VERSION "created by canmatrix"

NS_ :

BS_:

BU_: DiagTool_OBD1 DiwaNXT EBS IRCS MulticII NBM VCM ETS NODE_45 FCCU DICO SGW2 HV_BOX ADCU AEBS DTCO MBMS SGW TPMS ACU CAID2 ELC5_Fr ELC5_Rr PredictiveVirtualNode2 BPU_3 Servo_dir_Turolla PCM NODE_90 NODE_91 NODE_92 RSRRM FCU DSE_VirtualNode2 DSE_VirtualNode40 DSE_VirtualNode38 DSE_VirtualNode49 DSE_VirtualNode48 DSE_VirtualNode39 DSE_VirtualNode37 DSE_VirtualNode36 BSM_B8 BPU_2 DSE_VirtualNode35 DSE_VirtualNode34 RADAR_ACC DSE_VirtualNode33 DSE_VirtualNode41 NODE_BE DSE_VirtualNode32 DSE_VirtualNode4 BSM_C0 BPU_1 DSE_VirtualNode31 DSE_VirtualNode29 DSE_VirtualNode28 MCDS DSE_VirtualNode44 DSE_VirtualNode27 DSE_VirtualNode26 BSM_C8 ALM DSE_VirtualNode25 DSE_VirtualNode50 DSE_VirtualNode47 DSE_VirtualNode46 DSE_VirtualNode23 DSE_VirtualNode51 ScanTool DSE_VirtualNode22 DSE_VirtualNode21 AePTO DC_VirtualNode1 DSE_VirtualNode43 MCSL DSE_VirtualNode1 DSE_VirtualNode42 PredictiveVirtualNode3 DSE_VirtualNode20 DSE_VirtualNode19 DSE_VirtualNode18 DSE_VirtualNode17 DSE_VirtualNode16 DSE_VirtualNode15 NODE_F9 DiagTool DSE_VirtualNode14 DSE_VirtualNode13 DSE_VirtualNode12 DSE_VirtualNode11 DSE_VirtualNode10 DSE_VirtualNode9 DSE_VirtualNode8 DSE_VirtualNode7 DSE_VirtualNode6 Mirror DSE_VirtualNode5 SAS DC_VirtualNode2 PredictiveVirtualNode1 DSE_VirtualNode45 ELFA3 EM_PTO RM CANAIR SWI

BO_ 2364540032 EEC1_H_80: 8 HV_BOX
 SG_ ActEngPcTrq_0CF00480 : 16|8@1+ (1,-125) [-125|125] "%"  PCM
 SG_ EngSpeed_0CF00480 : 24|16@1+ (0.125,0) [0|8031] "rpm"  PCM

BO_ 2566767127 EEC14_17: 8 MulticII
 SG_ FuelType : 48|8@1+ (1,0) [0|255] ""  PCM

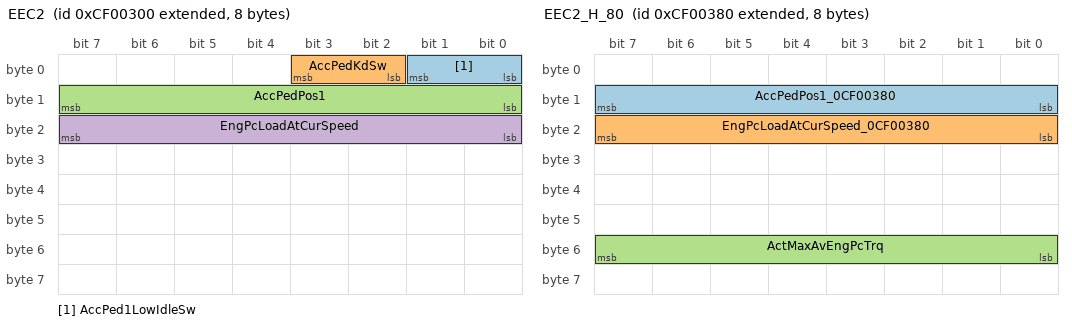
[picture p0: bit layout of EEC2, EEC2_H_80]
BO_ 2364539648 EEC2: 8 DiagTool_OBD1
 SG_ AccPed1LowIdleSw : 0|2@1+ (1,0) [0|3] ""  PCM
 SG_ AccPedKdSw : 2|2@1+ (1,0) [0|3] ""  PCM
 SG_ AccPedPos1 : 8|8@1+ (0.4,0) [0|100] "%"  PCM
 SG_ EngPcLoadAtCurSpeed : 16|8@1+ (1,0) [0|250] "%"  PCM

BO_ 2364539776 EEC2_H_80: 8 HV_BOX
 SG_ AccPedPos1_0CF00380 : 8|8@1+ (0.4,0) [0|100] "%"  PCM
 SG_ EngPcLoadAtCurSpeed_0CF00380 : 16|8@1+ (1,0) [0|250] "%"  PCM
 SG_ ActMaxAvEngPcTrq : 48|8@1+ (0.4,0) [0|100] "%"  PCM

BO_ 2566840064 EEC3: 8 DiagTool_OBD1
 SG_ NomFrictPcTrq : 0|8@1+ (1,-125) [-125|125] "%"  PCM

BO_ 2566840192 EEC3_H: 8 HV_BOX
 SG_ NomFrictPcTrq_18FEDF80 : 0|8@1+ (1,-125) [-125|125] "%"  PCM

BO_ 2566844160 EFLP1: 8 DiagTool_OBD1
 SG_ EngFuelDelPrs : 0|8@1+ (4,0) [0|1000] "kPa"  PCM
 SG_ EngOilPrs1 : 24|8@1+ (4,0) [0|1000] "kPa"  PCM

BO_ 2566885210 ELFASys1_ELFA2: 8 DICO
 SG_ Modefb : 4|4@1+ (1,0) [0|3] ""  PCM

BO_ 2566898290 EmCmd: 8 EM_PTO
 SG_ EngStopSw : 18|2@1+ (1,0) [0|3] ""  PCM

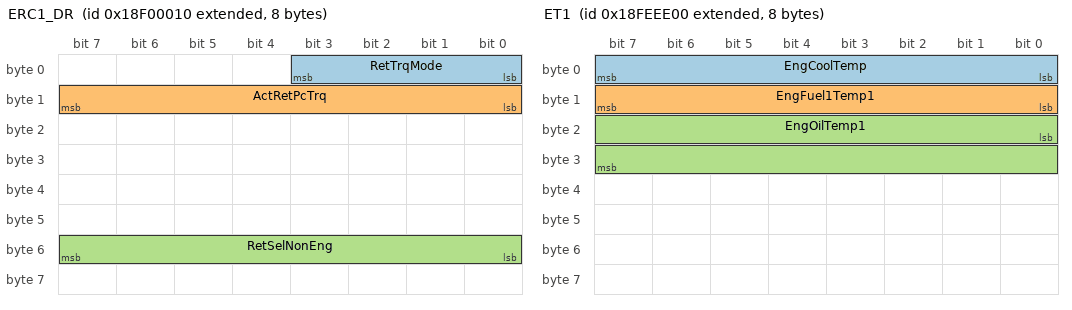
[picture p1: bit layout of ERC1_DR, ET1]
BO_ 2565865488 ERC1_DR: 8 IRCS
 SG_ RetTrqMode : 0|4@1+ (1,0) [0|15] ""  PCM
 SG_ ActRetPcTrq : 8|8@1+ (1,-125) [-125|125] "%"  PCM
 SG_ RetSelNonEng : 48|8@1+ (0.4,0) [0|100] "%"  PCM

BO_ 2565865487 ERC1_ER: 8 RM
 SG_ ActRetPcTrq_18F0000F : 8|8@1+ (1,-125) [-125|125] "%"  PCM

BO_ 2566843904 ET1: 8 DiagTool_OBD1
 SG_ EngCoolTemp : 0|8@1+ (1,-40) [-40|210] "°C"  PCM
 SG_ EngFuel1Temp1 : 8|8@1+ (1,-40) [-40|210] "°C"  PCM
 SG_ EngOilTemp1 : 16|16@1+ (0.03125,-273) [-273|1734] "°C"  PCM

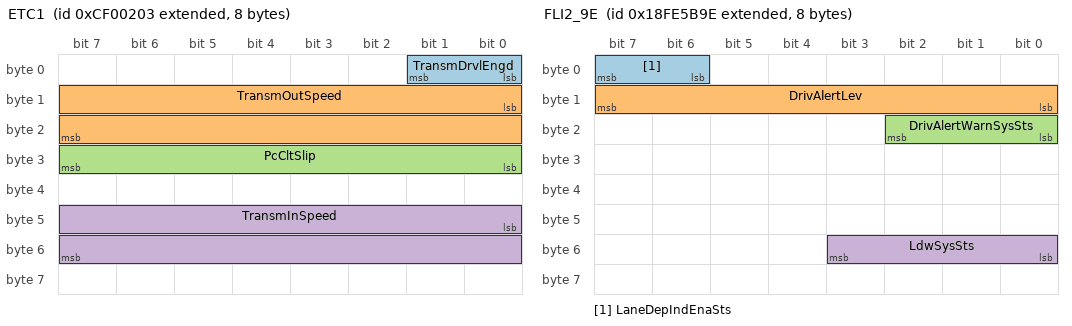
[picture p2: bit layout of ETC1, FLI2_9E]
BO_ 2364539395 ETC1: 8 DiwaNXT
 SG_ TransmDrvlEngd : 0|2@1+ (1,0) [0|3] ""  PCM
 SG_ TransmOutSpeed : 8|16@1+ (0.125,0) [0|8031] "rpm"  PCM
 SG_ PcCltSlip : 24|8@1+ (0.4,0) [0|100] "%"  PCM
 SG_ TransmInSpeed : 40|16@1+ (0.125,0) [0|8031] "rpm"  PCM

BO_ 2565866755 ETC2: 8 DiwaNXT
 SG_ TransmSelGear : 0|8@1+ (1,-125) [-125|125] "gear value"  PCM
 SG_ TransmCurGear : 24|8@1+ (1,-125) [-125|125] "gear value"  PCM

BO_ 2566826755 ETC6_P6: 8 DiwaNXT
 SG_ HighPossGear : 8|8@1+ (1,-125) [-125|125] "gear value"  PCM
 SG_ LowPossGear : 16|8@1+ (1,-125) [-125|125] "gear value"  PCM

BO_ 2364541955 ETC8: 8 DiwaNXT
 SG_ TransmTrqConvRatio : 0|16@1+ (0.001,0) [0|64] ""  PCM

BO_ 2566831393 FD1_21: 8 NBM
 SG_ FanSpeed : 16|16@1+ (0.125,0) [0|8031] "rpm"  PCM

BO_ 2431649694 FLI1_9E: 8 ADCU
 SG_ LaneDepImmRh : 4|2@1+ (1,0) [0|3] ""  PCM
 SG_ LaneDepImmLh : 6|2@1+ (1,0) [0|3] ""  PCM

BO_ 2566806430 FLI2_9E: 8 ADCU
 SG_ LaneDepIndEnaSts : 6|2@1+ (1,0) [0|3] ""  PCM
 SG_ DrivAlertLev : 8|8@1+ (0.4,0) [0|100] "%"  PCM
 SG_ DrivAlertWarnSysSts : 16|3@1+ (1,0) [0|7] ""  PCM
 SG_ LdwSysSts : 48|4@1+ (1,0) [0|15] ""  PCM

BO_ 2566841600 HOURS: 8 DiagTool_OBD1
 SG_ EngTotHrOfOp : 0|32@1+ (0.05,0) [0|210554060] "h"  PCM

BO_ 2566719744 HRLFC: 8 DiagTool_OBD1
 SG_ EngTotFuelUsedHr : 32|32@1+ (0.001,0) [0|4211081] "L"  PCM

BO_ 2566837793 HSI1_21: 8 NBM
 SG_ HybSysPwrElnCoolLevSw : 4|2@1+ (1,0) [0|3] ""  PCM
 SG_ HybSysCoastRegenBrkLevSel : 16|8@1+ (0.4,0) [0|100] "%"  PCM

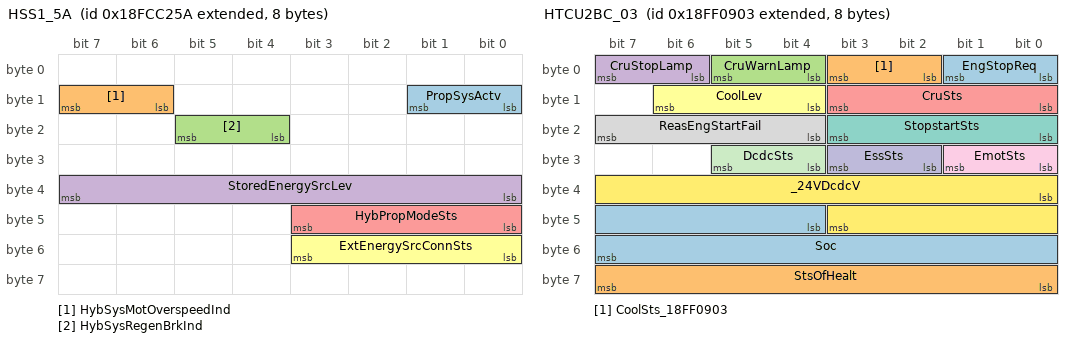
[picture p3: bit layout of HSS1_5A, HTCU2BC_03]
BO_ 2566701658 HSS1_5A: 8 DICO
 SG_ PropSysActv : 8|2@1+ (1,0) [0|3] ""  PCM
 SG_ HybSysMotOverspeedInd : 14|2@1+ (1,0) [0|3] ""  PCM
 SG_ HybSysRegenBrkInd : 20|2@1+ (1,0) [0|3] ""  PCM
 SG_ StoredEnergySrcLev : 32|8@1+ (0.4,0) [0|100] "%"  PCM
 SG_ HybPropModeSts : 40|4@1+ (1,0) [0|15] ""  PCM
 SG_ ExtEnergySrcConnSts : 48|4@1+ (1,0) [0|15] ""  PCM

BO_ 2566698842 HSS2_5A: 8 DICO
 SG_ HybBatRemChg : 0|16@1+ (0.0025,0) [0|160] "%"  PCM
 SG_ HybSysEassRemPc : 16|8@1+ (0.4,0) [0|100] "%"  PCM

BO_ 2566850819 HTCU2BC_03: 8 DiwaNXT
 SG_ EngStopReq : 0|2@1+ (1,0) [0|3] ""  PCM
 SG_ CoolSts_18FF0903 : 2|2@1+ (1,0) [0|3] ""  PCM
 SG_ CruWarnLamp : 4|2@1+ (1,0) [0|3] ""  PCM
 SG_ CruStopLamp : 6|2@1+ (1,0) [0|3] ""  PCM
 SG_ CruSts : 8|4@1+ (1,0) [0|15] "Status"  PCM
 SG_ CoolLev : 12|3@1+ (1,0) [0|7] "Status"  PCM
 SG_ StopstartSts : 16|4@1+ (1,0) [0|15] ""  PCM
 SG_ ReasEngStartFail : 20|4@1+ (1,0) [0|15] ""  PCM
 SG_ EmotSts : 24|2@1+ (1,0) [0|3] ""  PCM
 SG_ EssSts : 26|2@1+ (1,0) [0|3] ""  PCM
 SG_ DcdcSts : 28|2@1+ (1,0) [0|3] "Status"  PCM
 SG_ _24VDcdcV : 32|12@1+ (0.025,0) [0|100] "V"  PCM
 SG_ Soc : 44|12@1+ (0.1,-200) [-200|209] "%"  PCM
 SG_ StsOfHealt : 56|8@1+ (0.5,0) [0|100] "%"  PCM

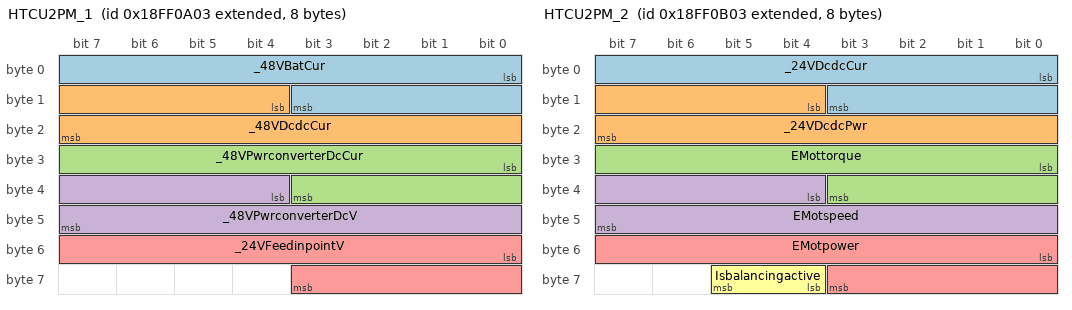
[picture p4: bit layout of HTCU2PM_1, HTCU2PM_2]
BO_ 2566851075 HTCU2PM_1: 8 DiwaNXT
 SG_ _48VBatCur : 0|12@1+ (0.5,-1000) [-1000|1007] "A"  PCM
 SG_ _48VDcdcCur : 12|12@1+ (0.5,-1000) [-1000|1007] "A"  PCM
 SG_ _48VPwrconverterDcCur : 24|12@1+ (0.5,-1000) [-1000|1007] "A"  PCM
 SG_ _48VPwrconverterDcV : 36|12@1+ (0.025,0) [0|100] "V"  PCM
 SG_ _24VFeedinpointV : 48|12@1+ (0.025,0) [0|100] "V"  PCM

BO_ 2566851331 HTCU2PM_2: 8 DiwaNXT
 SG_ _24VDcdcCur : 0|12@1+ (0.5,-1000) [-1000|1007] "A"  PCM
 SG_ _24VDcdcPwr : 12|12@1+ (25,-50000) [-50000|52375] "W"  PCM
 SG_ EMottorque : 24|12@1+ (0.2,-400) [-400|403] "Nm"  PCM
 SG_ EMotspeed : 36|12@1+ (1,-500) [-500|3515] "rpm"  PCM
 SG_ EMotpower : 48|12@1+ (25,-50000) [-50000|52375] "12"  PCM
 SG_ Isbalancingactive : 60|2@1+ (1,0) [0|3] ""  PCM

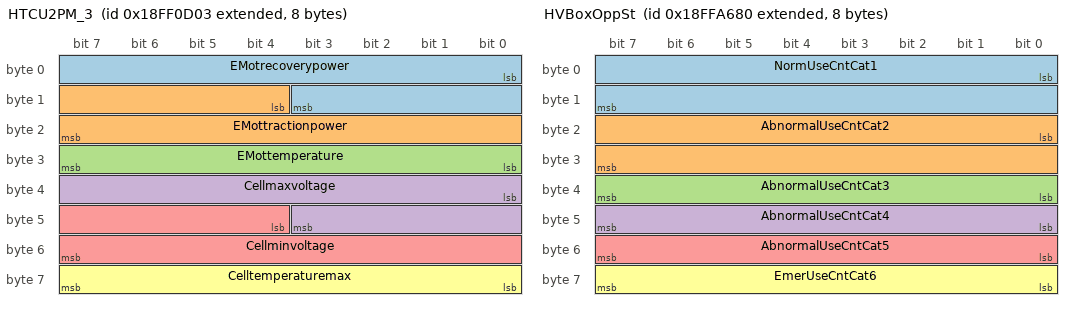
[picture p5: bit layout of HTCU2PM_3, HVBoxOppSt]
BO_ 2566851843 HTCU2PM_3: 8 DiwaNXT
 SG_ EMotrecoverypower : 0|12@1+ (25,-50000) [-50000|52375] "W"  PCM
 SG_ EMottractionpower : 12|12@1+ (25,-50000) [-50000|52375] "W"  PCM
 SG_ EMottemperature : 24|8@1+ (1,-40) [-40|210] "°C"  PCM
 SG_ Cellmaxvoltage : 32|12@1+ (0.002,0) [0|8] "V"  PCM
 SG_ Cellminvoltage : 44|12@1+ (0.002,0) [0|8] "V"  PCM
 SG_ Celltemperaturemax : 56|8@1+ (1,-40) [-40|210] "°C"  PCM

BO_ 2566891136 HVBoxOppSt: 8 HV_BOX
 SG_ NormUseCntCat1 : 0|16@1+ (5,0) [0|321275] "count"  PCM
 SG_ AbnormalUseCntCat2 : 16|16@1+ (2,0) [0|128510] "count"  PCM
 SG_ AbnormalUseCntCat3 : 32|8@1+ (200,0) [0|50000] "count"  PCM
 SG_ AbnormalUseCntCat4 : 40|8@1+ (5,0) [0|1250] "count"  PCM
 SG_ AbnormalUseCntCat5 : 48|8@1+ (1,0) [0|250] "count"  PCM
 SG_ EmerUseCntCat6 : 56|8@1+ (1,0) [0|250] "count"  PCM

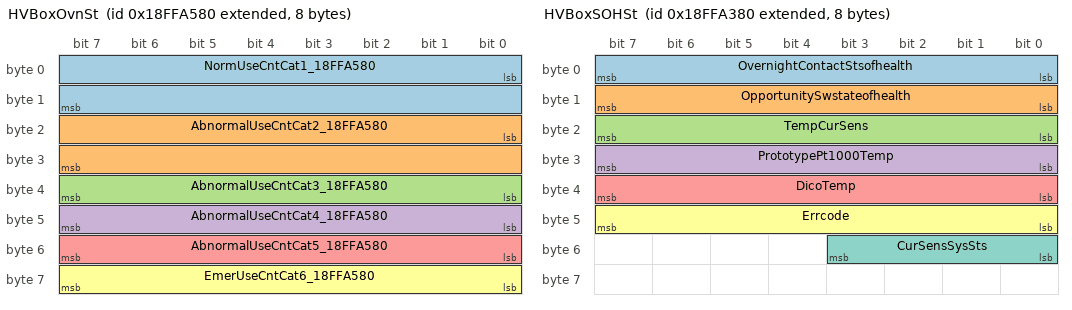
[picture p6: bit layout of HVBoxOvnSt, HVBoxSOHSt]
BO_ 2566890880 HVBoxOvnSt: 8 HV_BOX
 SG_ NormUseCntCat1_18FFA580 : 0|16@1+ (5,0) [0|321275] "count"  PCM
 SG_ AbnormalUseCntCat2_18FFA580 : 16|16@1+ (2,0) [0|128510] "count"  PCM
 SG_ AbnormalUseCntCat3_18FFA580 : 32|8@1+ (200,0) [0|50000] "count"  PCM
 SG_ AbnormalUseCntCat4_18FFA580 : 40|8@1+ (5,0) [0|1250] "count"  PCM
 SG_ AbnormalUseCntCat5_18FFA580 : 48|8@1+ (1,0) [0|250] "count"  PCM
 SG_ EmerUseCntCat6_18FFA580 : 56|8@1+ (1,0) [0|250] "count"  PCM

BO_ 2566890368 HVBoxSOHSt: 8 HV_BOX
 SG_ OvernightContactStsofhealth : 0|8@1+ (0.4,0) [0|100] "%"  PCM
 SG_ OpportunitySwstateofhealth : 8|8@1+ (0.4,0) [0|100] "%"  PCM
 SG_ TempCurSens : 16|8@1+ (1,-40) [-40|80] "° C"  PCM
 SG_ PrototypePt1000Temp : 24|8@1+ (1,-40) [-40|120] "° C"  PCM
 SG_ DicoTemp : 32|8@1+ (1,-40) [-40|120] "° C"  PCM
 SG_ Errcode : 40|8@1+ (1,0) [0|250] ""  PCM
 SG_ CurSensSysSts : 48|4@1+ (1,0) [0|15] ""  PCM

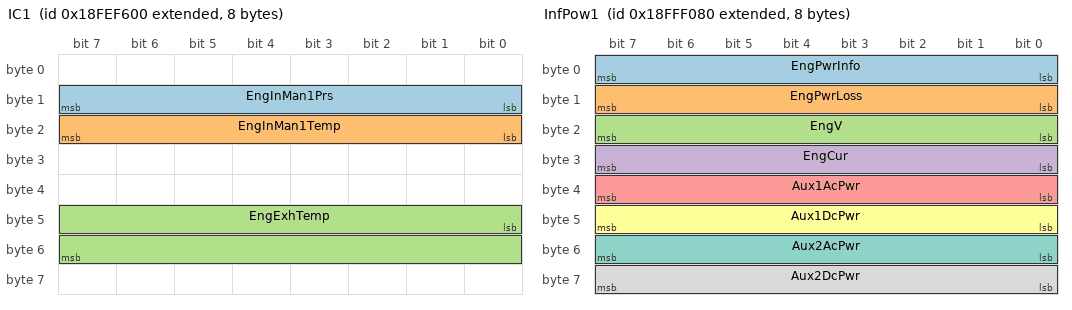
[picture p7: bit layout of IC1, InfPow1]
BO_ 2566845952 IC1: 8 DiagTool_OBD1
 SG_ EngInMan1Prs : 8|8@1+ (2,0) [0|500] "kPa"  PCM
 SG_ EngInMan1Temp : 16|8@1+ (1,-40) [-40|210] "°C"  PCM
 SG_ EngExhTemp : 40|16@1+ (0.03125,-273) [-273|1734] "°C"  PCM

BO_ 2566910080 InfPow1: 8 HV_BOX
 SG_ EngPwrInfo : 0|8@1+ (4,-500) [-500|500] "KW"  PCM
 SG_ EngPwrLoss : 8|8@1+ (0.2,0) [0|50] "KW"  PCM
 SG_ EngV : 16|8@1+ (3.4,0) [0|850] "V"  PCM
 SG_ EngCur : 24|8@1+ (4,-500) [-500|500] "A"  PCM
 SG_ Aux1AcPwr : 32|8@1+ (0.2,0) [0|50] "KW"  PCM
 SG_ Aux1DcPwr : 40|8@1+ (0.2,0) [0|50] "KW"  PCM
 SG_ Aux2AcPwr : 48|8@1+ (0.2,0) [0|50] "KW"  PCM
 SG_ Aux2DcPwr : 56|8@1+ (0.2,0) [0|50] "KW"  PCM

BO_ 2566909824 InfPow2: 8 HV_BOX
 SG_ HighVEnergyChgdTot : 0|32@1+ (0.1,0) [0|199999999] "KWh"  PCM

BO_ 2566786839 LC_17: 8 MulticII
 SG_ LangCodeCmd : 0|16@1+ (1,0) [0|65535] "ASCII"  PCM

BO_ 2566842624 LFC: 8 DiagTool_OBD1
 SG_ EngTotFuelUsed : 32|32@1+ (0.5,0) [0|2105540607] "L"  PCM

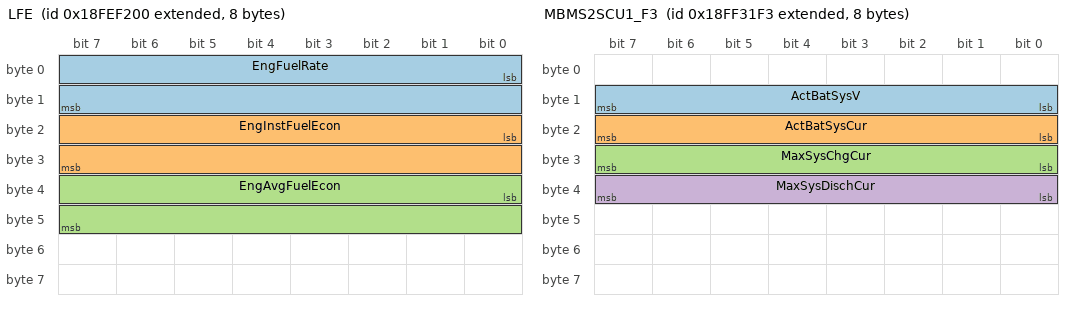
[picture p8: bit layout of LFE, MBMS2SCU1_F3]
BO_ 2566844928 LFE: 8 DiagTool_OBD1
 SG_ EngFuelRate : 0|16@1+ (0.05,0) [0|3212] "L/h"  PCM
 SG_ EngInstFuelEcon : 16|16@1+ (0.001953125,0) [0|125] "km/L"  PCM
 SG_ EngAvgFuelEcon : 32|16@1+ (0.001953125,0) [0|125] "km/L"  PCM

BO_ 2566861299 MBMS2SCU1_F3: 8 MBMS
 SG_ ActBatSysV : 8|8@1+ (3.4,0) [0|850] "V"  PCM
 SG_ ActBatSysCur : 16|8@1+ (4,-500) [-500|500] "A"  PCM
 SG_ MaxSysChgCur : 24|8@1+ (3,0) [0|750] "A"  PCM
 SG_ MaxSysDischCur : 32|8@1+ (3,0) [0|750] "A"  PCM

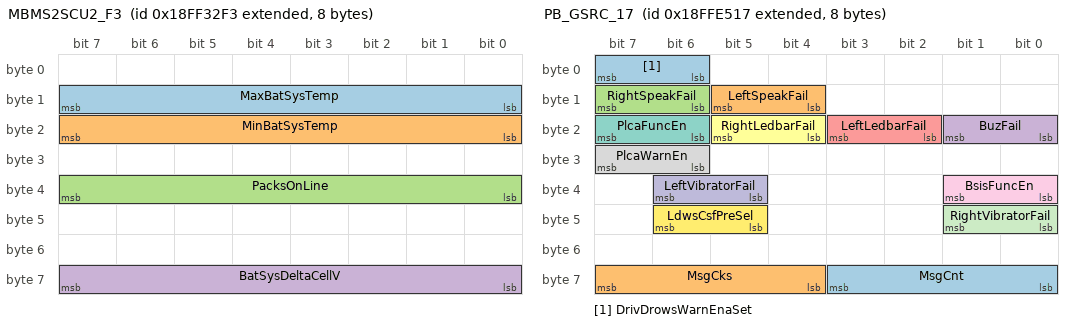
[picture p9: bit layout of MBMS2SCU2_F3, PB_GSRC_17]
BO_ 2566861555 MBMS2SCU2_F3: 8 MBMS
 SG_ MaxBatSysTemp : 8|8@1+ (1,-40) [-40|210] "°C"  PCM
 SG_ MinBatSysTemp : 16|8@1+ (1,-40) [-40|210] "°C"  PCM
 SG_ PacksOnLine : 32|8@1+ (1,0) [0|250] "pack"  PCM
 SG_ BatSysDeltaCellV : 56|8@1+ (10,0) [0|2500] "Mv"  PCM

BO_ 2566776097 MVS_21: 8 NBM
 SG_ MaxVsl1 : 0|8@1+ (1,0) [0|250] "km/h"  PCM
 SG_ AppliedVsl : 56|8@1+ (1,0) [0|250] "km/h"  PCM

BO_ 2365443105 OEL: 8 NBM
 SG_ TurnSigSw : 8|4@1+ (1,0) [0|15] ""  PCM

BO_ 2566769953 OWW_21: 8 NBM
 SG_ FrontOpWiperSw : 4|4@1+ (1,0) [0|15] ""  PCM
 SG_ FrontOpWasherSw : 45|3@1+ (1,0) [0|7] ""  PCM

BO_ 2566908574 PB_AIDI_9E: 8 ADCU
 SG_ DrowsDrivLev : 3|3@1+ (1,0) [0|7] ""  PCM
 SG_ DdawRunMode : 8|3@1+ (1,0) [0|7] ""  PCM

BO_ 2566907159 PB_GSRC_17: 8 MulticII
 SG_ DrivDrowsWarnEnaSet : 6|2@1+ (1,0) [0|3] ""  PCM
 SG_ LeftSpeakFail : 12|2@1+ (1,0) [0|3] ""  PCM
 SG_ RightSpeakFail : 14|2@1+ (1,0) [0|3] ""  PCM
 SG_ BuzFail : 16|2@1+ (1,0) [0|3] ""  PCM
 SG_ LeftLedbarFail : 18|2@1+ (1,0) [0|3] ""  PCM
 SG_ RightLedbarFail : 20|2@1+ (1,0) [0|3] ""  PCM
 SG_ PlcaFuncEn : 22|2@1+ (1,0) [0|3] ""  PCM
 SG_ PlcaWarnEn : 30|2@1+ (1,0) [0|3] ""  PCM
 SG_ BsisFuncEn : 32|2@1+ (1,0) [0|3] ""  PCM
 SG_ LeftVibratorFail : 37|2@1+ (1,0) [0|3] ""  PCM
 SG_ RightVibratorFail : 40|2@1+ (1,0) [0|3] ""  PCM
 SG_ LdwsCsfPreSel : 45|2@1+ (1,0) [0|3] ""  PCM
 SG_ MsgCnt : 56|4@1+ (1,0) [0|15] "count"  PCM
 SG_ MsgCks : 60|4@1+ (1,0) [0|15] "count"  PCM

BO_ 2566894871 PB_ISA_17: 8 MulticII
 SG_ IntlSpeedAssantActv : 8|3@1+ (1,0) [0|7] ""  PCM
 SG_ CntryCode : 22|10@1+ (1,0) [0|1023] ""  PCM

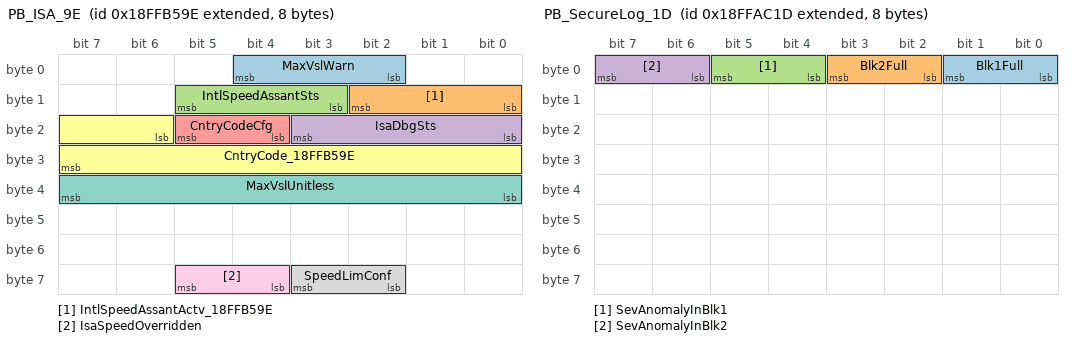
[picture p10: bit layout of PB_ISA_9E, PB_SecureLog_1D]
BO_ 2566895006 PB_ISA_9E: 8 ADCU
 SG_ MaxVslWarn : 2|3@1+ (1,0) [0|3] ""  PCM
 SG_ IntlSpeedAssantActv_18FFB59E : 8|3@1+ (1,0) [0|7] ""  PCM
 SG_ IntlSpeedAssantSts : 11|3@1+ (1,0) [0|7] ""  PCM
 SG_ IsaDbgSts : 16|4@1+ (1,1) [0|15] ""  PCM
 SG_ CntryCodeCfg : 20|2@1+ (1,0) [0|3] ""  PCM
 SG_ CntryCode_18FFB59E : 22|10@1+ (1,0) [0|1023] ""  PCM
 SG_ MaxVslUnitless : 32|8@1+ (1,0) [0|140] ""  PCM
 SG_ SpeedLimConf : 58|2@1+ (1,0) [0|3] ""  PCM
 SG_ IsaSpeedOverridden : 60|2@1+ (1,0) [0|3] ""  PCM

BO_ 2365575713 PB_NmM: 8 NBM
 SG_ IgnOn : 4|2@1+ (1,0) [0|3] ""  PCM

BO_ 2566892573 PB_SecureLog_1D: 8 SGW
 SG_ Blk1Full : 0|2@1+ (1,0) [0|3] ""  PCM
 SG_ Blk2Full : 2|2@1+ (1,0) [0|3] ""  PCM
 SG_ SevAnomalyInBlk1 : 4|2@1+ (1,0) [0|3] ""  PCM
 SG_ SevAnomalyInBlk2 : 6|2@1+ (1,0) [0|3] ""  PCM

BO_ 2566892618 PB_SecureLog_4A: 8 PCM
 SG_ WarnRx : 8|2@1+ (1,0) [0|3] "" Vector__XXX

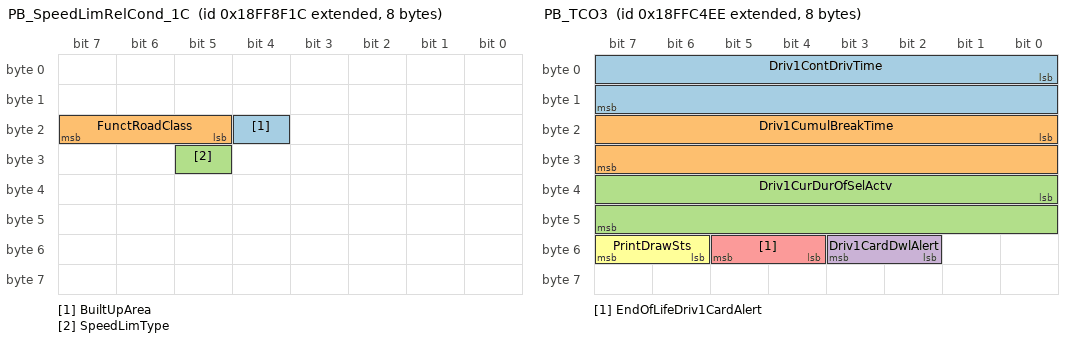
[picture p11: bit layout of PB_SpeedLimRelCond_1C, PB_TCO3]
BO_ 2566885148 PB_SpeedLimRelCond_1C: 8 PCM
 SG_ BuiltUpArea : 20|1@0+ (1,0) [0|1] "" Vector__XXX
 SG_ FunctRoadClass : 23|3@0+ (1,0) [0|7] "" Vector__XXX
 SG_ SpeedLimType : 29|1@0+ (1,0) [0|1] "" Vector__XXX

BO_ 2566898670 PB_TCO2: 21 DTCO
 SG_ Driv1Id_18FFC3EE : 0|8@1+ (1,0) [0|255] "ASCII"  PCM
 SG_ PrefLang : 112|16@1+ (1,0) [0|255] "ASCII"  PCM
 SG_ NextCalDateDay : 128|8@1+ (0.25,0) [0|31] "day"  PCM
 SG_ NextCalDateMonth : 136|8@1+ (1,0) [1|12] "month"  PCM
 SG_ NextCalDateYr : 144|8@1+ (1,1985) [1985|2235] "year"  PCM
 SG_ WFact : 152|16@1+ (0.001,0) [2|25] "pulse/m"  PCM

BO_ 2566898926 PB_TCO3: 8 DTCO
 SG_ Driv1ContDrivTime : 0|16@1+ (1,0) [0|64255] "min"  PCM
 SG_ Driv1CumulBreakTime : 16|16@1+ (1,0) [0|64255] "min"  PCM
 SG_ Driv1CurDurOfSelActv : 32|16@1+ (1,0) [0|64255] "min"  PCM
 SG_ Driv1CardDwlAlert : 50|2@1+ (1,0) [0|3] ""  PCM
 SG_ EndOfLifeDriv1CardAlert : 52|2@1+ (1,0) [0|3] ""  PCM
 SG_ PrintDrawSts : 54|2@1+ (1,0) [0|3] ""  PCM

BO_ 2566899694 PB_TCO4: 44 DTCO
 SG_ TwoWeeksTotDrivTime : 0|16@1+ (1,0) [0|64255] "min"  PCM
 SG_ WeekTotDrivTime : 16|16@1+ (1,0) [0|64255] "min"  PCM
 SG_ DayDrivTime : 32|15@1+ (1,0) [0|31487] "min"  PCM
 SG_ DayDrivTimeFlag : 47|1@1+ (1,0) [0|1] ""  PCM
 SG_ DayDrivTimeShift1 : 48|15@1+ (1,0) [0|31487] "min"  PCM
 SG_ DayDrivTimeShift1Flag : 63|1@1+ (1,0) [0|1] ""  PCM
 SG_ DayDrivTimeShift2 : 64|15@1+ (1,0) [0|31487] "min"  PCM
 SG_ DayDrivTimeShift2Flag : 79|1@1+ (1,0) [0|1] ""  PCM
 SG_ DayDrivTimeShift3 : 80|15@1+ (1,0) [0|31487] "min"  PCM
 SG_ DayDrivTimeShift3Flag : 95|1@1+ (1,0) [0|1] ""  PCM
 SG_ DayDrivTimeShift4 : 96|15@1+ (1,0) [0|31487] "min"  PCM
 SG_ DayDrivTimeShift4Flag : 111|1@1+ (1,0) [0|1] ""  PCM
 SG_ DayDrivTimeShift5 : 112|15@1+ (1,0) [0|31487] "min"  PCM
 SG_ DayDrivTimeShift5Flag : 127|1@1+ (1,0) [0|1] ""  PCM
 SG_ DayDrivTimeShift6 : 128|15@1+ (1,0) [0|31487] "min"  PCM
 SG_ DayDrivTimeShift6Flag : 143|1@1+ (1,0) [0|1] ""  PCM
 SG_ DayRestPer1 : 144|15@1+ (1,0) [0|31487] "min"  PCM
 SG_ DayRestPer1Flag : 159|1@1+ (1,0) [0|1] ""  PCM
 SG_ DayRestPer2 : 160|15@1+ (1,0) [0|31487] "min"  PCM
 SG_ DayRestPer2Flag : 175|1@1+ (1,0) [0|1] ""  PCM
 SG_ DayRestPer3 : 176|15@1+ (1,0) [0|31487] "min"  PCM
 SG_ DayRestPer3Flag : 191|1@1+ (1,0) [0|1] ""  PCM
 SG_ DayRestPer4 : 192|15@1+ (1,0) [0|31487] "min"  PCM
 SG_ DayRestPer4Flag : 207|1@1+ (1,0) [0|1] ""  PCM
 SG_ DayRestPer5 : 208|15@1+ (1,0) [0|31487] "min"  PCM
 SG_ DayRestPer5Flag : 223|1@1+ (1,0) [0|1] ""  PCM
 SG_ DayRestPer6 : 224|15@1+ (1,0) [0|31487] "min"  PCM
 SG_ DayRestPer6Flag : 239|1@1+ (1,0) [0|1] ""  PCM
 SG_ DayRestPer7 : 240|15@1+ (1,0) [0|31487] "min"  PCM
 SG_ DayRestPer7Flag : 255|1@1+ (1,0) [0|1] ""  PCM
 SG_ DayOdo : 256|16@1+ (1,0) [0|64255] "km"  PCM
 SG_ WeekTotOdo : 272|16@1+ (1,0) [0|64255] "km"  PCM
 SG_ TwoWeeksTotOdo : 288|16@1+ (1,0) [0|64255] "km"  PCM
 SG_ DrivCnt : 304|16@1+ (1,0) [0|64255] "min"  PCM
 SG_ WorkCnt : 320|16@1+ (1,0) [0|64255] "min"  PCM
 SG_ AvCnt : 336|16@1+ (1,0) [0|64255] "min"  PCM

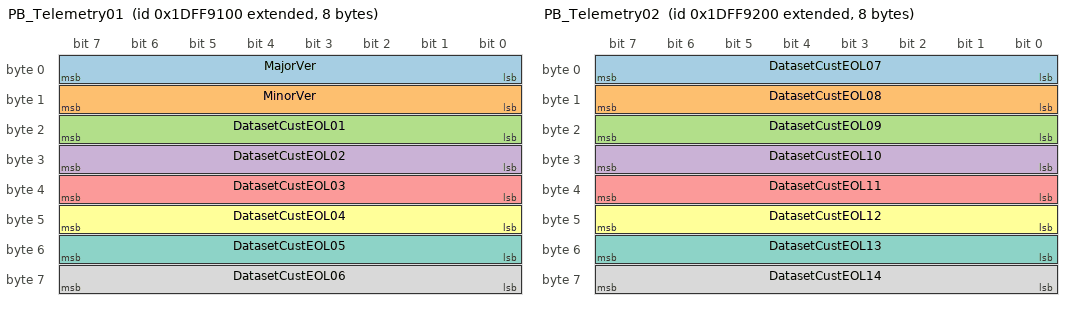
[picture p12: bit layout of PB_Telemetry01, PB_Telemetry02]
BO_ 2650771712 PB_Telemetry01: 8 DiagTool_OBD1
 SG_ MajorVer : 0|8@1+ (1,0) [0|255] ""  PCM
 SG_ MinorVer : 8|8@1+ (1,0) [0|255] ""  PCM
 SG_ DatasetCustEOL01 : 16|8@1+ (1,0) [0|255] ""  PCM
 SG_ DatasetCustEOL02 : 24|8@1+ (1,0) [0|255] ""  PCM
 SG_ DatasetCustEOL03 : 32|8@1+ (1,0) [0|255] ""  PCM
 SG_ DatasetCustEOL04 : 40|8@1+ (1,0) [0|255] ""  PCM
 SG_ DatasetCustEOL05 : 48|8@1+ (1,0) [0|255] ""  PCM
 SG_ DatasetCustEOL06 : 56|8@1+ (1,0) [0|255] ""  PCM

BO_ 2650771968 PB_Telemetry02: 8 DiagTool_OBD1
 SG_ DatasetCustEOL07 : 0|8@1+ (1,0) [0|255] ""  PCM
 SG_ DatasetCustEOL08 : 8|8@1+ (1,0) [0|255] ""  PCM
 SG_ DatasetCustEOL09 : 16|8@1+ (1,0) [0|255] ""  PCM
 SG_ DatasetCustEOL10 : 24|8@1+ (1,0) [0|255] ""  PCM
 SG_ DatasetCustEOL11 : 32|8@1+ (1,0) [0|255] ""  PCM
 SG_ DatasetCustEOL12 : 40|8@1+ (1,0) [0|255] ""  PCM
 SG_ DatasetCustEOL13 : 48|8@1+ (1,0) [0|255] ""  PCM
 SG_ DatasetCustEOL14 : 56|8@1+ (1,0) [0|255] ""  PCM

CM_ BO_ 2364540032 "- Timeout (ms): 50 ms / -
- MC.A.VCU..24..VDB: Only Gx (ELFA2)_
- PCM.Si.DICO....Traction: 10ms in messagerie ELFA2";
CM_ BO_ 2364539648 "- ICE bus only";
CM_ BO_ 2364539776 "- Full elec Siemens only";
CM_ SG_ 2364539776 AccPedPos1_0CF00380 "- UW: recopy of information in EEC2 (0C F0 03 00)";
CM_ BO_ 2566840064 "- Diesel / Gas only";
CM_ BO_ 2566840192 "- Siemens Full elec only. 200ms in messagerie ELFA3 _ 250ms in messagerie BAE.";
CM_ SG_ 2566844160 EngFuelDelPrs "- GAZ only. To be added into VCM4 VDB";
CM_ SG_ 2566844160 EngOilPrs1 "- FEh in case of defective sensor";
CM_ BO_ 2566885210 "- Specific to Siemens Full Elec vehicles. Only Elfa2.";
CM_ BO_ 2566898290 "- CNG and MH only
- MC.W.VCM.4.24..VDB: Transmission rate: ''As Needed''";
CM_ SG_ 2566898290 EngStopSw "- BC.A.BCM..24.UwDG.VDB: Gas: one shot 500ms (NBM)";
CM_ BO_ 2565865488 "-  2 Message Variant(s): Transm.Rates 20, 100
-  Specific to Siemens Full Elec vehicles.
-  Read only, no routing on ECB
-  Transmission Rate [ms] 100";
CM_ SG_ 2565865488 RetSelNonEng "- ETC1.ZF.ETC.Ecolife.2..VDB: Not available 0 value (shift selector not connected to the TCU)";
CM_ BO_ 2565865487 "- 1 message instance, SA=0x0F, 0x29, as selected by calibration (Integration Layer)
-  Routing from ERC1_ER";
CM_ SG_ 2566843904 EngCoolTemp "- FEh in case of defective sensor";
CM_ SG_ 2566843904 EngFuel1Temp1 "- FEh in case of defective sensor";
CM_ SG_ 2566843904 EngOilTemp1 "- FE00h in case of defective sensor";
CM_ SG_ 2364539395 TransmOutSpeed "- MC.A.VCU..24..VDB: Only Gx (ELFA2)";
CM_ SG_ 2364539395 PcCltSlip "- CUC.C.PCM..3..TELEM: Optional";
CM_ SG_ 2364539395 TransmInSpeed "- CUC.C.PCM..3..TELEM: Optional";
CM_ BO_ 2565866755 "- All Powertrain except manual transmission.
-  Full elec: J1939 codification, but only D/N/R and +1/0/-1 are used as there is no gearBox).
-  Multi-PG association valid when VCM is the sender of the message. Transmitted when no ETC, received otherwise
- IC1.A.IC.MulticS.24.CwFE.VDB: Update in according with ''OPL_Supermap'' request (line 50).";
CM_ SG_ 2565866755 TransmSelGear "- Negative values are reverse gears, positive values are forward gears, zero is neutral. 251(0xFB) is park
- MC.A.VCU..24..VDB: Only Gx (ELFA2)";
CM_ SG_ 2565866755 TransmCurGear "- Negative values are reverse gears, positive values are forward gears, zero is neutral. 251(0xFB) is park";
CM_ BO_ 2566826755 "- Only with manual transmission. SAE recommanded priority=7";
CM_ SG_ 2566826755 HighPossGear "- At least 3 gears above the maximum possible to indicate Splitter High, 0xFF otherwise";
CM_ SG_ 2566826755 LowPossGear "- At least 3 gears below the maximum possible to indicate Splitter Low, 0xFF otherwise";
CM_ BO_ 2364541955 "- 100ms in case torque converter locked_ 20ms otherwise";
CM_ BO_ 2566831393 "- Only on UW Diesel CNG";
CM_ BO_ 2431649694 "- Fastest transmission rate 50ms when requested / not send when not requested
-  Transmitted when Lane Departure is active and at least once afterwards.";
CM_ BO_ 2566841600 "- All engines available, even if SA=00.
-  Cyclic Transmission Rate as result of PGN requests
-  SGW requests this PGN with RQST_1D_00
- VS2.B.SGW2..23..VDB: Used in freeze frames parameters.";
CM_ BO_ 2566719744 "- Accumulated amount of fuel used during vehicle operation.";
CM_ BO_ 2566837793 "- Specific to Siemens Full Elec vehicles";
CM_ SG_ 2566837793 HybSysCoastRegenBrkLevSel "- Signal name Intercity file: Hybrid System Handlever Retarder";
CM_ BO_ 2566701658 "- Specific to Siemens Full Elec vehicles.
-  Transmision: Now 100ms, previously 1000ms, 100ms on change";
CM_ BO_ 2566698842 "- Specific to Siemens Full Elec vehicles";
CM_ SG_ 2566698842 HybBatRemChg "- Indicates the hybrid battery pack remaining charge. 0% means no charge remaining, 100% means full charge remaining. 0.0025 %/bit _ offset 0 _ 0 to 160.6375 %.";
CM_ BO_ 2566850819 "- Related to Voith Mild Hybrid project";
CM_ BO_ 2566851075 "- Related to Voith Mild Hybrid project
- CUC.C.PCM..3..TELEM: - Predisposal";
CM_ BO_ 2566851331 "- Related to Voith Mild Hybrid project
-  UW Mild Hybrid only";
CM_ BO_ 2566851843 "- Related to Voith Mild Hybrid project";
CM_ BO_ 2566891136 "- Specific to Siemens Full Elec vehicles";
CM_ BO_ 2566890880 "- Specific to Siemens Full Elec vehicles";
CM_ BO_ 2566890368 "- Specific to Siemens Full Elec vehicles. PCM Traction: in according with VCU file";
CM_ SG_ 2566890368 Errcode "- On event: in case of change of the errorCode the message will be send out acyclic.";
CM_ SG_ 2566845952 EngInMan1Prs "- FEh in case of defective sensor";
CM_ SG_ 2566845952 EngInMan1Temp "- FEh in case of defective sensor";
CM_ SG_ 2566845952 EngExhTemp "- FE00h in case of defective sensor";
CM_ BO_ 2566910080 "- Specific to Siemens Full Elec vehicles";
CM_ BO_ 2566909824 "- Specific to Siemens Full Elec vehicles. Predisposal";
CM_ SG_ 2566909824 HighVEnergyChgdTot "- Total energy charged in the high voltage batteries in the vehicle life time";
CM_ SG_ 2566786839 LangCodeCmd "- Uses the 2-character string country codes in ISO 639.";
CM_ BO_ 2566842624 "- All engines sauf Full elec. CAN Engine: Only ''On Request''. Others Cyclic Transmission Rate as result of PGN requests";
CM_ BO_ 2566844928 "- All engines, without Full elec";
CM_ SG_ 2566844928 EngAvgFuelEcon "- Not emitted with C9 CNG";
CM_ BO_ 2566861299 "- Specific to Siemens Full Elec vehicles.
- CLC1.Tk.ACM....VDB: Filled in according with Intercity file";
CM_ BO_ 2566861555 "- Specific to Siemens Full Elec vehicles";
CM_ BO_ 2566776097 "- Specific to Siemens Full Elec vehicles (CW, Gx).";
CM_ BO_ 2365443105 "- ADC.ZF.ADCU..24..VDB: Transmission rate may differ: ADCU VDB: 1000/On change";
CM_ BO_ 2566908574 "- Bus load periodic : 0.13";
CM_ SG_ 2566895006 MaxVslUnitless "- SPN Position Changed";
CM_ SG_ 2566895006 SpeedLimConf "- Only CW
-  SPN Position Changed.";
CM_ BO_ 2566892573 "- Sent 10 times each 2 seconds. SGW will stop the transmission when PB_SecureLog_4A is received";
CM_ BO_ 2566885148 "- Fonction ISA (ADCU requested)";
CM_ BO_ 2566898670 "- Multipacket message handled by SAE Transport Protocol (J1939/21, par 5.10, Multipacket Broadcast with TP.CM/BAM, TP.DT)
-  Update filled in acc with DTCO4.1 (New file).";
CM_ SG_ 2566898670 Driv1Id_18FFC3EE "- Signal length 112 bits (14 ASCII chars)";
CM_ BO_ 2566898926 "- Update filled in acc with DTCO4.1 (New file).";
CM_ SG_ 2566898926 Driv1CardDwlAlert "- Driver1 - additional information";
CM_ SG_ 2566898926 EndOfLifeDriv1CardAlert "- Driver1 - additional information";
CM_ SG_ 2566898926 PrintDrawSts "- Driver1 - additional information";
CM_ BO_ 2566899694 "- Update filled in acc with DTCO4.1 (New file).";
CM_ SG_ 2566899694 DayDrivTimeFlag "- 1b also when the info is Not Available";
CM_ SG_ 2566899694 DayDrivTimeShift1Flag "- 1b also when the info is Not Available";
CM_ SG_ 2566899694 DayDrivTimeShift2Flag "- 1b also when the info is Not Available";
CM_ SG_ 2566899694 DayDrivTimeShift3Flag "- 1b also when the info is Not Available";
CM_ SG_ 2566899694 DayDrivTimeShift4Flag "- 1b also when the info is Not Available";
CM_ SG_ 2566899694 DayDrivTimeShift5Flag "- 1b also when the info is Not Available";
CM_ SG_ 2566899694 DayDrivTimeShift6Flag "- 1b also when the info is Not Available";
CM_ SG_ 2566899694 DayRestPer1Flag "- 1b also when the info is Not Available";
CM_ SG_ 2566899694 DayRestPer2Flag "- 1b also when the info is Not Available";
CM_ SG_ 2566899694 DayRestPer3Flag "- 1b also when the info is Not Available";
CM_ SG_ 2566899694 DayRestPer4Flag "- 1b also when the info is Not Available";
CM_ SG_ 2566899694 DayRestPer5Flag "- 1b also when the info is Not Available";
CM_ SG_ 2566899694 DayRestPer6Flag "- 1b also when the info is Not Available";
CM_ SG_ 2566899694 DayRestPer7Flag "- 1b also when the info is Not Available";
CM_ SG_ 2566899694 DayOdo "- Currently not used";
CM_ SG_ 2566899694 WeekTotOdo "- Currently not used";
CM_ SG_ 2566899694 TwoWeeksTotOdo "- Currently not used";
CM_ SG_ 2566899694 DrivCnt "- Currently not used";
CM_ SG_ 2566899694 WorkCnt "- Currently not used";
CM_ SG_ 2566899694 AvCnt "- Currently not used";
BA_DEF_ BO_  "CI_MsgDefinition" STRING ;
BA_DEF_ BO_  "CI_MsgId" INT 0 2147483647;
BA_DEF_ BO_  "CI_MsgName" STRING ;
BA_DEF_ BO_  "GenMsgCycleTime" INT 0 3600000;
BA_DEF_ BO_  "GenMsgCycleTimeFast" INT 0 3600000;
BA_DEF_ BO_  "GenMsgDelayTime" INT 0 3600000;
BA_DEF_ BO_  "GenMsgILSupport" ENUM  "No","Yes";
BA_DEF_ BO_  "GenMsgNrOfRepetition" INT 0 1000000;
BA_DEF_ BO_  "GenMsgRequestable" INT 0 1;
BA_DEF_ BO_  "GenMsgSendType" ENUM  "cyclic","NotUsed","NotUsed","NotUsed","NotUsed","NotUsed","NotUsed","IfActive","noMsgSendType";
BA_DEF_ BO_  "GenMsgStartDelayTime" INT 0 100000;
BA_DEF_ BO_  "J1939PgAppearanceOnBus" ENUM  "Default","CAN_Extended","CANFD_Extended";
BA_DEF_ BO_  "TpJ1939VarDlc" ENUM  "No","Yes";
BA_DEF_ BO_  "VFrameFormat" ENUM  "StandardCAN","ExtendedCAN","reserved","J1939PG";
BA_DEF_ SG_  "CI_ParId" STRING ;
BA_DEF_ SG_  "CI_SigId" INT 0 2147483647;
BA_DEF_ SG_  "CI_SigName" STRING ;
BA_DEF_ SG_  "GenSigEVName" STRING ;
BA_DEF_ SG_  "GenSigILSupport" ENUM  "No","Yes";
BA_DEF_ SG_  "GenSigInactiveValue" INT 0 2147483647;
BA_DEF_ SG_  "GenSigSendType" ENUM  "Cyclic","OnWrite","OnWriteWithRepetition","OnChange","OnChangeWithRepetition","IfActive","IfActiveWithRepetition","NoSigSendType";
BA_DEF_ SG_  "GenSigStartValue" INT 0 2147483647;
BA_DEF_ SG_  "GenSigTimeoutTime_ACU" INT 0 3600000;
BA_DEF_ SG_  "GenSigTimeoutTime_ADCU" INT 0 3600000;
BA_DEF_ SG_  "GenSigTimeoutTime_CAID" INT 0 3600000;
BA_DEF_ SG_  "GenSigTimeoutTime_CANAIR" INT 0 3600000;
BA_DEF_ SG_  "GenSigTimeoutTime_DICO" INT 0 3600000;
BA_DEF_ SG_  "GenSigTimeoutTime_DTCO" INT 0 3600000;
BA_DEF_ SG_  "GenSigTimeoutTime_DiwaNXT" INT 0 3600000;
BA_DEF_ SG_  "GenSigTimeoutTime_DiwaNXT_MH" INT 0 3600000;
BA_DEF_ SG_  "GenSigTimeoutTime_EBS" INT 0 3600000;
BA_DEF_ SG_  "GenSigTimeoutTime_EBS_" INT 0 3600000;
BA_DEF_ SG_  "GenSigTimeoutTime_EBS__" INT 0 3600000;
BA_DEF_ SG_  "GenSigTimeoutTime_EBS___" INT 0 3600000;
BA_DEF_ SG_  "GenSigTimeoutTime_ELC5_Fr" INT 0 3600000;
BA_DEF_ SG_  "GenSigTimeoutTime_ELFA3" INT 0 3600000;
BA_DEF_ SG_  "GenSigTimeoutTime_ETS" INT 0 3600000;
BA_DEF_ SG_  "GenSigTimeoutTime_Ecolife2" INT 0 3600000;
BA_DEF_ SG_  "GenSigTimeoutTime_FCCU_" INT 0 3600000;
BA_DEF_ SG_  "GenSigTimeoutTime_FMS4" INT 0 3600000;
BA_DEF_ SG_  "GenSigTimeoutTime_HV_BOX" INT 0 3600000;
BA_DEF_ SG_  "GenSigTimeoutTime_INTD" INT 0 3600000;
BA_DEF_ SG_  "GenSigTimeoutTime_IRCS" INT 0 3600000;
BA_DEF_ SG_  "GenSigTimeoutTime_MD1_D" INT 0 3600000;
BA_DEF_ SG_  "GenSigTimeoutTime_MD1_G" INT 0 3600000;
BA_DEF_ SG_  "GenSigTimeoutTime_MTCO" INT 0 3600000;
BA_DEF_ SG_  "GenSigTimeoutTime_MulticII" INT 0 3600000;
BA_DEF_ SG_  "GenSigTimeoutTime_MulticS" INT 0 3600000;
BA_DEF_ SG_  "GenSigTimeoutTime_MulticS_" INT 0 3600000;
BA_DEF_ SG_  "GenSigTimeoutTime_MulticS__" INT 0 3600000;
BA_DEF_ SG_  "GenSigTimeoutTime_NBM" INT 0 3600000;
BA_DEF_ SG_  "GenSigTimeoutTime_NBM_" INT 0 3600000;
BA_DEF_ SG_  "GenSigTimeoutTime_NBM__" INT 0 3600000;
BA_DEF_ SG_  "GenSigTimeoutTime_NBM___" INT 0 3600000;
BA_DEF_ SG_  "GenSigTimeoutTime_PCM" INT 0 3600000;
BA_DEF_ SG_  "GenSigTimeoutTime_SGW" INT 0 3600000;
BA_DEF_ SG_  "GenSigTimeoutTime_SGW2" INT 0 3600000;
BA_DEF_ SG_  "GenSigTimeoutTime_SGW_" INT 0 3600000;
BA_DEF_ SG_  "GenSigTimeoutTime_SGW__" INT 0 3600000;
BA_DEF_ SG_  "GenSigTimeoutTime_SIU" INT 0 3600000;
BA_DEF_ SG_  "GenSigTimeoutTime_SmartRadio" INT 0 3600000;
BA_DEF_ SG_  "GenSigTimeoutTime_TPMS" INT 0 3600000;
BA_DEF_ SG_  "GenSigTimeoutTime_TSU" INT 0 3600000;
BA_DEF_ SG_  "GenSigTimeoutTime_VCM" INT 0 3600000;
BA_DEF_ SG_  "GenSigTimeoutTime_VCM_" INT 0 3600000;
BA_DEF_ SG_  "GenSigTimeoutTime_VCM__" INT 0 3600000;
BA_DEF_ SG_  "GenSigTimeoutTime_VCU" INT 0 3600000;
BA_DEF_ SG_  "GenSigTimeoutTime_VCU_" INT 0 3600000;
BA_DEF_ SG_  "GenSigTimeoutTime_VMU" INT 0 3600000;
BA_DEF_ SG_  "SPN" INT 0 524287;
BA_DEF_ SG_  "SigType" ENUM  "Default","Range","RangeSigned","ASCII","Discrete","Control","ReferencePGN","DTC","StringDelimiter","StringLength","StringLengthControl";
BA_DEF_DEF_  "CI_MsgDefinition" "";
BA_DEF_DEF_  "CI_MsgId" 0;
BA_DEF_DEF_  "CI_MsgName" "";
BA_DEF_DEF_  "GenMsgCycleTime" 0;
BA_DEF_DEF_  "GenMsgCycleTimeFast" 0;
BA_DEF_DEF_  "GenMsgDelayTime" 1;
BA_DEF_DEF_  "GenMsgILSupport" "Yes";
BA_DEF_DEF_  "GenMsgNrOfRepetition" 0;
BA_DEF_DEF_  "GenMsgRequestable" 0;
BA_DEF_DEF_  "GenMsgSendType" "noMsgSendType";
BA_DEF_DEF_  "GenMsgStartDelayTime" 0;
BA_DEF_DEF_  "J1939PgAppearanceOnBus" "Default";
BA_DEF_DEF_  "TpJ1939VarDlc" "No";
BA_DEF_DEF_  "VFrameFormat" "J1939PG";
BA_DEF_DEF_  "CI_ParId" "";
BA_DEF_DEF_  "CI_SigId" 0;
BA_DEF_DEF_  "CI_SigName" "";
BA_DEF_DEF_  "GenSigEVName" "Env@Nodename_@Signame";
BA_DEF_DEF_  "GenSigILSupport" "Yes";
BA_DEF_DEF_  "GenSigInactiveValue" 0;
BA_DEF_DEF_  "GenSigSendType" "NoSigSendType";
BA_DEF_DEF_  "GenSigStartValue" 0;
BA_DEF_DEF_  "GenSigTimeoutTime_ACU" 0;
BA_DEF_DEF_  "GenSigTimeoutTime_ADCU" 0;
BA_DEF_DEF_  "GenSigTimeoutTime_CAID" 0;
BA_DEF_DEF_  "GenSigTimeoutTime_CANAIR" 0;
BA_DEF_DEF_  "GenSigTimeoutTime_DICO" 0;
BA_DEF_DEF_  "GenSigTimeoutTime_DTCO" 0;
BA_DEF_DEF_  "GenSigTimeoutTime_DiwaNXT" 0;
BA_DEF_DEF_  "GenSigTimeoutTime_DiwaNXT_MH" 0;
BA_DEF_DEF_  "GenSigTimeoutTime_EBS" 0;
BA_DEF_DEF_  "GenSigTimeoutTime_EBS_" 0;
BA_DEF_DEF_  "GenSigTimeoutTime_EBS__" 0;
BA_DEF_DEF_  "GenSigTimeoutTime_EBS___" 0;
BA_DEF_DEF_  "GenSigTimeoutTime_ELC5_Fr" 0;
BA_DEF_DEF_  "GenSigTimeoutTime_ELFA3" 0;
BA_DEF_DEF_  "GenSigTimeoutTime_ETS" 0;
BA_DEF_DEF_  "GenSigTimeoutTime_Ecolife2" 0;
BA_DEF_DEF_  "GenSigTimeoutTime_FCCU_" 0;
BA_DEF_DEF_  "GenSigTimeoutTime_FMS4" 0;
BA_DEF_DEF_  "GenSigTimeoutTime_HV_BOX" 0;
BA_DEF_DEF_  "GenSigTimeoutTime_INTD" 0;
BA_DEF_DEF_  "GenSigTimeoutTime_IRCS" 0;
BA_DEF_DEF_  "GenSigTimeoutTime_MD1_D" 0;
BA_DEF_DEF_  "GenSigTimeoutTime_MD1_G" 0;
BA_DEF_DEF_  "GenSigTimeoutTime_MTCO" 0;
BA_DEF_DEF_  "GenSigTimeoutTime_MulticII" 0;
BA_DEF_DEF_  "GenSigTimeoutTime_MulticS" 0;
BA_DEF_DEF_  "GenSigTimeoutTime_MulticS_" 0;
BA_DEF_DEF_  "GenSigTimeoutTime_MulticS__" 0;
BA_DEF_DEF_  "GenSigTimeoutTime_NBM" 0;
BA_DEF_DEF_  "GenSigTimeoutTime_NBM_" 0;
BA_DEF_DEF_  "GenSigTimeoutTime_NBM__" 0;
BA_DEF_DEF_  "GenSigTimeoutTime_NBM___" 0;
BA_DEF_DEF_  "GenSigTimeoutTime_PCM" 0;
BA_DEF_DEF_  "GenSigTimeoutTime_SGW" 0;
BA_DEF_DEF_  "GenSigTimeoutTime_SGW2" 0;
BA_DEF_DEF_  "GenSigTimeoutTime_SGW_" 0;
BA_DEF_DEF_  "GenSigTimeoutTime_SGW__" 0;
BA_DEF_DEF_  "GenSigTimeoutTime_SIU" 0;
BA_DEF_DEF_  "GenSigTimeoutTime_SmartRadio" 0;
BA_DEF_DEF_  "GenSigTimeoutTime_TPMS" 0;
BA_DEF_DEF_  "GenSigTimeoutTime_TSU" 0;
BA_DEF_DEF_  "GenSigTimeoutTime_VCM" 0;
BA_DEF_DEF_  "GenSigTimeoutTime_VCM_" 0;
BA_DEF_DEF_  "GenSigTimeoutTime_VCM__" 0;
BA_DEF_DEF_  "GenSigTimeoutTime_VCU" 0;
BA_DEF_DEF_  "GenSigTimeoutTime_VCU_" 0;
BA_DEF_DEF_  "GenSigTimeoutTime_VMU" 0;
BA_DEF_DEF_  "SPN" 0;
BA_DEF_DEF_  "SigType" "Default";
BA_ "CI_MsgDefinition" BO_ 2364540032 "J1939DA";
BA_ "CI_MsgId" BO_ 2364540032 855;
BA_ "CI_MsgName" BO_ 2364540032 "EEC1_H_80 - Electronic Engine Controller 1";
BA_ "GenMsgCycleTime" BO_ 2364540032 10;
BA_ "GenMsgCycleTimeFast" BO_ 2364540032 10;
BA_ "GenMsgDelayTime" BO_ 2364540032 5;
BA_ "GenMsgSendType" BO_ 2364540032 0;
BA_ "GenMsgStartDelayTime" BO_ 2364540032 2;
BA_ "CI_MsgDefinition" BO_ 2566767127 "J1939DA";
BA_ "CI_MsgId" BO_ 2566767127 959;
BA_ "CI_MsgName" BO_ 2566767127 "EEC14_17 - Engine Configuration";
BA_ "GenMsgCycleTime" BO_ 2566767127 10000;
BA_ "GenMsgCycleTimeFast" BO_ 2566767127 10000;
BA_ "GenMsgDelayTime" BO_ 2566767127 5000;
BA_ "GenMsgSendType" BO_ 2566767127 0;
BA_ "GenMsgStartDelayTime" BO_ 2566767127 90;
BA_ "CI_MsgDefinition" BO_ 2364539648 "J1939DA";
BA_ "CI_MsgId" BO_ 2364539648 863;
BA_ "CI_MsgName" BO_ 2364539648 "EEC2 - Electronic Engine Controller 2";
BA_ "GenMsgCycleTime" BO_ 2364539648 50;
BA_ "GenMsgCycleTimeFast" BO_ 2364539648 50;
BA_ "GenMsgDelayTime" BO_ 2364539648 25;
BA_ "GenMsgSendType" BO_ 2364539648 0;
BA_ "GenMsgStartDelayTime" BO_ 2364539648 6;
BA_ "CI_MsgDefinition" BO_ 2364539776 "J1939DA";
BA_ "CI_MsgId" BO_ 2364539776 878;
BA_ "CI_MsgName" BO_ 2364539776 "EEC2_H_80 - Electronic Engine Controller 2";
BA_ "GenMsgCycleTime" BO_ 2364539776 50;
BA_ "GenMsgCycleTimeFast" BO_ 2364539776 50;
BA_ "GenMsgDelayTime" BO_ 2364539776 25;
BA_ "GenMsgSendType" BO_ 2364539776 0;
BA_ "GenMsgStartDelayTime" BO_ 2364539776 6;
BA_ "CI_MsgDefinition" BO_ 2566840064 "J1939DA";
BA_ "CI_MsgId" BO_ 2566840064 931;
BA_ "CI_MsgName" BO_ 2566840064 "EEC3 - Electronic Engine Controller 3";
BA_ "GenMsgCycleTime" BO_ 2566840064 250;
BA_ "GenMsgCycleTimeFast" BO_ 2566840064 250;
BA_ "GenMsgDelayTime" BO_ 2566840064 125;
BA_ "GenMsgSendType" BO_ 2566840064 0;
BA_ "GenMsgStartDelayTime" BO_ 2566840064 23;
BA_ "CI_MsgDefinition" BO_ 2566840192 "J1939DA";
BA_ "CI_MsgId" BO_ 2566840192 941;
BA_ "CI_MsgName" BO_ 2566840192 "EEC3_H - Electronic Engine Controller 3";
BA_ "GenMsgCycleTime" BO_ 2566840192 200;
BA_ "GenMsgCycleTimeFast" BO_ 2566840192 200;
BA_ "GenMsgDelayTime" BO_ 2566840192 100;
BA_ "GenMsgSendType" BO_ 2566840192 0;
BA_ "GenMsgStartDelayTime" BO_ 2566840192 11;
BA_ "CI_MsgDefinition" BO_ 2566844160 "J1939DA";
BA_ "CI_MsgId" BO_ 2566844160 1076;
BA_ "CI_MsgName" BO_ 2566844160 "EFLP1 - Engine Fluid Level/Pressure 1";
BA_ "GenMsgCycleTime" BO_ 2566844160 500;
BA_ "GenMsgCycleTimeFast" BO_ 2566844160 500;
BA_ "GenMsgDelayTime" BO_ 2566844160 250;
BA_ "GenMsgSendType" BO_ 2566844160 0;
BA_ "GenMsgStartDelayTime" BO_ 2566844160 23;
BA_ "CI_MsgDefinition" BO_ 2566885210 "Iveco Proprietary";
BA_ "CI_MsgId" BO_ 2566885210 1364;
BA_ "CI_MsgName" BO_ 2566885210 "ELFASys1_ELFA2 - ElfaSystem1 - DICO to VCU";
BA_ "GenMsgCycleTime" BO_ 2566885210 50;
BA_ "GenMsgCycleTimeFast" BO_ 2566885210 50;
BA_ "GenMsgDelayTime" BO_ 2566885210 25;
BA_ "GenMsgSendType" BO_ 2566885210 0;
BA_ "GenMsgStartDelayTime" BO_ 2566885210 8;
BA_ "CI_MsgDefinition" BO_ 2566898290 "Iveco SPR2 Proprietary";
BA_ "CI_MsgId" BO_ 2566898290 3928;
BA_ "CI_MsgName" BO_ 2566898290 "EmCmd - Expansion Module Command";
BA_ "GenMsgCycleTime" BO_ 2566898290 50;
BA_ "GenMsgCycleTimeFast" BO_ 2566898290 50;
BA_ "GenMsgDelayTime" BO_ 2566898290 50;
BA_ "GenMsgSendType" BO_ 2566898290 0;
BA_ "GenMsgStartDelayTime" BO_ 2566898290 4;
BA_ "CI_MsgDefinition" BO_ 2565865488 "J1939DA";
BA_ "CI_MsgId" BO_ 2565865488 407;
BA_ "CI_MsgName" BO_ 2565865488 "ERC1_DR - Electronic Retarder Controller 1 - Driveline Retarder";
BA_ "GenMsgCycleTime" BO_ 2565865488 20;
BA_ "GenMsgCycleTimeFast" BO_ 2565865488 20;
BA_ "GenMsgDelayTime" BO_ 2565865488 10;
BA_ "GenMsgSendType" BO_ 2565865488 0;
BA_ "GenMsgStartDelayTime" BO_ 2565865488 4;
BA_ "CI_MsgDefinition" BO_ 2565865487 "J1939DA";
BA_ "CI_MsgId" BO_ 2565865487 14809;
BA_ "CI_MsgName" BO_ 2565865487 "ERC1_ER - Electronic Retarder Controller 1 - Engine Retarder";
BA_ "GenMsgCycleTime" BO_ 2565865487 100;
BA_ "GenMsgCycleTimeFast" BO_ 2565865487 100;
BA_ "GenMsgDelayTime" BO_ 2565865487 50;
BA_ "GenMsgSendType" BO_ 2565865487 0;
BA_ "GenMsgStartDelayTime" BO_ 2565865487 12;
BA_ "CI_MsgDefinition" BO_ 2566843904 "J1939DA";
BA_ "CI_MsgId" BO_ 2566843904 1069;
BA_ "CI_MsgName" BO_ 2566843904 "ET1 - Engine Temperature 1";
BA_ "GenMsgCycleTime" BO_ 2566843904 1000;
BA_ "GenMsgCycleTimeFast" BO_ 2566843904 1000;
BA_ "GenMsgDelayTime" BO_ 2566843904 500;
BA_ "GenMsgSendType" BO_ 2566843904 0;
BA_ "GenMsgStartDelayTime" BO_ 2566843904 46;
BA_ "CI_MsgDefinition" BO_ 2364539395 "J1939DA";
BA_ "CI_MsgId" BO_ 2364539395 529;
BA_ "CI_MsgName" BO_ 2364539395 "ETC1 - Electronic Transmission Controller 1";
BA_ "GenMsgCycleTime" BO_ 2364539395 10;
BA_ "GenMsgCycleTimeFast" BO_ 2364539395 10;
BA_ "GenMsgDelayTime" BO_ 2364539395 5;
BA_ "GenMsgSendType" BO_ 2364539395 0;
BA_ "CI_MsgDefinition" BO_ 2565866755 "J1939DA";
BA_ "CI_MsgId" BO_ 2565866755 541;
BA_ "CI_MsgName" BO_ 2565866755 "ETC2 - Electronic Transmission Controller 2";
BA_ "GenMsgCycleTime" BO_ 2565866755 100;
BA_ "GenMsgCycleTimeFast" BO_ 2565866755 100;
BA_ "GenMsgDelayTime" BO_ 2565866755 50;
BA_ "GenMsgSendType" BO_ 2565866755 0;
BA_ "GenMsgStartDelayTime" BO_ 2565866755 8;
BA_ "CI_MsgDefinition" BO_ 2566826755 "J1939DA";
BA_ "CI_MsgId" BO_ 2566826755 564;
BA_ "CI_MsgName" BO_ 2566826755 "ETC6_P6 - Electronic Transmission Controller 6";
BA_ "GenMsgCycleTime" BO_ 2566826755 250;
BA_ "GenMsgCycleTimeFast" BO_ 2566826755 250;
BA_ "GenMsgDelayTime" BO_ 2566826755 125;
BA_ "GenMsgSendType" BO_ 2566826755 0;
BA_ "GenMsgStartDelayTime" BO_ 2566826755 22;
BA_ "CI_MsgDefinition" BO_ 2364541955 "J1939DA";
BA_ "CI_MsgId" BO_ 2364541955 625;
BA_ "CI_MsgName" BO_ 2364541955 "ETC8 - Electronic Transmission Controller #8";
BA_ "GenMsgCycleTime" BO_ 2364541955 100;
BA_ "GenMsgCycleTimeFast" BO_ 2364541955 20;
BA_ "GenMsgDelayTime" BO_ 2364541955 10;
BA_ "GenMsgSendType" BO_ 2364541955 0;
BA_ "GenMsgStartDelayTime" BO_ 2364541955 9;
BA_ "CI_MsgDefinition" BO_ 2566831393 "J1939DA";
BA_ "CI_MsgId" BO_ 2566831393 2180;
BA_ "CI_MsgName" BO_ 2566831393 "FD1_21 - Fan Drive #1";
BA_ "GenMsgCycleTime" BO_ 2566831393 1000;
BA_ "GenMsgCycleTimeFast" BO_ 2566831393 1000;
BA_ "GenMsgDelayTime" BO_ 2566831393 500;
BA_ "GenMsgSendType" BO_ 2566831393 0;
BA_ "GenMsgStartDelayTime" BO_ 2566831393 61;
BA_ "CI_MsgDefinition" BO_ 2431649694 "J1939DA";
BA_ "CI_MsgId" BO_ 2431649694 3104;
BA_ "CI_MsgName" BO_ 2431649694 "FLI1_9E - Forward Lane Image 1";
BA_ "GenMsgCycleTime" BO_ 2431649694 50;
BA_ "GenMsgCycleTimeFast" BO_ 2431649694 50;
BA_ "GenMsgDelayTime" BO_ 2431649694 25;
BA_ "GenMsgNrOfRepetition" BO_ 2431649694 4;
BA_ "GenMsgSendType" BO_ 2431649694 0;
BA_ "GenMsgStartDelayTime" BO_ 2431649694 4;
BA_ "CI_MsgDefinition" BO_ 2566806430 "J1939DA";
BA_ "CI_MsgId" BO_ 2566806430 3118;
BA_ "CI_MsgName" BO_ 2566806430 "FLI2_9E - Forward Lane Image 2";
BA_ "GenMsgCycleTime" BO_ 2566806430 100;
BA_ "GenMsgCycleTimeFast" BO_ 2566806430 100;
BA_ "GenMsgDelayTime" BO_ 2566806430 50;
BA_ "GenMsgSendType" BO_ 2566806430 0;
BA_ "GenMsgStartDelayTime" BO_ 2566806430 6;
BA_ "CI_MsgDefinition" BO_ 2566841600 "J1939DA";
BA_ "CI_MsgId" BO_ 2566841600 1093;
BA_ "CI_MsgName" BO_ 2566841600 "HOURS - Engine Hours, Revolutions";
BA_ "GenMsgCycleTime" BO_ 2566841600 1000;
BA_ "GenMsgCycleTimeFast" BO_ 2566841600 1000;
BA_ "GenMsgDelayTime" BO_ 2566841600 500;
BA_ "GenMsgSendType" BO_ 2566841600 0;
BA_ "GenMsgStartDelayTime" BO_ 2566841600 36;
BA_ "CI_MsgDefinition" BO_ 2566719744 "J1939DA";
BA_ "CI_MsgId" BO_ 2566719744 1147;
BA_ "CI_MsgName" BO_ 2566719744 "HRLFC - High Resolution Fuel Consumption (Liquid)";
BA_ "GenMsgCycleTime" BO_ 2566719744 1000;
BA_ "GenMsgCycleTimeFast" BO_ 2566719744 1000;
BA_ "GenMsgDelayTime" BO_ 2566719744 500;
BA_ "GenMsgSendType" BO_ 2566719744 0;
BA_ "GenMsgStartDelayTime" BO_ 2566719744 36;
BA_ "CI_MsgDefinition" BO_ 2566837793 "J1939DA";
BA_ "CI_MsgId" BO_ 2566837793 2221;
BA_ "CI_MsgName" BO_ 2566837793 "HSI1_21 - Hybrid System Inputs 1";
BA_ "GenMsgCycleTime" BO_ 2566837793 100;
BA_ "GenMsgCycleTimeFast" BO_ 2566837793 100;
BA_ "GenMsgDelayTime" BO_ 2566837793 50;
BA_ "GenMsgSendType" BO_ 2566837793 0;
BA_ "GenMsgStartDelayTime" BO_ 2566837793 26;
BA_ "CI_MsgDefinition" BO_ 2566701658 "J1939DA";
BA_ "CI_MsgId" BO_ 2566701658 2233;
BA_ "CI_MsgName" BO_ 2566701658 "HSS1_5A - Hybrid System Status 1";
BA_ "GenMsgCycleTime" BO_ 2566701658 100;
BA_ "GenMsgCycleTimeFast" BO_ 2566701658 100;
BA_ "GenMsgDelayTime" BO_ 2566701658 100;
BA_ "GenMsgSendType" BO_ 2566701658 0;
BA_ "GenMsgStartDelayTime" BO_ 2566701658 17;
BA_ "CI_MsgDefinition" BO_ 2566698842 "J1939DA";
BA_ "CI_MsgId" BO_ 2566698842 2275;
BA_ "CI_MsgName" BO_ 2566698842 "HSS2_5A - Hybrid System Status 2";
BA_ "GenMsgCycleTime" BO_ 2566698842 1000;
BA_ "GenMsgCycleTimeFast" BO_ 2566698842 1000;
BA_ "GenMsgDelayTime" BO_ 2566698842 500;
BA_ "GenMsgSendType" BO_ 2566698842 0;
BA_ "GenMsgStartDelayTime" BO_ 2566698842 31;
BA_ "CI_MsgDefinition" BO_ 2566850819 "FPT Proprietary";
BA_ "CI_MsgId" BO_ 2566850819 2278;
BA_ "CI_MsgName" BO_ 2566850819 "HTCU2BC_03 - HTCU to BC (Mild Hybrid)";
BA_ "GenMsgCycleTime" BO_ 2566850819 100;
BA_ "GenMsgCycleTimeFast" BO_ 2566850819 100;
BA_ "GenMsgDelayTime" BO_ 2566850819 50;
BA_ "GenMsgSendType" BO_ 2566850819 0;
BA_ "GenMsgStartDelayTime" BO_ 2566850819 21;
BA_ "CI_MsgDefinition" BO_ 2566851075 "Iveco Proprietary";
BA_ "CI_MsgId" BO_ 2566851075 2306;
BA_ "CI_MsgName" BO_ 2566851075 "HTCU2PM_1 - HTCU2PM_1 - HTCU 2 PREDICTIVE MAINTENANCE #1";
BA_ "GenMsgCycleTime" BO_ 2566851075 300;
BA_ "GenMsgCycleTimeFast" BO_ 2566851075 300;
BA_ "GenMsgDelayTime" BO_ 2566851075 150;
BA_ "GenMsgSendType" BO_ 2566851075 0;
BA_ "GenMsgStartDelayTime" BO_ 2566851075 23;
BA_ "CI_MsgDefinition" BO_ 2566851331 "Iveco Proprietary";
BA_ "CI_MsgId" BO_ 2566851331 2312;
BA_ "CI_MsgName" BO_ 2566851331 "HTCU2PM_2 - HTCU2PM_2 - HTCU 2 PREDICTIVE MAINTENANCE #2";
BA_ "GenMsgCycleTime" BO_ 2566851331 300;
BA_ "GenMsgCycleTimeFast" BO_ 2566851331 300;
BA_ "GenMsgDelayTime" BO_ 2566851331 150;
BA_ "GenMsgSendType" BO_ 2566851331 0;
BA_ "GenMsgStartDelayTime" BO_ 2566851331 26;
BA_ "CI_MsgDefinition" BO_ 2566851843 "Iveco Proprietary";
BA_ "CI_MsgId" BO_ 2566851843 2319;
BA_ "CI_MsgName" BO_ 2566851843 "HTCU2PM_3 - HTCU2PM_3 - HTCU 2 PREDICTIVE MAINTENANCE #3";
BA_ "GenMsgCycleTime" BO_ 2566851843 300;
BA_ "GenMsgCycleTimeFast" BO_ 2566851843 300;
BA_ "GenMsgDelayTime" BO_ 2566851843 150;
BA_ "GenMsgSendType" BO_ 2566851843 0;
BA_ "GenMsgStartDelayTime" BO_ 2566851843 25;
BA_ "CI_MsgDefinition" BO_ 2566891136 "Iveco Proprietary";
BA_ "CI_MsgId" BO_ 2566891136 1374;
BA_ "CI_MsgName" BO_ 2566891136 "HVBoxOppSt - HV-Box opportunity contactor state";
BA_ "GenMsgCycleTime" BO_ 2566891136 1000;
BA_ "GenMsgCycleTimeFast" BO_ 2566891136 1000;
BA_ "GenMsgDelayTime" BO_ 2566891136 500;
BA_ "GenMsgSendType" BO_ 2566891136 0;
BA_ "GenMsgStartDelayTime" BO_ 2566891136 47;
BA_ "CI_MsgDefinition" BO_ 2566890880 "Iveco Proprietary";
BA_ "CI_MsgId" BO_ 2566890880 1381;
BA_ "CI_MsgName" BO_ 2566890880 "HVBoxOvnSt - HV-Box overnight contactor state";
BA_ "GenMsgCycleTime" BO_ 2566890880 1000;
BA_ "GenMsgCycleTimeFast" BO_ 2566890880 1000;
BA_ "GenMsgDelayTime" BO_ 2566890880 500;
BA_ "GenMsgSendType" BO_ 2566890880 0;
BA_ "GenMsgStartDelayTime" BO_ 2566890880 46;
BA_ "CI_MsgDefinition" BO_ 2566890368 "Iveco Proprietary";
BA_ "CI_MsgId" BO_ 2566890368 1388;
BA_ "CI_MsgName" BO_ 2566890368 "HVBoxSOHSt - Contactor SOH (state of health)";
BA_ "GenMsgCycleTime" BO_ 2566890368 5000;
BA_ "GenMsgCycleTimeFast" BO_ 2566890368 5000;
BA_ "GenMsgDelayTime" BO_ 2566890368 2500;
BA_ "GenMsgSendType" BO_ 2566890368 0;
BA_ "GenMsgStartDelayTime" BO_ 2566890368 64;
BA_ "CI_MsgDefinition" BO_ 2566845952 "J1939DA";
BA_ "CI_MsgId" BO_ 2566845952 1097;
BA_ "CI_MsgName" BO_ 2566845952 "IC1 - Intake/Exhaust Conditions 1";
BA_ "GenMsgCycleTime" BO_ 2566845952 100;
BA_ "GenMsgCycleTimeFast" BO_ 2566845952 100;
BA_ "GenMsgDelayTime" BO_ 2566845952 50;
BA_ "GenMsgSendType" BO_ 2566845952 0;
BA_ "GenMsgStartDelayTime" BO_ 2566845952 14;
BA_ "CI_MsgDefinition" BO_ 2566910080 "Iveco Proprietary";
BA_ "CI_MsgId" BO_ 2566910080 1120;
BA_ "CI_MsgName" BO_ 2566910080 "InfPow1 - Power information 1 from driveline";
BA_ "GenMsgCycleTime" BO_ 2566910080 500;
BA_ "GenMsgCycleTimeFast" BO_ 2566910080 500;
BA_ "GenMsgDelayTime" BO_ 2566910080 250;
BA_ "GenMsgSendType" BO_ 2566910080 0;
BA_ "GenMsgStartDelayTime" BO_ 2566910080 28;
BA_ "CI_MsgDefinition" BO_ 2566909824 "Iveco Proprietary";
BA_ "CI_MsgId" BO_ 2566909824 1129;
BA_ "CI_MsgName" BO_ 2566909824 "InfPow2 - Power information 2 from driveline";
BA_ "GenMsgCycleTime" BO_ 2566909824 1000;
BA_ "GenMsgCycleTimeFast" BO_ 2566909824 1000;
BA_ "GenMsgDelayTime" BO_ 2566909824 500;
BA_ "GenMsgSendType" BO_ 2566909824 0;
BA_ "GenMsgStartDelayTime" BO_ 2566909824 49;
BA_ "CI_MsgDefinition" BO_ 2566786839 "ISO11783-7";
BA_ "CI_MsgId" BO_ 2566786839 2644;
BA_ "CI_MsgName" BO_ 2566786839 "LC_17 - Language Command";
BA_ "GenMsgCycleTime" BO_ 2566786839 1000;
BA_ "GenMsgCycleTimeFast" BO_ 2566786839 1000;
BA_ "GenMsgDelayTime" BO_ 2566786839 500;
BA_ "GenMsgSendType" BO_ 2566786839 0;
BA_ "GenMsgStartDelayTime" BO_ 2566786839 57;
BA_ "CI_MsgDefinition" BO_ 2566842624 "J1939DA";
BA_ "CI_MsgId" BO_ 2566842624 1105;
BA_ "CI_MsgName" BO_ 2566842624 "LFC - Fuel Consumption (Liquid)";
BA_ "GenMsgCycleTime" BO_ 2566842624 1000;
BA_ "GenMsgCycleTimeFast" BO_ 2566842624 1000;
BA_ "GenMsgDelayTime" BO_ 2566842624 500;
BA_ "GenMsgSendType" BO_ 2566842624 0;
BA_ "GenMsgStartDelayTime" BO_ 2566842624 44;
BA_ "CI_MsgDefinition" BO_ 2566844928 "J1939DA";
BA_ "CI_MsgId" BO_ 2566844928 1172;
BA_ "CI_MsgName" BO_ 2566844928 "LFE - Fuel Economy";
BA_ "GenMsgCycleTime" BO_ 2566844928 100;
BA_ "GenMsgCycleTimeFast" BO_ 2566844928 100;
BA_ "GenMsgDelayTime" BO_ 2566844928 50;
BA_ "GenMsgSendType" BO_ 2566844928 0;
BA_ "GenMsgStartDelayTime" BO_ 2566844928 12;
BA_ "CI_MsgDefinition" BO_ 2566861299 "Iveco Bus Proprietary";
BA_ "CI_MsgId" BO_ 2566861299 1481;
BA_ "CI_MsgName" BO_ 2566861299 "MBMS2SCU1_F3 - ABMS";
BA_ "GenMsgCycleTime" BO_ 2566861299 5000;
BA_ "GenMsgCycleTimeFast" BO_ 2566861299 5000;
BA_ "GenMsgDelayTime" BO_ 2566861299 2500;
BA_ "GenMsgSendType" BO_ 2566861299 0;
BA_ "GenMsgStartDelayTime" BO_ 2566861299 14;
BA_ "CI_MsgDefinition" BO_ 2566861555 "Iveco Bus Proprietary";
BA_ "CI_MsgId" BO_ 2566861555 1507;
BA_ "CI_MsgName" BO_ 2566861555 "MBMS2SCU2_F3 - ABMS1";
BA_ "GenMsgCycleTime" BO_ 2566861555 5000;
BA_ "GenMsgCycleTimeFast" BO_ 2566861555 5000;
BA_ "GenMsgDelayTime" BO_ 2566861555 2500;
BA_ "GenMsgSendType" BO_ 2566861555 0;
BA_ "GenMsgStartDelayTime" BO_ 2566861555 18;
BA_ "CI_MsgDefinition" BO_ 2566776097 "J1939DA";
BA_ "CI_MsgId" BO_ 2566776097 2175;
BA_ "CI_MsgName" BO_ 2566776097 "MVS_21 - Maximum Vehicle Speed Limit Status";
BA_ "GenMsgCycleTime" BO_ 2566776097 1000;
BA_ "GenMsgCycleTimeFast" BO_ 2566776097 1000;
BA_ "GenMsgDelayTime" BO_ 2566776097 500;
BA_ "GenMsgSendType" BO_ 2566776097 0;
BA_ "GenMsgStartDelayTime" BO_ 2566776097 56;
BA_ "CI_MsgDefinition" BO_ 2365443105 "J1939DA";
BA_ "CI_MsgId" BO_ 2365443105 2626;
BA_ "CI_MsgName" BO_ 2365443105 "OEL - Operators External Light Controls Message";
BA_ "GenMsgCycleTime" BO_ 2365443105 250;
BA_ "GenMsgCycleTimeFast" BO_ 2365443105 250;
BA_ "GenMsgDelayTime" BO_ 2365443105 100;
BA_ "GenMsgSendType" BO_ 2365443105 0;
BA_ "GenMsgStartDelayTime" BO_ 2365443105 48;
BA_ "CI_MsgDefinition" BO_ 2566769953 "J1939DA";
BA_ "CI_MsgId" BO_ 2566769953 2634;
BA_ "CI_MsgName" BO_ 2566769953 "OWW_21 - Operator Wiper and Washer Controls Message";
BA_ "GenMsgCycleTime" BO_ 2566769953 1000;
BA_ "GenMsgCycleTimeFast" BO_ 2566769953 1000;
BA_ "GenMsgDelayTime" BO_ 2566769953 100;
BA_ "GenMsgSendType" BO_ 2566769953 0;
BA_ "GenMsgStartDelayTime" BO_ 2566769953 54;
BA_ "CI_MsgDefinition" BO_ 2566908574 "Iveco Proprietary";
BA_ "CI_MsgId" BO_ 2566908574 627;
BA_ "CI_MsgName" BO_ 2566908574 "PB_AIDI_9E - Proprietary B - Alcohol Interlock and Driver Information";
BA_ "GenMsgCycleTime" BO_ 2566908574 200;
BA_ "GenMsgCycleTimeFast" BO_ 2566908574 200;
BA_ "GenMsgDelayTime" BO_ 2566908574 100;
BA_ "GenMsgSendType" BO_ 2566908574 0;
BA_ "GenMsgStartDelayTime" BO_ 2566908574 8;
BA_ "CI_MsgDefinition" BO_ 2566907159 "Iveco Proprietary";
BA_ "CI_MsgId" BO_ 2566907159 4018;
BA_ "CI_MsgName" BO_ 2566907159 "PB_GSRC_17 - Proprietary B - GSR Content";
BA_ "GenMsgCycleTime" BO_ 2566907159 50;
BA_ "GenMsgCycleTimeFast" BO_ 2566907159 50;
BA_ "GenMsgDelayTime" BO_ 2566907159 25;
BA_ "GenMsgSendType" BO_ 2566907159 0;
BA_ "GenMsgStartDelayTime" BO_ 2566907159 20;
BA_ "CI_MsgDefinition" BO_ 2566894871 "Iveco Proprietary";
BA_ "CI_MsgId" BO_ 2566894871 2812;
BA_ "CI_MsgName" BO_ 2566894871 "PB_ISA_17 - Proprietary B - Intelligent Speed Assistant";
BA_ "GenMsgCycleTime" BO_ 2566894871 1000;
BA_ "GenMsgCycleTimeFast" BO_ 2566894871 1000;
BA_ "GenMsgDelayTime" BO_ 2566894871 100;
BA_ "GenMsgSendType" BO_ 2566894871 0;
BA_ "GenMsgStartDelayTime" BO_ 2566894871 82;
BA_ "CI_MsgDefinition" BO_ 2566895006 "Iveco Proprietary";
BA_ "CI_MsgId" BO_ 2566895006 2802;
BA_ "CI_MsgName" BO_ 2566895006 "PB_ISA_9E - Proprietary B - Intelligent Speed Assistant";
BA_ "GenMsgCycleTime" BO_ 2566895006 1000;
BA_ "GenMsgCycleTimeFast" BO_ 2566895006 1000;
BA_ "GenMsgDelayTime" BO_ 2566895006 100;
BA_ "GenMsgSendType" BO_ 2566895006 0;
BA_ "GenMsgStartDelayTime" BO_ 2566895006 14;
BA_ "CI_MsgDefinition" BO_ 2365575713 "Iveco SPR1 Proprietary";
BA_ "CI_MsgId" BO_ 2365575713 10485;
BA_ "CI_MsgName" BO_ 2365575713 "PB_NmM - Proprietary B - Iveco Network Management (Master Node)";
BA_ "GenMsgCycleTime" BO_ 2365575713 1000;
BA_ "GenMsgCycleTimeFast" BO_ 2365575713 1000;
BA_ "GenMsgDelayTime" BO_ 2365575713 500;
BA_ "GenMsgSendType" BO_ 2365575713 0;
BA_ "GenMsgStartDelayTime" BO_ 2365575713 27;
BA_ "CI_MsgDefinition" BO_ 2566892573 "Iveco Proprietary";
BA_ "CI_MsgId" BO_ 2566892573 2511;
BA_ "CI_MsgName" BO_ 2566892573 "PB_SecureLog_1D - Proprietary B - Secure Log";
BA_ "GenMsgDelayTime" BO_ 2566892573 50;
BA_ "CI_MsgDefinition" BO_ 2566892618 "Iveco Proprietary";
BA_ "CI_MsgId" BO_ 2566892618 2516;
BA_ "CI_MsgName" BO_ 2566892618 "PB_SecureLog_4A - Proprietary B - Secure Log";
BA_ "GenMsgDelayTime" BO_ 2566892618 50;
BA_ "CI_MsgDefinition" BO_ 2566885148 "Iveco Proprietary";
BA_ "CI_MsgId" BO_ 2566885148 12990;
BA_ "CI_MsgName" BO_ 2566885148 "PB_SpeedLimRelCond_1C - Proprietary B - Speed Limit Related Condition";
BA_ "GenMsgCycleTime" BO_ 2566885148 1000;
BA_ "GenMsgCycleTimeFast" BO_ 2566885148 1000;
BA_ "GenMsgDelayTime" BO_ 2566885148 500;
BA_ "GenMsgSendType" BO_ 2566885148 0;
BA_ "GenMsgStartDelayTime" BO_ 2566885148 164;
BA_ "CI_MsgDefinition" BO_ 2566898670 "Continental Proprietary";
BA_ "CI_MsgId" BO_ 2566898670 745;
BA_ "CI_MsgName" BO_ 2566898670 "PB_TCO2 - TCO2 (Continental Proprietary)";
BA_ "GenMsgCycleTime" BO_ 2566898670 60000;
BA_ "GenMsgCycleTimeFast" BO_ 2566898670 60000;
BA_ "GenMsgDelayTime" BO_ 2566898670 1000;
BA_ "GenMsgSendType" BO_ 2566898670 0;
BA_ "GenMsgStartDelayTime" BO_ 2566898670 38;
BA_ "CI_MsgDefinition" BO_ 2566898926 "Continental Proprietary";
BA_ "CI_MsgId" BO_ 2566898926 752;
BA_ "CI_MsgName" BO_ 2566898926 "PB_TCO3 - TCO3 (Continental Proprietary)";
BA_ "GenMsgCycleTime" BO_ 2566898926 10000;
BA_ "GenMsgCycleTimeFast" BO_ 2566898926 10000;
BA_ "GenMsgDelayTime" BO_ 2566898926 5000;
BA_ "GenMsgSendType" BO_ 2566898926 0;
BA_ "GenMsgStartDelayTime" BO_ 2566898926 30;
BA_ "CI_MsgDefinition" BO_ 2566899694 "Continental Proprietary";
BA_ "CI_MsgId" BO_ 2566899694 759;
BA_ "CI_MsgName" BO_ 2566899694 "PB_TCO4 - Tachograph 4";
BA_ "GenMsgCycleTime" BO_ 2566899694 60000;
BA_ "GenMsgCycleTimeFast" BO_ 2566899694 60000;
BA_ "GenMsgDelayTime" BO_ 2566899694 1000;
BA_ "GenMsgSendType" BO_ 2566899694 0;
BA_ "GenMsgStartDelayTime" BO_ 2566899694 40;
BA_ "CI_MsgDefinition" BO_ 2650771712 "Iveco Proprietary";
BA_ "CI_MsgId" BO_ 2650771712 17420;
BA_ "CI_MsgName" BO_ 2650771712 "PB_Telemetry01 - Proprietary B - Telemetry 01";
BA_ "GenMsgCycleTime" BO_ 2650771712 5000;
BA_ "GenMsgCycleTimeFast" BO_ 2650771712 5000;
BA_ "GenMsgDelayTime" BO_ 2650771712 2500;
BA_ "GenMsgSendType" BO_ 2650771712 0;
BA_ "GenMsgStartDelayTime" BO_ 2650771712 56;
BA_ "CI_MsgDefinition" BO_ 2650771968 "Iveco Proprietary";
BA_ "CI_MsgId" BO_ 2650771968 17429;
BA_ "CI_MsgName" BO_ 2650771968 "PB_Telemetry02 - Proprietary B - Telemetry 02";
BA_ "GenMsgCycleTime" BO_ 2650771968 5000;
BA_ "GenMsgCycleTimeFast" BO_ 2650771968 5000;
BA_ "GenMsgDelayTime" BO_ 2650771968 2500;
BA_ "GenMsgSendType" BO_ 2650771968 0;
BA_ "GenMsgStartDelayTime" BO_ 2650771968 58;
BA_ "CI_ParId" SG_ 2364540032 ActEngPcTrq_0CF00480 "513";
BA_ "CI_SigId" SG_ 2364540032 ActEngPcTrq_0CF00480 858;
BA_ "CI_SigName" SG_ 2364540032 ActEngPcTrq_0CF00480 "Actual Engine - Percent Torque";
BA_ "GenSigTimeoutTime_ADCU" SG_ 2364540032 ActEngPcTrq_0CF00480 500;
BA_ "GenSigTimeoutTime_EBS_" SG_ 2364540032 ActEngPcTrq_0CF00480 500;
BA_ "GenSigTimeoutTime_EBS__" SG_ 2364540032 ActEngPcTrq_0CF00480 500;
BA_ "GenSigTimeoutTime_FMS4" SG_ 2364540032 ActEngPcTrq_0CF00480 500;
BA_ "GenSigTimeoutTime_MulticII" SG_ 2364540032 ActEngPcTrq_0CF00480 500;
BA_ "GenSigTimeoutTime_PCM" SG_ 2364540032 ActEngPcTrq_0CF00480 500;
BA_ "GenSigTimeoutTime_SGW__" SG_ 2364540032 ActEngPcTrq_0CF00480 500;
BA_ "GenSigTimeoutTime_VCU" SG_ 2364540032 ActEngPcTrq_0CF00480 500;
BA_ "SPN" SG_ 2364540032 ActEngPcTrq_0CF00480 513;
BA_ "SigType" SG_ 2364540032 ActEngPcTrq_0CF00480 1;
BA_ "CI_ParId" SG_ 2364540032 EngSpeed_0CF00480 "190";
BA_ "CI_SigId" SG_ 2364540032 EngSpeed_0CF00480 859;
BA_ "CI_SigName" SG_ 2364540032 EngSpeed_0CF00480 "Engine Speed";
BA_ "GenSigTimeoutTime_ADCU" SG_ 2364540032 EngSpeed_0CF00480 500;
BA_ "GenSigTimeoutTime_EBS_" SG_ 2364540032 EngSpeed_0CF00480 500;
BA_ "GenSigTimeoutTime_EBS__" SG_ 2364540032 EngSpeed_0CF00480 500;
BA_ "GenSigTimeoutTime_FMS4" SG_ 2364540032 EngSpeed_0CF00480 500;
BA_ "GenSigTimeoutTime_MulticII" SG_ 2364540032 EngSpeed_0CF00480 500;
BA_ "GenSigTimeoutTime_PCM" SG_ 2364540032 EngSpeed_0CF00480 500;
BA_ "GenSigTimeoutTime_SGW__" SG_ 2364540032 EngSpeed_0CF00480 500;
BA_ "GenSigTimeoutTime_SIU" SG_ 2364540032 EngSpeed_0CF00480 500;
BA_ "GenSigTimeoutTime_TPMS" SG_ 2364540032 EngSpeed_0CF00480 500;
BA_ "GenSigTimeoutTime_VCU" SG_ 2364540032 EngSpeed_0CF00480 500;
BA_ "SPN" SG_ 2364540032 EngSpeed_0CF00480 190;
BA_ "SigType" SG_ 2364540032 EngSpeed_0CF00480 1;
BA_ "CI_ParId" SG_ 2566767127 FuelType "5837";
BA_ "CI_SigId" SG_ 2566767127 FuelType 960;
BA_ "CI_SigName" SG_ 2566767127 FuelType "Fuel Type";
BA_ "GenSigTimeoutTime_FMS4" SG_ 2566767127 FuelType 50000;
BA_ "GenSigTimeoutTime_PCM" SG_ 2566767127 FuelType 50000;
BA_ "GenSigTimeoutTime_SGW__" SG_ 2566767127 FuelType 50000;
BA_ "SPN" SG_ 2566767127 FuelType 5837;
BA_ "CI_ParId" SG_ 2364539648 AccPed1LowIdleSw "558";
BA_ "CI_SigId" SG_ 2364539648 AccPed1LowIdleSw 864;
BA_ "CI_SigName" SG_ 2364539648 AccPed1LowIdleSw "Accelerator Pedal 1 Low Idle Switch";
BA_ "GenSigTimeoutTime_EBS" SG_ 2364539648 AccPed1LowIdleSw 500;
BA_ "GenSigTimeoutTime_EBS___" SG_ 2364539648 AccPed1LowIdleSw 500;
BA_ "GenSigTimeoutTime_NBM" SG_ 2364539648 AccPed1LowIdleSw 500;
BA_ "GenSigTimeoutTime_NBM___" SG_ 2364539648 AccPed1LowIdleSw 500;
BA_ "GenSigTimeoutTime_PCM" SG_ 2364539648 AccPed1LowIdleSw 500;
BA_ "GenSigTimeoutTime_SGW__" SG_ 2364539648 AccPed1LowIdleSw 500;
BA_ "SPN" SG_ 2364539648 AccPed1LowIdleSw 558;
BA_ "SigType" SG_ 2364539648 AccPed1LowIdleSw 4;
BA_ "CI_ParId" SG_ 2364539648 AccPedKdSw "559";
BA_ "CI_SigId" SG_ 2364539648 AccPedKdSw 865;
BA_ "CI_SigName" SG_ 2364539648 AccPedKdSw "Accelerator Pedal Kickdown Switch";
BA_ "GenSigTimeoutTime_ADCU" SG_ 2364539648 AccPedKdSw 500;
BA_ "GenSigTimeoutTime_Ecolife2" SG_ 2364539648 AccPedKdSw 500;
BA_ "GenSigTimeoutTime_PCM" SG_ 2364539648 AccPedKdSw 500;
BA_ "GenSigTimeoutTime_SGW__" SG_ 2364539648 AccPedKdSw 500;
BA_ "SPN" SG_ 2364539648 AccPedKdSw 559;
BA_ "SigType" SG_ 2364539648 AccPedKdSw 4;
BA_ "CI_ParId" SG_ 2364539648 AccPedPos1 "91";
BA_ "CI_SigId" SG_ 2364539648 AccPedPos1 868;
BA_ "CI_SigName" SG_ 2364539648 AccPedPos1 "Accelerator Pedal Position 1";
BA_ "GenSigTimeoutTime_ADCU" SG_ 2364539648 AccPedPos1 500;
BA_ "GenSigTimeoutTime_EBS" SG_ 2364539648 AccPedPos1 500;
BA_ "GenSigTimeoutTime_EBS___" SG_ 2364539648 AccPedPos1 500;
BA_ "GenSigTimeoutTime_Ecolife2" SG_ 2364539648 AccPedPos1 500;
BA_ "GenSigTimeoutTime_FMS4" SG_ 2364539648 AccPedPos1 500;
BA_ "GenSigTimeoutTime_IRCS" SG_ 2364539648 AccPedPos1 500;
BA_ "GenSigTimeoutTime_NBM" SG_ 2364539648 AccPedPos1 500;
BA_ "GenSigTimeoutTime_NBM___" SG_ 2364539648 AccPedPos1 500;
BA_ "GenSigTimeoutTime_PCM" SG_ 2364539648 AccPedPos1 500;
BA_ "GenSigTimeoutTime_SGW__" SG_ 2364539648 AccPedPos1 500;
BA_ "SPN" SG_ 2364539648 AccPedPos1 91;
BA_ "SigType" SG_ 2364539648 AccPedPos1 1;
BA_ "CI_ParId" SG_ 2364539648 EngPcLoadAtCurSpeed "92";
BA_ "CI_SigId" SG_ 2364539648 EngPcLoadAtCurSpeed 869;
BA_ "CI_SigName" SG_ 2364539648 EngPcLoadAtCurSpeed "Engine Percent Load At Current Speed";
BA_ "GenSigTimeoutTime_ADCU" SG_ 2364539648 EngPcLoadAtCurSpeed 500;
BA_ "GenSigTimeoutTime_Ecolife2" SG_ 2364539648 EngPcLoadAtCurSpeed 500;
BA_ "GenSigTimeoutTime_PCM" SG_ 2364539648 EngPcLoadAtCurSpeed 500;
BA_ "GenSigTimeoutTime_SGW__" SG_ 2364539648 EngPcLoadAtCurSpeed 500;
BA_ "GenSigTimeoutTime_VCM_" SG_ 2364539648 EngPcLoadAtCurSpeed 500;
BA_ "GenSigTimeoutTime_VCM__" SG_ 2364539648 EngPcLoadAtCurSpeed 500;
BA_ "SPN" SG_ 2364539648 EngPcLoadAtCurSpeed 92;
BA_ "SigType" SG_ 2364539648 EngPcLoadAtCurSpeed 1;
BA_ "CI_ParId" SG_ 2364539776 AccPedPos1_0CF00380 "91";
BA_ "CI_SigId" SG_ 2364539776 AccPedPos1_0CF00380 883;
BA_ "CI_SigName" SG_ 2364539776 AccPedPos1_0CF00380 "Accelerator Pedal Position 1";
BA_ "GenSigTimeoutTime_ADCU" SG_ 2364539776 AccPedPos1_0CF00380 500;
BA_ "GenSigTimeoutTime_EBS_" SG_ 2364539776 AccPedPos1_0CF00380 500;
BA_ "GenSigTimeoutTime_EBS__" SG_ 2364539776 AccPedPos1_0CF00380 500;
BA_ "GenSigTimeoutTime_FMS4" SG_ 2364539776 AccPedPos1_0CF00380 500;
BA_ "GenSigTimeoutTime_NBM_" SG_ 2364539776 AccPedPos1_0CF00380 500;
BA_ "GenSigTimeoutTime_NBM__" SG_ 2364539776 AccPedPos1_0CF00380 500;
BA_ "GenSigTimeoutTime_PCM" SG_ 2364539776 AccPedPos1_0CF00380 500;
BA_ "GenSigTimeoutTime_SGW__" SG_ 2364539776 AccPedPos1_0CF00380 500;
BA_ "SPN" SG_ 2364539776 AccPedPos1_0CF00380 91;
BA_ "SigType" SG_ 2364539776 AccPedPos1_0CF00380 1;
BA_ "CI_ParId" SG_ 2364539776 EngPcLoadAtCurSpeed_0CF00380 "92";
BA_ "CI_SigId" SG_ 2364539776 EngPcLoadAtCurSpeed_0CF00380 884;
BA_ "CI_SigName" SG_ 2364539776 EngPcLoadAtCurSpeed_0CF00380 "Engine Percent Load At Current Speed";
BA_ "GenSigTimeoutTime_ADCU" SG_ 2364539776 EngPcLoadAtCurSpeed_0CF00380 500;
BA_ "GenSigTimeoutTime_EBS_" SG_ 2364539776 EngPcLoadAtCurSpeed_0CF00380 500;
BA_ "GenSigTimeoutTime_EBS__" SG_ 2364539776 EngPcLoadAtCurSpeed_0CF00380 500;
BA_ "GenSigTimeoutTime_FMS4" SG_ 2364539776 EngPcLoadAtCurSpeed_0CF00380 500;
BA_ "GenSigTimeoutTime_PCM" SG_ 2364539776 EngPcLoadAtCurSpeed_0CF00380 500;
BA_ "GenSigTimeoutTime_SGW__" SG_ 2364539776 EngPcLoadAtCurSpeed_0CF00380 500;
BA_ "SPN" SG_ 2364539776 EngPcLoadAtCurSpeed_0CF00380 92;
BA_ "SigType" SG_ 2364539776 EngPcLoadAtCurSpeed_0CF00380 1;
BA_ "CI_ParId" SG_ 2364539776 ActMaxAvEngPcTrq "3357";
BA_ "CI_SigId" SG_ 2364539776 ActMaxAvEngPcTrq 889;
BA_ "CI_SigName" SG_ 2364539776 ActMaxAvEngPcTrq "Actual Maximum Available Engine - Percent Torque";
BA_ "GenSigTimeoutTime_PCM" SG_ 2364539776 ActMaxAvEngPcTrq 500;
BA_ "GenSigTimeoutTime_SGW__" SG_ 2364539776 ActMaxAvEngPcTrq 500;
BA_ "GenSigTimeoutTime_VCU" SG_ 2364539776 ActMaxAvEngPcTrq 500;
BA_ "SPN" SG_ 2364539776 ActMaxAvEngPcTrq 3357;
BA_ "SigType" SG_ 2364539776 ActMaxAvEngPcTrq 1;
BA_ "CI_ParId" SG_ 2566840064 NomFrictPcTrq "514";
BA_ "CI_SigId" SG_ 2566840064 NomFrictPcTrq 932;
BA_ "CI_SigName" SG_ 2566840064 NomFrictPcTrq "Nominal Friction - Percent Torque";
BA_ "GenSigTimeoutTime_ADCU" SG_ 2566840064 NomFrictPcTrq 1250;
BA_ "GenSigTimeoutTime_EBS" SG_ 2566840064 NomFrictPcTrq 1250;
BA_ "GenSigTimeoutTime_EBS___" SG_ 2566840064 NomFrictPcTrq 1250;
BA_ "GenSigTimeoutTime_Ecolife2" SG_ 2566840064 NomFrictPcTrq 1250;
BA_ "GenSigTimeoutTime_PCM" SG_ 2566840064 NomFrictPcTrq 1250;
BA_ "GenSigTimeoutTime_SGW__" SG_ 2566840064 NomFrictPcTrq 1250;
BA_ "GenSigTimeoutTime_VCM_" SG_ 2566840064 NomFrictPcTrq 1250;
BA_ "GenSigTimeoutTime_VCM__" SG_ 2566840064 NomFrictPcTrq 1250;
BA_ "SPN" SG_ 2566840064 NomFrictPcTrq 514;
BA_ "SigType" SG_ 2566840064 NomFrictPcTrq 1;
BA_ "CI_ParId" SG_ 2566840192 NomFrictPcTrq_18FEDF80 "514";
BA_ "CI_SigId" SG_ 2566840192 NomFrictPcTrq_18FEDF80 943;
BA_ "CI_SigName" SG_ 2566840192 NomFrictPcTrq_18FEDF80 "Nominal Friction - Percent Torque";
BA_ "GenSigTimeoutTime_ADCU" SG_ 2566840192 NomFrictPcTrq_18FEDF80 1000;
BA_ "GenSigTimeoutTime_EBS_" SG_ 2566840192 NomFrictPcTrq_18FEDF80 1000;
BA_ "GenSigTimeoutTime_EBS__" SG_ 2566840192 NomFrictPcTrq_18FEDF80 1000;
BA_ "GenSigTimeoutTime_MulticII" SG_ 2566840192 NomFrictPcTrq_18FEDF80 1000;
BA_ "GenSigTimeoutTime_PCM" SG_ 2566840192 NomFrictPcTrq_18FEDF80 1000;
BA_ "GenSigTimeoutTime_SGW__" SG_ 2566840192 NomFrictPcTrq_18FEDF80 1000;
BA_ "GenSigTimeoutTime_VCU" SG_ 2566840192 NomFrictPcTrq_18FEDF80 1000;
BA_ "SPN" SG_ 2566840192 NomFrictPcTrq_18FEDF80 514;
BA_ "SigType" SG_ 2566840192 NomFrictPcTrq_18FEDF80 1;
BA_ "CI_ParId" SG_ 2566844160 EngFuelDelPrs "94";
BA_ "CI_SigId" SG_ 2566844160 EngFuelDelPrs 1077;
BA_ "CI_SigName" SG_ 2566844160 EngFuelDelPrs "Engine Fuel Delivery Pressure";
BA_ "GenSigTimeoutTime_FMS4" SG_ 2566844160 EngFuelDelPrs 2500;
BA_ "GenSigTimeoutTime_MulticS__" SG_ 2566844160 EngFuelDelPrs 2500;
BA_ "GenSigTimeoutTime_NBM" SG_ 2566844160 EngFuelDelPrs 2500;
BA_ "GenSigTimeoutTime_NBM___" SG_ 2566844160 EngFuelDelPrs 2500;
BA_ "GenSigTimeoutTime_PCM" SG_ 2566844160 EngFuelDelPrs 2500;
BA_ "GenSigTimeoutTime_SGW__" SG_ 2566844160 EngFuelDelPrs 2500;
BA_ "GenSigTimeoutTime_VCM__" SG_ 2566844160 EngFuelDelPrs 2500;
BA_ "SPN" SG_ 2566844160 EngFuelDelPrs 94;
BA_ "SigType" SG_ 2566844160 EngFuelDelPrs 1;
BA_ "CI_ParId" SG_ 2566844160 EngOilPrs1 "100";
BA_ "CI_SigId" SG_ 2566844160 EngOilPrs1 1081;
BA_ "CI_SigName" SG_ 2566844160 EngOilPrs1 "Engine Oil Pressure 1";
BA_ "GenSigTimeoutTime_FMS4" SG_ 2566844160 EngOilPrs1 2500;
BA_ "GenSigTimeoutTime_MulticS" SG_ 2566844160 EngOilPrs1 2500;
BA_ "GenSigTimeoutTime_MulticS__" SG_ 2566844160 EngOilPrs1 2500;
BA_ "GenSigTimeoutTime_NBM" SG_ 2566844160 EngOilPrs1 2500;
BA_ "GenSigTimeoutTime_NBM___" SG_ 2566844160 EngOilPrs1 2500;
BA_ "GenSigTimeoutTime_PCM" SG_ 2566844160 EngOilPrs1 2500;
BA_ "GenSigTimeoutTime_SGW__" SG_ 2566844160 EngOilPrs1 2500;
BA_ "GenSigTimeoutTime_VCM_" SG_ 2566844160 EngOilPrs1 2500;
BA_ "GenSigTimeoutTime_VCM__" SG_ 2566844160 EngOilPrs1 2500;
BA_ "SPN" SG_ 2566844160 EngOilPrs1 100;
BA_ "SigType" SG_ 2566844160 EngOilPrs1 1;
BA_ "CI_ParId" SG_ 2566885210 Modefb "IB105";
BA_ "CI_SigId" SG_ 2566885210 Modefb 1366;
BA_ "CI_SigName" SG_ 2566885210 Modefb "ModeFB";
BA_ "GenSigTimeoutTime_PCM" SG_ 2566885210 Modefb 500;
BA_ "GenSigTimeoutTime_VCU" SG_ 2566885210 Modefb 500;
BA_ "CI_ParId" SG_ 2566898290 EngStopSw "IS003";
BA_ "CI_SigId" SG_ 2566898290 EngStopSw 3937;
BA_ "CI_SigName" SG_ 2566898290 EngStopSw "Engine Stop Switch";
BA_ "GenSigTimeoutTime_DiwaNXT" SG_ 2566898290 EngStopSw 500;
BA_ "GenSigTimeoutTime_DiwaNXT_MH" SG_ 2566898290 EngStopSw 500;
BA_ "GenSigTimeoutTime_PCM" SG_ 2566898290 EngStopSw 500;
BA_ "GenSigTimeoutTime_SGW__" SG_ 2566898290 EngStopSw 500;
BA_ "SigType" SG_ 2566898290 EngStopSw 4;
BA_ "CI_ParId" SG_ 2565865488 RetTrqMode "900";
BA_ "CI_SigId" SG_ 2565865488 RetTrqMode 408;
BA_ "CI_SigName" SG_ 2565865488 RetTrqMode "Retarder Torque Mode";
BA_ "GenSigTimeoutTime_ADCU" SG_ 2565865488 RetTrqMode 500;
BA_ "GenSigTimeoutTime_EBS_" SG_ 2565865488 RetTrqMode 500;
BA_ "GenSigTimeoutTime_FMS4" SG_ 2565865488 RetTrqMode 500;
BA_ "GenSigTimeoutTime_MulticII" SG_ 2565865488 RetTrqMode 500;
BA_ "GenSigTimeoutTime_MulticS" SG_ 2565865488 RetTrqMode 500;
BA_ "GenSigTimeoutTime_MulticS_" SG_ 2565865488 RetTrqMode 500;
BA_ "GenSigTimeoutTime_MulticS__" SG_ 2565865488 RetTrqMode 500;
BA_ "GenSigTimeoutTime_PCM" SG_ 2565865488 RetTrqMode 500;
BA_ "GenSigTimeoutTime_SGW__" SG_ 2565865488 RetTrqMode 500;
BA_ "GenSigTimeoutTime_VCM" SG_ 2565865488 RetTrqMode 500;
BA_ "GenSigTimeoutTime_VCU" SG_ 2565865488 RetTrqMode 500;
BA_ "SPN" SG_ 2565865488 RetTrqMode 900;
BA_ "CI_ParId" SG_ 2565865488 ActRetPcTrq "520";
BA_ "CI_SigId" SG_ 2565865488 ActRetPcTrq 411;
BA_ "CI_SigName" SG_ 2565865488 ActRetPcTrq "Actual Retarder - Percent Torque";
BA_ "GenSigTimeoutTime_ADCU" SG_ 2565865488 ActRetPcTrq 500;
BA_ "GenSigTimeoutTime_EBS" SG_ 2565865488 ActRetPcTrq 500;
BA_ "GenSigTimeoutTime_EBS_" SG_ 2565865488 ActRetPcTrq 500;
BA_ "GenSigTimeoutTime_EBS__" SG_ 2565865488 ActRetPcTrq 500;
BA_ "GenSigTimeoutTime_EBS___" SG_ 2565865488 ActRetPcTrq 500;
BA_ "GenSigTimeoutTime_FMS4" SG_ 2565865488 ActRetPcTrq 500;
BA_ "GenSigTimeoutTime_MulticII" SG_ 2565865488 ActRetPcTrq 500;
BA_ "GenSigTimeoutTime_MulticS" SG_ 2565865488 ActRetPcTrq 500;
BA_ "GenSigTimeoutTime_MulticS_" SG_ 2565865488 ActRetPcTrq 500;
BA_ "GenSigTimeoutTime_MulticS__" SG_ 2565865488 ActRetPcTrq 500;
BA_ "GenSigTimeoutTime_NBM" SG_ 2565865488 ActRetPcTrq 500;
BA_ "GenSigTimeoutTime_NBM_" SG_ 2565865488 ActRetPcTrq 500;
BA_ "GenSigTimeoutTime_NBM___" SG_ 2565865488 ActRetPcTrq 500;
BA_ "GenSigTimeoutTime_PCM" SG_ 2565865488 ActRetPcTrq 500;
BA_ "GenSigTimeoutTime_SGW__" SG_ 2565865488 ActRetPcTrq 500;
BA_ "GenSigTimeoutTime_VCM" SG_ 2565865488 ActRetPcTrq 500;
BA_ "GenSigTimeoutTime_VCU" SG_ 2565865488 ActRetPcTrq 500;
BA_ "SPN" SG_ 2565865488 ActRetPcTrq 520;
BA_ "SigType" SG_ 2565865488 ActRetPcTrq 1;
BA_ "CI_ParId" SG_ 2565865488 RetSelNonEng "1716";
BA_ "CI_SigId" SG_ 2565865488 RetSelNonEng 419;
BA_ "CI_SigName" SG_ 2565865488 RetSelNonEng "Retarder Selection, non-engine";
BA_ "GenSigTimeoutTime_FMS4" SG_ 2565865488 RetSelNonEng 500;
BA_ "GenSigTimeoutTime_PCM" SG_ 2565865488 RetSelNonEng 500;
BA_ "GenSigTimeoutTime_SGW__" SG_ 2565865488 RetSelNonEng 500;
BA_ "GenSigTimeoutTime_VCM" SG_ 2565865488 RetSelNonEng 500;
BA_ "SPN" SG_ 2565865488 RetSelNonEng 1716;
BA_ "SigType" SG_ 2565865488 RetSelNonEng 1;
BA_ "CI_ParId" SG_ 2565865487 ActRetPcTrq_18F0000F "520";
BA_ "CI_SigId" SG_ 2565865487 ActRetPcTrq_18F0000F 396;
BA_ "CI_SigName" SG_ 2565865487 ActRetPcTrq_18F0000F "Actual Retarder - Percent Torque";
BA_ "GenSigTimeoutTime_ADCU" SG_ 2565865487 ActRetPcTrq_18F0000F 500;
BA_ "GenSigTimeoutTime_EBS" SG_ 2565865487 ActRetPcTrq_18F0000F 500;
BA_ "GenSigTimeoutTime_EBS___" SG_ 2565865487 ActRetPcTrq_18F0000F 500;
BA_ "GenSigTimeoutTime_Ecolife2" SG_ 2565865487 ActRetPcTrq_18F0000F 500;
BA_ "GenSigTimeoutTime_MulticS" SG_ 2565865487 ActRetPcTrq_18F0000F 500;
BA_ "GenSigTimeoutTime_MulticS__" SG_ 2565865487 ActRetPcTrq_18F0000F 500;
BA_ "GenSigTimeoutTime_NBM" SG_ 2565865487 ActRetPcTrq_18F0000F 500;
BA_ "GenSigTimeoutTime_PCM" SG_ 2565865487 ActRetPcTrq_18F0000F 500;
BA_ "GenSigTimeoutTime_SGW__" SG_ 2565865487 ActRetPcTrq_18F0000F 500;
BA_ "GenSigTimeoutTime_VCM_" SG_ 2565865487 ActRetPcTrq_18F0000F 500;
BA_ "GenSigTimeoutTime_VCM__" SG_ 2565865487 ActRetPcTrq_18F0000F 500;
BA_ "SPN" SG_ 2565865487 ActRetPcTrq_18F0000F 520;
BA_ "SigType" SG_ 2565865487 ActRetPcTrq_18F0000F 1;
BA_ "CI_ParId" SG_ 2566843904 EngCoolTemp "110";
BA_ "CI_SigId" SG_ 2566843904 EngCoolTemp 1070;
BA_ "CI_SigName" SG_ 2566843904 EngCoolTemp "Engine Coolant Temperature";
BA_ "GenSigTimeoutTime_ADCU" SG_ 2566843904 EngCoolTemp 5000;
BA_ "GenSigTimeoutTime_FCCU_" SG_ 2566843904 EngCoolTemp 5000;
BA_ "GenSigTimeoutTime_FMS4" SG_ 2566843904 EngCoolTemp 5000;
BA_ "GenSigTimeoutTime_MulticS" SG_ 2566843904 EngCoolTemp 5000;
BA_ "GenSigTimeoutTime_MulticS__" SG_ 2566843904 EngCoolTemp 5000;
BA_ "GenSigTimeoutTime_NBM" SG_ 2566843904 EngCoolTemp 5000;
BA_ "GenSigTimeoutTime_NBM___" SG_ 2566843904 EngCoolTemp 5000;
BA_ "GenSigTimeoutTime_PCM" SG_ 2566843904 EngCoolTemp 5000;
BA_ "GenSigTimeoutTime_SGW__" SG_ 2566843904 EngCoolTemp 5000;
BA_ "GenSigTimeoutTime_VCM_" SG_ 2566843904 EngCoolTemp 5000;
BA_ "GenSigTimeoutTime_VCM__" SG_ 2566843904 EngCoolTemp 5000;
BA_ "SPN" SG_ 2566843904 EngCoolTemp 110;
BA_ "SigType" SG_ 2566843904 EngCoolTemp 1;
BA_ "CI_ParId" SG_ 2566843904 EngFuel1Temp1 "174";
BA_ "CI_SigId" SG_ 2566843904 EngFuel1Temp1 1071;
BA_ "CI_SigName" SG_ 2566843904 EngFuel1Temp1 "Engine Fuel 1 Temperature 1";
BA_ "GenSigTimeoutTime_NBM" SG_ 2566843904 EngFuel1Temp1 5000;
BA_ "GenSigTimeoutTime_NBM___" SG_ 2566843904 EngFuel1Temp1 5000;
BA_ "GenSigTimeoutTime_PCM" SG_ 2566843904 EngFuel1Temp1 5000;
BA_ "GenSigTimeoutTime_SGW__" SG_ 2566843904 EngFuel1Temp1 5000;
BA_ "GenSigTimeoutTime_VCM_" SG_ 2566843904 EngFuel1Temp1 5000;
BA_ "GenSigTimeoutTime_VCM__" SG_ 2566843904 EngFuel1Temp1 5000;
BA_ "SPN" SG_ 2566843904 EngFuel1Temp1 174;
BA_ "SigType" SG_ 2566843904 EngFuel1Temp1 1;
BA_ "CI_ParId" SG_ 2566843904 EngOilTemp1 "175";
BA_ "CI_SigId" SG_ 2566843904 EngOilTemp1 1072;
BA_ "CI_SigName" SG_ 2566843904 EngOilTemp1 "Engine Oil Temperature 1";
BA_ "GenSigTimeoutTime_NBM" SG_ 2566843904 EngOilTemp1 5000;
BA_ "GenSigTimeoutTime_PCM" SG_ 2566843904 EngOilTemp1 5000;
BA_ "GenSigTimeoutTime_SGW__" SG_ 2566843904 EngOilTemp1 5000;
BA_ "GenSigTimeoutTime_VCM_" SG_ 2566843904 EngOilTemp1 5000;
BA_ "GenSigTimeoutTime_VCM__" SG_ 2566843904 EngOilTemp1 5000;
BA_ "SPN" SG_ 2566843904 EngOilTemp1 175;
BA_ "SigType" SG_ 2566843904 EngOilTemp1 1;
BA_ "CI_ParId" SG_ 2364539395 TransmDrvlEngd "560";
BA_ "CI_SigId" SG_ 2364539395 TransmDrvlEngd 530;
BA_ "CI_SigName" SG_ 2364539395 TransmDrvlEngd "Transmission Driveline Engaged";
BA_ "GenSigTimeoutTime_ADCU" SG_ 2364539395 TransmDrvlEngd 500;
BA_ "GenSigTimeoutTime_EBS" SG_ 2364539395 TransmDrvlEngd 500;
BA_ "GenSigTimeoutTime_EBS_" SG_ 2364539395 TransmDrvlEngd 500;
BA_ "GenSigTimeoutTime_EBS__" SG_ 2364539395 TransmDrvlEngd 500;
BA_ "GenSigTimeoutTime_EBS___" SG_ 2364539395 TransmDrvlEngd 500;
BA_ "GenSigTimeoutTime_FMS4" SG_ 2364539395 TransmDrvlEngd 500;
BA_ "GenSigTimeoutTime_MD1_D" SG_ 2364539395 TransmDrvlEngd 500;
BA_ "GenSigTimeoutTime_MD1_G" SG_ 2364539395 TransmDrvlEngd 500;
BA_ "GenSigTimeoutTime_PCM" SG_ 2364539395 TransmDrvlEngd 500;
BA_ "GenSigTimeoutTime_SGW__" SG_ 2364539395 TransmDrvlEngd 500;
BA_ "GenSigTimeoutTime_VCM" SG_ 2364539395 TransmDrvlEngd 500;
BA_ "GenSigTimeoutTime_VCU" SG_ 2364539395 TransmDrvlEngd 500;
BA_ "SPN" SG_ 2364539395 TransmDrvlEngd 560;
BA_ "SigType" SG_ 2364539395 TransmDrvlEngd 4;
BA_ "CI_ParId" SG_ 2364539395 TransmOutSpeed "191";
BA_ "CI_SigId" SG_ 2364539395 TransmOutSpeed 534;
BA_ "CI_SigName" SG_ 2364539395 TransmOutSpeed "Transmission 1 Output Shaft Speed";
BA_ "GenSigTimeoutTime_ADCU" SG_ 2364539395 TransmOutSpeed 500;
BA_ "GenSigTimeoutTime_FMS4" SG_ 2364539395 TransmOutSpeed 500;
BA_ "GenSigTimeoutTime_MD1_D" SG_ 2364539395 TransmOutSpeed 500;
BA_ "GenSigTimeoutTime_MD1_G" SG_ 2364539395 TransmOutSpeed 500;
BA_ "GenSigTimeoutTime_PCM" SG_ 2364539395 TransmOutSpeed 500;
BA_ "GenSigTimeoutTime_SGW__" SG_ 2364539395 TransmOutSpeed 500;
BA_ "GenSigTimeoutTime_VCM" SG_ 2364539395 TransmOutSpeed 500;
BA_ "GenSigTimeoutTime_VCU" SG_ 2364539395 TransmOutSpeed 500;
BA_ "SPN" SG_ 2364539395 TransmOutSpeed 191;
BA_ "SigType" SG_ 2364539395 TransmOutSpeed 1;
BA_ "CI_ParId" SG_ 2364539395 PcCltSlip "522";
BA_ "CI_SigId" SG_ 2364539395 PcCltSlip 535;
BA_ "CI_SigName" SG_ 2364539395 PcCltSlip "Percent Clutch Slip";
BA_ "GenSigTimeoutTime_ADCU" SG_ 2364539395 PcCltSlip 500;
BA_ "GenSigTimeoutTime_FMS4" SG_ 2364539395 PcCltSlip 500;
BA_ "GenSigTimeoutTime_MD1_D" SG_ 2364539395 PcCltSlip 500;
BA_ "GenSigTimeoutTime_MD1_G" SG_ 2364539395 PcCltSlip 500;
BA_ "GenSigTimeoutTime_PCM" SG_ 2364539395 PcCltSlip 500;
BA_ "GenSigTimeoutTime_SGW__" SG_ 2364539395 PcCltSlip 500;
BA_ "GenSigTimeoutTime_VCM" SG_ 2364539395 PcCltSlip 500;
BA_ "SPN" SG_ 2364539395 PcCltSlip 522;
BA_ "SigType" SG_ 2364539395 PcCltSlip 1;
BA_ "CI_ParId" SG_ 2364539395 TransmInSpeed "161";
BA_ "CI_SigId" SG_ 2364539395 TransmInSpeed 539;
BA_ "CI_SigName" SG_ 2364539395 TransmInSpeed "Transmission 1 Input Shaft Speed";
BA_ "GenSigTimeoutTime_EBS" SG_ 2364539395 TransmInSpeed 500;
BA_ "GenSigTimeoutTime_EBS_" SG_ 2364539395 TransmInSpeed 500;
BA_ "GenSigTimeoutTime_EBS__" SG_ 2364539395 TransmInSpeed 500;
BA_ "GenSigTimeoutTime_EBS___" SG_ 2364539395 TransmInSpeed 500;
BA_ "GenSigTimeoutTime_FMS4" SG_ 2364539395 TransmInSpeed 500;
BA_ "GenSigTimeoutTime_PCM" SG_ 2364539395 TransmInSpeed 500;
BA_ "GenSigTimeoutTime_SGW__" SG_ 2364539395 TransmInSpeed 500;
BA_ "GenSigTimeoutTime_VCM" SG_ 2364539395 TransmInSpeed 500;
BA_ "GenSigTimeoutTime_VCU" SG_ 2364539395 TransmInSpeed 500;
BA_ "SPN" SG_ 2364539395 TransmInSpeed 161;
BA_ "SigType" SG_ 2364539395 TransmInSpeed 1;
BA_ "CI_ParId" SG_ 2565866755 TransmSelGear "524";
BA_ "CI_SigId" SG_ 2565866755 TransmSelGear 542;
BA_ "CI_SigName" SG_ 2565866755 TransmSelGear "Transmission Selected Gear";
BA_ "GenSigTimeoutTime_ACU" SG_ 2565866755 TransmSelGear 500;
BA_ "GenSigTimeoutTime_ADCU" SG_ 2565866755 TransmSelGear 500;
BA_ "GenSigTimeoutTime_FMS4" SG_ 2565866755 TransmSelGear 500;
BA_ "GenSigTimeoutTime_MD1_D" SG_ 2565866755 TransmSelGear 500;
BA_ "GenSigTimeoutTime_MD1_G" SG_ 2565866755 TransmSelGear 500;
BA_ "GenSigTimeoutTime_MulticII" SG_ 2565866755 TransmSelGear 500;
BA_ "GenSigTimeoutTime_MulticS" SG_ 2565866755 TransmSelGear 500;
BA_ "GenSigTimeoutTime_MulticS_" SG_ 2565866755 TransmSelGear 500;
BA_ "GenSigTimeoutTime_MulticS__" SG_ 2565866755 TransmSelGear 500;
BA_ "GenSigTimeoutTime_NBM_" SG_ 2565866755 TransmSelGear 500;
BA_ "GenSigTimeoutTime_NBM__" SG_ 2565866755 TransmSelGear 500;
BA_ "GenSigTimeoutTime_NBM___" SG_ 2565866755 TransmSelGear 500;
BA_ "GenSigTimeoutTime_PCM" SG_ 2565866755 TransmSelGear 500;
BA_ "GenSigTimeoutTime_SGW__" SG_ 2565866755 TransmSelGear 500;
BA_ "GenSigTimeoutTime_VCM" SG_ 2565866755 TransmSelGear 500;
BA_ "GenSigTimeoutTime_VCU" SG_ 2565866755 TransmSelGear 500;
BA_ "SPN" SG_ 2565866755 TransmSelGear 524;
BA_ "SigType" SG_ 2565866755 TransmSelGear 1;
BA_ "CI_ParId" SG_ 2565866755 TransmCurGear "523";
BA_ "CI_SigId" SG_ 2565866755 TransmCurGear 544;
BA_ "CI_SigName" SG_ 2565866755 TransmCurGear "Transmission Current Gear";
BA_ "GenSigTimeoutTime_ACU" SG_ 2565866755 TransmCurGear 500;
BA_ "GenSigTimeoutTime_ADCU" SG_ 2565866755 TransmCurGear 500;
BA_ "GenSigTimeoutTime_EBS" SG_ 2565866755 TransmCurGear 500;
BA_ "GenSigTimeoutTime_EBS_" SG_ 2565866755 TransmCurGear 500;
BA_ "GenSigTimeoutTime_EBS__" SG_ 2565866755 TransmCurGear 500;
BA_ "GenSigTimeoutTime_EBS___" SG_ 2565866755 TransmCurGear 500;
BA_ "GenSigTimeoutTime_FMS4" SG_ 2565866755 TransmCurGear 500;
BA_ "GenSigTimeoutTime_MD1_D" SG_ 2565866755 TransmCurGear 500;
BA_ "GenSigTimeoutTime_MD1_G" SG_ 2565866755 TransmCurGear 500;
BA_ "GenSigTimeoutTime_MulticII" SG_ 2565866755 TransmCurGear 500;
BA_ "GenSigTimeoutTime_MulticS" SG_ 2565866755 TransmCurGear 500;
BA_ "GenSigTimeoutTime_MulticS_" SG_ 2565866755 TransmCurGear 500;
BA_ "GenSigTimeoutTime_MulticS__" SG_ 2565866755 TransmCurGear 500;
BA_ "GenSigTimeoutTime_NBM" SG_ 2565866755 TransmCurGear 500;
BA_ "GenSigTimeoutTime_NBM_" SG_ 2565866755 TransmCurGear 500;
BA_ "GenSigTimeoutTime_NBM__" SG_ 2565866755 TransmCurGear 500;
BA_ "GenSigTimeoutTime_NBM___" SG_ 2565866755 TransmCurGear 500;
BA_ "GenSigTimeoutTime_PCM" SG_ 2565866755 TransmCurGear 500;
BA_ "GenSigTimeoutTime_SGW__" SG_ 2565866755 TransmCurGear 500;
BA_ "GenSigTimeoutTime_VCM" SG_ 2565866755 TransmCurGear 500;
BA_ "GenSigTimeoutTime_VCU" SG_ 2565866755 TransmCurGear 500;
BA_ "SPN" SG_ 2565866755 TransmCurGear 523;
BA_ "SigType" SG_ 2565866755 TransmCurGear 1;
BA_ "CI_ParId" SG_ 2566826755 HighPossGear "1115";
BA_ "CI_SigId" SG_ 2566826755 HighPossGear 566;
BA_ "CI_SigName" SG_ 2566826755 HighPossGear "Highest Possible Gear";
BA_ "GenSigTimeoutTime_MulticS" SG_ 2566826755 HighPossGear 1250;
BA_ "GenSigTimeoutTime_PCM" SG_ 2566826755 HighPossGear 1250;
BA_ "GenSigTimeoutTime_SGW__" SG_ 2566826755 HighPossGear 1250;
BA_ "SPN" SG_ 2566826755 HighPossGear 1115;
BA_ "SigType" SG_ 2566826755 HighPossGear 1;
BA_ "CI_ParId" SG_ 2566826755 LowPossGear "1114";
BA_ "CI_SigId" SG_ 2566826755 LowPossGear 567;
BA_ "CI_SigName" SG_ 2566826755 LowPossGear "Lowest Possible Gear";
BA_ "GenSigTimeoutTime_MulticS" SG_ 2566826755 LowPossGear 1250;
BA_ "GenSigTimeoutTime_PCM" SG_ 2566826755 LowPossGear 1250;
BA_ "GenSigTimeoutTime_SGW__" SG_ 2566826755 LowPossGear 1250;
BA_ "SPN" SG_ 2566826755 LowPossGear 1114;
BA_ "SigType" SG_ 2566826755 LowPossGear 1;
BA_ "CI_ParId" SG_ 2364541955 TransmTrqConvRatio "3030";
BA_ "CI_SigId" SG_ 2364541955 TransmTrqConvRatio 626;
BA_ "CI_SigName" SG_ 2364541955 TransmTrqConvRatio "Transmission Torque Converter Ratio";
BA_ "GenSigTimeoutTime_EBS" SG_ 2364541955 TransmTrqConvRatio 500;
BA_ "GenSigTimeoutTime_EBS___" SG_ 2364541955 TransmTrqConvRatio 500;
BA_ "GenSigTimeoutTime_PCM" SG_ 2364541955 TransmTrqConvRatio 500;
BA_ "GenSigTimeoutTime_SGW__" SG_ 2364541955 TransmTrqConvRatio 500;
BA_ "SPN" SG_ 2364541955 TransmTrqConvRatio 3030;
BA_ "CI_ParId" SG_ 2566831393 FanSpeed "1639";
BA_ "CI_SigId" SG_ 2566831393 FanSpeed 2183;
BA_ "CI_SigName" SG_ 2566831393 FanSpeed "Fan Speed";
BA_ "GenSigTimeoutTime_PCM" SG_ 2566831393 FanSpeed 5000;
BA_ "GenSigTimeoutTime_SGW__" SG_ 2566831393 FanSpeed 5000;
BA_ "SPN" SG_ 2566831393 FanSpeed 1639;
BA_ "SigType" SG_ 2566831393 FanSpeed 1;
BA_ "CI_ParId" SG_ 2431649694 LaneDepImmRh "1701";
BA_ "CI_SigId" SG_ 2431649694 LaneDepImmRh 3107;
BA_ "CI_SigName" SG_ 2431649694 LaneDepImmRh "Lane Departure Imminent, Right Side";
BA_ "GenSigSendType" SG_ 2431649694 LaneDepImmRh 6;
BA_ "GenSigTimeoutTime_MulticII" SG_ 2431649694 LaneDepImmRh 500;
BA_ "GenSigTimeoutTime_MulticS" SG_ 2431649694 LaneDepImmRh 500;
BA_ "GenSigTimeoutTime_MulticS_" SG_ 2431649694 LaneDepImmRh 500;
BA_ "GenSigTimeoutTime_MulticS__" SG_ 2431649694 LaneDepImmRh 500;
BA_ "GenSigTimeoutTime_PCM" SG_ 2431649694 LaneDepImmRh 500;
BA_ "GenSigTimeoutTime_SGW__" SG_ 2431649694 LaneDepImmRh 500;
BA_ "SPN" SG_ 2431649694 LaneDepImmRh 1701;
BA_ "SigType" SG_ 2431649694 LaneDepImmRh 4;
BA_ "CI_ParId" SG_ 2431649694 LaneDepImmLh "1700";
BA_ "CI_SigId" SG_ 2431649694 LaneDepImmLh 3108;
BA_ "CI_SigName" SG_ 2431649694 LaneDepImmLh "Lane Departure Imminent, Left Side";
BA_ "GenSigSendType" SG_ 2431649694 LaneDepImmLh 6;
BA_ "GenSigTimeoutTime_MulticII" SG_ 2431649694 LaneDepImmLh 500;
BA_ "GenSigTimeoutTime_MulticS" SG_ 2431649694 LaneDepImmLh 500;
BA_ "GenSigTimeoutTime_MulticS_" SG_ 2431649694 LaneDepImmLh 500;
BA_ "GenSigTimeoutTime_MulticS__" SG_ 2431649694 LaneDepImmLh 500;
BA_ "GenSigTimeoutTime_PCM" SG_ 2431649694 LaneDepImmLh 500;
BA_ "GenSigTimeoutTime_SGW__" SG_ 2431649694 LaneDepImmLh 500;
BA_ "SPN" SG_ 2431649694 LaneDepImmLh 1700;
BA_ "SigType" SG_ 2431649694 LaneDepImmLh 4;
BA_ "CI_ParId" SG_ 2566806430 LaneDepIndEnaSts "1702";
BA_ "CI_SigId" SG_ 2566806430 LaneDepIndEnaSts 3121;
BA_ "CI_SigName" SG_ 2566806430 LaneDepIndEnaSts "Lane Departure Indication Enable Status";
BA_ "GenSigTimeoutTime_PCM" SG_ 2566806430 LaneDepIndEnaSts 500;
BA_ "GenSigTimeoutTime_SGW__" SG_ 2566806430 LaneDepIndEnaSts 500;
BA_ "GenSigTimeoutTime_VCM" SG_ 2566806430 LaneDepIndEnaSts 500;
BA_ "SPN" SG_ 2566806430 LaneDepIndEnaSts 1702;
BA_ "SigType" SG_ 2566806430 LaneDepIndEnaSts 4;
BA_ "CI_ParId" SG_ 2566806430 DrivAlertLev "7474";
BA_ "CI_SigId" SG_ 2566806430 DrivAlertLev 3122;
BA_ "CI_SigName" SG_ 2566806430 DrivAlertLev "Driver Alertness Level";
BA_ "GenSigTimeoutTime_MulticII" SG_ 2566806430 DrivAlertLev 500;
BA_ "GenSigTimeoutTime_MulticS" SG_ 2566806430 DrivAlertLev 500;
BA_ "GenSigTimeoutTime_MulticS_" SG_ 2566806430 DrivAlertLev 500;
BA_ "GenSigTimeoutTime_MulticS__" SG_ 2566806430 DrivAlertLev 500;
BA_ "GenSigTimeoutTime_PCM" SG_ 2566806430 DrivAlertLev 500;
BA_ "GenSigTimeoutTime_SGW__" SG_ 2566806430 DrivAlertLev 500;
BA_ "SPN" SG_ 2566806430 DrivAlertLev 7474;
BA_ "SigType" SG_ 2566806430 DrivAlertLev 1;
BA_ "CI_ParId" SG_ 2566806430 DrivAlertWarnSysSts "7475";
BA_ "CI_SigId" SG_ 2566806430 DrivAlertWarnSysSts 3123;
BA_ "CI_SigName" SG_ 2566806430 DrivAlertWarnSysSts "Driver Alertness Warning System State";
BA_ "GenSigTimeoutTime_MulticII" SG_ 2566806430 DrivAlertWarnSysSts 500;
BA_ "GenSigTimeoutTime_MulticS" SG_ 2566806430 DrivAlertWarnSysSts 500;
BA_ "GenSigTimeoutTime_MulticS_" SG_ 2566806430 DrivAlertWarnSysSts 500;
BA_ "GenSigTimeoutTime_MulticS__" SG_ 2566806430 DrivAlertWarnSysSts 500;
BA_ "GenSigTimeoutTime_PCM" SG_ 2566806430 DrivAlertWarnSysSts 500;
BA_ "GenSigTimeoutTime_SGW__" SG_ 2566806430 DrivAlertWarnSysSts 500;
BA_ "SPN" SG_ 2566806430 DrivAlertWarnSysSts 7475;
BA_ "CI_ParId" SG_ 2566806430 LdwSysSts "8141";
BA_ "CI_SigId" SG_ 2566806430 LdwSysSts 3126;
BA_ "CI_SigName" SG_ 2566806430 LdwSysSts "Lane Departure Warning System State";
BA_ "GenSigTimeoutTime_MulticII" SG_ 2566806430 LdwSysSts 500;
BA_ "GenSigTimeoutTime_MulticS" SG_ 2566806430 LdwSysSts 500;
BA_ "GenSigTimeoutTime_MulticS_" SG_ 2566806430 LdwSysSts 500;
BA_ "GenSigTimeoutTime_MulticS__" SG_ 2566806430 LdwSysSts 500;
BA_ "GenSigTimeoutTime_PCM" SG_ 2566806430 LdwSysSts 500;
BA_ "GenSigTimeoutTime_SGW__" SG_ 2566806430 LdwSysSts 500;
BA_ "SPN" SG_ 2566806430 LdwSysSts 8141;
BA_ "CI_ParId" SG_ 2566841600 EngTotHrOfOp "247";
BA_ "CI_SigId" SG_ 2566841600 EngTotHrOfOp 1094;
BA_ "CI_SigName" SG_ 2566841600 EngTotHrOfOp "Engine Total Hours of Operation";
BA_ "GenSigTimeoutTime_ADCU" SG_ 2566841600 EngTotHrOfOp 5000;
BA_ "GenSigTimeoutTime_EBS__" SG_ 2566841600 EngTotHrOfOp 5000;
BA_ "GenSigTimeoutTime_EBS___" SG_ 2566841600 EngTotHrOfOp 5000;
BA_ "GenSigTimeoutTime_FMS4" SG_ 2566841600 EngTotHrOfOp 5000;
BA_ "GenSigTimeoutTime_MulticS" SG_ 2566841600 EngTotHrOfOp 5000;
BA_ "GenSigTimeoutTime_MulticS_" SG_ 2566841600 EngTotHrOfOp 5000;
BA_ "GenSigTimeoutTime_MulticS__" SG_ 2566841600 EngTotHrOfOp 5000;
BA_ "GenSigTimeoutTime_PCM" SG_ 2566841600 EngTotHrOfOp 5000;
BA_ "GenSigTimeoutTime_SGW2" SG_ 2566841600 EngTotHrOfOp 5000;
BA_ "GenSigTimeoutTime_SGW__" SG_ 2566841600 EngTotHrOfOp 5000;
BA_ "GenSigTimeoutTime_VCM_" SG_ 2566841600 EngTotHrOfOp 5000;
BA_ "GenSigTimeoutTime_VCM__" SG_ 2566841600 EngTotHrOfOp 5000;
BA_ "SPN" SG_ 2566841600 EngTotHrOfOp 247;
BA_ "SigType" SG_ 2566841600 EngTotHrOfOp 1;
BA_ "CI_ParId" SG_ 2566719744 EngTotFuelUsedHr "5054";
BA_ "CI_SigId" SG_ 2566719744 EngTotFuelUsedHr 1149;
BA_ "CI_SigName" SG_ 2566719744 EngTotFuelUsedHr "Engine Total Fuel Used (High Resolution)";
BA_ "GenSigTimeoutTime_FMS4" SG_ 2566719744 EngTotFuelUsedHr 5000;
BA_ "GenSigTimeoutTime_MulticS" SG_ 2566719744 EngTotFuelUsedHr 5000;
BA_ "GenSigTimeoutTime_MulticS__" SG_ 2566719744 EngTotFuelUsedHr 5000;
BA_ "GenSigTimeoutTime_PCM" SG_ 2566719744 EngTotFuelUsedHr 5000;
BA_ "GenSigTimeoutTime_SGW__" SG_ 2566719744 EngTotFuelUsedHr 5000;
BA_ "GenSigTimeoutTime_VCM_" SG_ 2566719744 EngTotFuelUsedHr 5000;
BA_ "GenSigTimeoutTime_VCM__" SG_ 2566719744 EngTotFuelUsedHr 5000;
BA_ "SPN" SG_ 2566719744 EngTotFuelUsedHr 5054;
BA_ "SigType" SG_ 2566719744 EngTotFuelUsedHr 1;
BA_ "CI_ParId" SG_ 2566837793 HybSysPwrElnCoolLevSw "7550";
BA_ "CI_SigId" SG_ 2566837793 HybSysPwrElnCoolLevSw 2224;
BA_ "CI_SigName" SG_ 2566837793 HybSysPwrElnCoolLevSw "Hybrid System Power Electronics Coolant Level Switch";
BA_ "GenSigTimeoutTime_FMS4" SG_ 2566837793 HybSysPwrElnCoolLevSw 500;
BA_ "GenSigTimeoutTime_PCM" SG_ 2566837793 HybSysPwrElnCoolLevSw 500;
BA_ "GenSigTimeoutTime_SGW__" SG_ 2566837793 HybSysPwrElnCoolLevSw 500;
BA_ "SPN" SG_ 2566837793 HybSysPwrElnCoolLevSw 7550;
BA_ "SigType" SG_ 2566837793 HybSysPwrElnCoolLevSw 4;
BA_ "CI_ParId" SG_ 2566837793 HybSysCoastRegenBrkLevSel "7556";
BA_ "CI_SigId" SG_ 2566837793 HybSysCoastRegenBrkLevSel 2230;
BA_ "CI_SigName" SG_ 2566837793 HybSysCoastRegenBrkLevSel "Hybrid System Coasting Regenerative Braking Level Selector";
BA_ "GenSigTimeoutTime_FMS4" SG_ 2566837793 HybSysCoastRegenBrkLevSel 500;
BA_ "GenSigTimeoutTime_PCM" SG_ 2566837793 HybSysCoastRegenBrkLevSel 500;
BA_ "GenSigTimeoutTime_SGW__" SG_ 2566837793 HybSysCoastRegenBrkLevSel 500;
BA_ "GenSigTimeoutTime_VCU_" SG_ 2566837793 HybSysCoastRegenBrkLevSel 500;
BA_ "GenSigTimeoutTime_VMU" SG_ 2566837793 HybSysCoastRegenBrkLevSel 500;
BA_ "SPN" SG_ 2566837793 HybSysCoastRegenBrkLevSel 7556;
BA_ "SigType" SG_ 2566837793 HybSysCoastRegenBrkLevSel 1;
BA_ "CI_ParId" SG_ 2566701658 PropSysActv "7315";
BA_ "CI_SigId" SG_ 2566701658 PropSysActv 2238;
BA_ "CI_SigName" SG_ 2566701658 PropSysActv "Propulsion System Active";
BA_ "GenSigTimeoutTime_FMS4" SG_ 2566701658 PropSysActv 500;
BA_ "GenSigTimeoutTime_NBM_" SG_ 2566701658 PropSysActv 500;
BA_ "GenSigTimeoutTime_PCM" SG_ 2566701658 PropSysActv 500;
BA_ "GenSigTimeoutTime_SGW__" SG_ 2566701658 PropSysActv 500;
BA_ "SPN" SG_ 2566701658 PropSysActv 7315;
BA_ "SigType" SG_ 2566701658 PropSysActv 4;
BA_ "CI_ParId" SG_ 2566701658 HybSysMotOverspeedInd "7449";
BA_ "CI_SigId" SG_ 2566701658 HybSysMotOverspeedInd 2241;
BA_ "CI_SigName" SG_ 2566701658 HybSysMotOverspeedInd "Hybrid System Motor Overspeed Indicator";
BA_ "GenSigTimeoutTime_FMS4" SG_ 2566701658 HybSysMotOverspeedInd 500;
BA_ "GenSigTimeoutTime_NBM_" SG_ 2566701658 HybSysMotOverspeedInd 500;
BA_ "GenSigTimeoutTime_PCM" SG_ 2566701658 HybSysMotOverspeedInd 500;
BA_ "GenSigTimeoutTime_SGW__" SG_ 2566701658 HybSysMotOverspeedInd 500;
BA_ "SPN" SG_ 2566701658 HybSysMotOverspeedInd 7449;
BA_ "SigType" SG_ 2566701658 HybSysMotOverspeedInd 4;
BA_ "CI_ParId" SG_ 2566701658 HybSysRegenBrkInd "7452";
BA_ "CI_SigId" SG_ 2566701658 HybSysRegenBrkInd 2244;
BA_ "CI_SigName" SG_ 2566701658 HybSysRegenBrkInd "Hybrid System Regenerative Braking Indicator";
BA_ "GenSigTimeoutTime_FMS4" SG_ 2566701658 HybSysRegenBrkInd 500;
BA_ "GenSigTimeoutTime_NBM_" SG_ 2566701658 HybSysRegenBrkInd 500;
BA_ "GenSigTimeoutTime_PCM" SG_ 2566701658 HybSysRegenBrkInd 500;
BA_ "GenSigTimeoutTime_SGW__" SG_ 2566701658 HybSysRegenBrkInd 500;
BA_ "SPN" SG_ 2566701658 HybSysRegenBrkInd 7452;
BA_ "SigType" SG_ 2566701658 HybSysRegenBrkInd 4;
BA_ "CI_ParId" SG_ 2566701658 StoredEnergySrcLev "7895";
BA_ "CI_SigId" SG_ 2566701658 StoredEnergySrcLev 2249;
BA_ "CI_SigName" SG_ 2566701658 StoredEnergySrcLev "Stored Energy Source Level";
BA_ "GenSigTimeoutTime_FMS4" SG_ 2566701658 StoredEnergySrcLev 500;
BA_ "GenSigTimeoutTime_NBM__" SG_ 2566701658 StoredEnergySrcLev 500;
BA_ "GenSigTimeoutTime_PCM" SG_ 2566701658 StoredEnergySrcLev 500;
BA_ "GenSigTimeoutTime_SGW__" SG_ 2566701658 StoredEnergySrcLev 500;
BA_ "SPN" SG_ 2566701658 StoredEnergySrcLev 7895;
BA_ "SigType" SG_ 2566701658 StoredEnergySrcLev 1;
BA_ "CI_ParId" SG_ 2566701658 HybPropModeSts "7896";
BA_ "CI_SigId" SG_ 2566701658 HybPropModeSts 2250;
BA_ "CI_SigName" SG_ 2566701658 HybPropModeSts "Hybrid Propulsion Mode Status";
BA_ "GenSigTimeoutTime_FMS4" SG_ 2566701658 HybPropModeSts 500;
BA_ "GenSigTimeoutTime_NBM_" SG_ 2566701658 HybPropModeSts 500;
BA_ "GenSigTimeoutTime_NBM__" SG_ 2566701658 HybPropModeSts 500;
BA_ "GenSigTimeoutTime_PCM" SG_ 2566701658 HybPropModeSts 500;
BA_ "GenSigTimeoutTime_SGW__" SG_ 2566701658 HybPropModeSts 500;
BA_ "SPN" SG_ 2566701658 HybPropModeSts 7896;
BA_ "CI_ParId" SG_ 2566701658 ExtEnergySrcConnSts "7898";
BA_ "CI_SigId" SG_ 2566701658 ExtEnergySrcConnSts 2252;
BA_ "CI_SigName" SG_ 2566701658 ExtEnergySrcConnSts "External Energy Source Connection Status";
BA_ "GenSigTimeoutTime_FMS4" SG_ 2566701658 ExtEnergySrcConnSts 500;
BA_ "GenSigTimeoutTime_NBM_" SG_ 2566701658 ExtEnergySrcConnSts 500;
BA_ "GenSigTimeoutTime_NBM__" SG_ 2566701658 ExtEnergySrcConnSts 500;
BA_ "GenSigTimeoutTime_PCM" SG_ 2566701658 ExtEnergySrcConnSts 500;
BA_ "GenSigTimeoutTime_SGW__" SG_ 2566701658 ExtEnergySrcConnSts 500;
BA_ "SPN" SG_ 2566701658 ExtEnergySrcConnSts 7898;
BA_ "CI_ParId" SG_ 2566698842 HybBatRemChg "5464";
BA_ "CI_SigId" SG_ 2566698842 HybBatRemChg 2276;
BA_ "CI_SigName" SG_ 2566698842 HybBatRemChg "Hybrid Battery Pack Remaining Charge";
BA_ "GenSigTimeoutTime_FMS4" SG_ 2566698842 HybBatRemChg 5000;
BA_ "GenSigTimeoutTime_MulticS_" SG_ 2566698842 HybBatRemChg 5000;
BA_ "GenSigTimeoutTime_PCM" SG_ 2566698842 HybBatRemChg 5000;
BA_ "GenSigTimeoutTime_SGW__" SG_ 2566698842 HybBatRemChg 5000;
BA_ "SPN" SG_ 2566698842 HybBatRemChg 5464;
BA_ "SigType" SG_ 2566698842 HybBatRemChg 1;
BA_ "CI_ParId" SG_ 2566698842 HybSysEassRemPc "8558";
BA_ "CI_SigId" SG_ 2566698842 HybSysEassRemPc 2277;
BA_ "CI_SigName" SG_ 2566698842 HybSysEassRemPc "Hybrid System Engine Stop-Start Remaining Percentage";
BA_ "GenSigTimeoutTime_NBM__" SG_ 2566698842 HybSysEassRemPc 5000;
BA_ "GenSigTimeoutTime_PCM" SG_ 2566698842 HybSysEassRemPc 5000;
BA_ "GenSigTimeoutTime_SGW__" SG_ 2566698842 HybSysEassRemPc 5000;
BA_ "SPN" SG_ 2566698842 HybSysEassRemPc 8558;
BA_ "SigType" SG_ 2566698842 HybSysEassRemPc 1;
BA_ "CI_ParId" SG_ 2566850819 EngStopReq "IB008";
BA_ "CI_SigId" SG_ 2566850819 EngStopReq 2279;
BA_ "CI_SigName" SG_ 2566850819 EngStopReq "Engine Stop Request";
BA_ "GenSigTimeoutTime_MD1_D" SG_ 2566850819 EngStopReq 500;
BA_ "GenSigTimeoutTime_MD1_G" SG_ 2566850819 EngStopReq 500;
BA_ "GenSigTimeoutTime_NBM" SG_ 2566850819 EngStopReq 500;
BA_ "GenSigTimeoutTime_NBM___" SG_ 2566850819 EngStopReq 500;
BA_ "GenSigTimeoutTime_SGW__" SG_ 2566850819 EngStopReq 500;
BA_ "GenSigTimeoutTime_VCM" SG_ 2566850819 EngStopReq 500;
BA_ "CI_ParId" SG_ 2566850819 CoolSts_18FF0903 "IB278";
BA_ "CI_SigId" SG_ 2566850819 CoolSts_18FF0903 2280;
BA_ "CI_SigName" SG_ 2566850819 CoolSts_18FF0903 "Cooling_State";
BA_ "GenSigTimeoutTime_MD1_D" SG_ 2566850819 CoolSts_18FF0903 500;
BA_ "GenSigTimeoutTime_MD1_G" SG_ 2566850819 CoolSts_18FF0903 500;
BA_ "GenSigTimeoutTime_SGW__" SG_ 2566850819 CoolSts_18FF0903 500;
BA_ "GenSigTimeoutTime_VCM" SG_ 2566850819 CoolSts_18FF0903 500;
BA_ "SigType" SG_ 2566850819 CoolSts_18FF0903 4;
BA_ "CI_ParId" SG_ 2566850819 CruWarnLamp "IB867";
BA_ "CI_SigId" SG_ 2566850819 CruWarnLamp 2281;
BA_ "CI_SigName" SG_ 2566850819 CruWarnLamp "CRU Warning Lamp";
BA_ "GenSigTimeoutTime_MD1_D" SG_ 2566850819 CruWarnLamp 500;
BA_ "GenSigTimeoutTime_MD1_G" SG_ 2566850819 CruWarnLamp 500;
BA_ "GenSigTimeoutTime_SGW__" SG_ 2566850819 CruWarnLamp 500;
BA_ "GenSigTimeoutTime_VCM" SG_ 2566850819 CruWarnLamp 500;
BA_ "SigType" SG_ 2566850819 CruWarnLamp 4;
BA_ "CI_ParId" SG_ 2566850819 CruStopLamp "IB868";
BA_ "CI_SigId" SG_ 2566850819 CruStopLamp 2282;
BA_ "CI_SigName" SG_ 2566850819 CruStopLamp "CRU Stop Lamp";
BA_ "GenSigTimeoutTime_MD1_D" SG_ 2566850819 CruStopLamp 500;
BA_ "GenSigTimeoutTime_MD1_G" SG_ 2566850819 CruStopLamp 500;
BA_ "GenSigTimeoutTime_SGW__" SG_ 2566850819 CruStopLamp 500;
BA_ "GenSigTimeoutTime_VCM" SG_ 2566850819 CruStopLamp 500;
BA_ "SigType" SG_ 2566850819 CruStopLamp 4;
BA_ "CI_ParId" SG_ 2566850819 CruSts "IB272";
BA_ "CI_SigId" SG_ 2566850819 CruSts 2283;
BA_ "CI_SigName" SG_ 2566850819 CruSts "CRU State";
BA_ "GenSigTimeoutTime_MD1_D" SG_ 2566850819 CruSts 500;
BA_ "GenSigTimeoutTime_MD1_G" SG_ 2566850819 CruSts 500;
BA_ "GenSigTimeoutTime_NBM" SG_ 2566850819 CruSts 500;
BA_ "GenSigTimeoutTime_NBM___" SG_ 2566850819 CruSts 500;
BA_ "GenSigTimeoutTime_SGW__" SG_ 2566850819 CruSts 500;
BA_ "GenSigTimeoutTime_VCM" SG_ 2566850819 CruSts 500;
BA_ "CI_ParId" SG_ 2566850819 CoolLev "IB273";
BA_ "CI_SigId" SG_ 2566850819 CoolLev 2284;
BA_ "CI_SigName" SG_ 2566850819 CoolLev "Coolant level";
BA_ "GenSigTimeoutTime_MD1_D" SG_ 2566850819 CoolLev 500;
BA_ "GenSigTimeoutTime_MD1_G" SG_ 2566850819 CoolLev 500;
BA_ "GenSigTimeoutTime_NBM" SG_ 2566850819 CoolLev 500;
BA_ "GenSigTimeoutTime_NBM___" SG_ 2566850819 CoolLev 500;
BA_ "GenSigTimeoutTime_SGW__" SG_ 2566850819 CoolLev 500;
BA_ "GenSigTimeoutTime_VCM" SG_ 2566850819 CoolLev 500;
BA_ "CI_ParId" SG_ 2566850819 StopstartSts "IB869";
BA_ "CI_SigId" SG_ 2566850819 StopstartSts 2285;
BA_ "CI_SigName" SG_ 2566850819 StopstartSts "StopStart_State";
BA_ "GenSigTimeoutTime_MD1_D" SG_ 2566850819 StopstartSts 500;
BA_ "GenSigTimeoutTime_MD1_G" SG_ 2566850819 StopstartSts 500;
BA_ "GenSigTimeoutTime_NBM" SG_ 2566850819 StopstartSts 500;
BA_ "GenSigTimeoutTime_NBM___" SG_ 2566850819 StopstartSts 500;
BA_ "GenSigTimeoutTime_SGW__" SG_ 2566850819 StopstartSts 500;
BA_ "GenSigTimeoutTime_VCM" SG_ 2566850819 StopstartSts 500;
BA_ "CI_ParId" SG_ 2566850819 ReasEngStartFail "IB870";
BA_ "CI_SigId" SG_ 2566850819 ReasEngStartFail 2286;
BA_ "CI_SigName" SG_ 2566850819 ReasEngStartFail "Reason Engine Start Failure";
BA_ "GenSigTimeoutTime_MD1_D" SG_ 2566850819 ReasEngStartFail 500;
BA_ "GenSigTimeoutTime_MD1_G" SG_ 2566850819 ReasEngStartFail 500;
BA_ "GenSigTimeoutTime_SGW__" SG_ 2566850819 ReasEngStartFail 500;
BA_ "GenSigTimeoutTime_VCM" SG_ 2566850819 ReasEngStartFail 500;
BA_ "CI_ParId" SG_ 2566850819 EmotSts "IB871";
BA_ "CI_SigId" SG_ 2566850819 EmotSts 2287;
BA_ "CI_SigName" SG_ 2566850819 EmotSts "Emot State";
BA_ "GenSigTimeoutTime_MD1_D" SG_ 2566850819 EmotSts 500;
BA_ "GenSigTimeoutTime_MD1_G" SG_ 2566850819 EmotSts 500;
BA_ "GenSigTimeoutTime_SGW__" SG_ 2566850819 EmotSts 500;
BA_ "GenSigTimeoutTime_VCM" SG_ 2566850819 EmotSts 500;
BA_ "SigType" SG_ 2566850819 EmotSts 4;
BA_ "CI_ParId" SG_ 2566850819 EssSts "IB872";
BA_ "CI_SigId" SG_ 2566850819 EssSts 2288;
BA_ "CI_SigName" SG_ 2566850819 EssSts "ESS State";
BA_ "GenSigTimeoutTime_MD1_D" SG_ 2566850819 EssSts 500;
BA_ "GenSigTimeoutTime_MD1_G" SG_ 2566850819 EssSts 500;
BA_ "GenSigTimeoutTime_SGW__" SG_ 2566850819 EssSts 500;
BA_ "GenSigTimeoutTime_VCM" SG_ 2566850819 EssSts 500;
BA_ "SigType" SG_ 2566850819 EssSts 4;
BA_ "CI_ParId" SG_ 2566850819 DcdcSts "IB274";
BA_ "CI_SigId" SG_ 2566850819 DcdcSts 2289;
BA_ "CI_SigName" SG_ 2566850819 DcdcSts "DCDC State";
BA_ "GenSigTimeoutTime_MD1_D" SG_ 2566850819 DcdcSts 500;
BA_ "GenSigTimeoutTime_MD1_G" SG_ 2566850819 DcdcSts 500;
BA_ "GenSigTimeoutTime_NBM" SG_ 2566850819 DcdcSts 500;
BA_ "GenSigTimeoutTime_NBM___" SG_ 2566850819 DcdcSts 500;
BA_ "GenSigTimeoutTime_SGW__" SG_ 2566850819 DcdcSts 500;
BA_ "GenSigTimeoutTime_VCM" SG_ 2566850819 DcdcSts 500;
BA_ "SigType" SG_ 2566850819 DcdcSts 4;
BA_ "CI_ParId" SG_ 2566850819 _24VDcdcV "IB275";
BA_ "CI_SigId" SG_ 2566850819 _24VDcdcV 2290;
BA_ "CI_SigName" SG_ 2566850819 _24VDcdcV "24V DCDC Voltage";
BA_ "GenSigTimeoutTime_MD1_D" SG_ 2566850819 _24VDcdcV 500;
BA_ "GenSigTimeoutTime_MD1_G" SG_ 2566850819 _24VDcdcV 500;
BA_ "GenSigTimeoutTime_MulticS" SG_ 2566850819 _24VDcdcV 500;
BA_ "GenSigTimeoutTime_NBM" SG_ 2566850819 _24VDcdcV 500;
BA_ "GenSigTimeoutTime_NBM___" SG_ 2566850819 _24VDcdcV 500;
BA_ "GenSigTimeoutTime_SGW__" SG_ 2566850819 _24VDcdcV 500;
BA_ "GenSigTimeoutTime_VCM" SG_ 2566850819 _24VDcdcV 500;
BA_ "CI_ParId" SG_ 2566850819 Soc "IB276";
BA_ "CI_SigId" SG_ 2566850819 Soc 2291;
BA_ "CI_SigName" SG_ 2566850819 Soc "State of charge";
BA_ "GenSigTimeoutTime_MD1_D" SG_ 2566850819 Soc 500;
BA_ "GenSigTimeoutTime_MD1_G" SG_ 2566850819 Soc 500;
BA_ "GenSigTimeoutTime_MulticS" SG_ 2566850819 Soc 500;
BA_ "GenSigTimeoutTime_NBM" SG_ 2566850819 Soc 500;
BA_ "GenSigTimeoutTime_NBM___" SG_ 2566850819 Soc 500;
BA_ "GenSigTimeoutTime_SGW__" SG_ 2566850819 Soc 500;
BA_ "GenSigTimeoutTime_VCM" SG_ 2566850819 Soc 500;
BA_ "CI_ParId" SG_ 2566850819 StsOfHealt "IB277";
BA_ "CI_SigId" SG_ 2566850819 StsOfHealt 2292;
BA_ "CI_SigName" SG_ 2566850819 StsOfHealt "State of healt";
BA_ "GenSigTimeoutTime_MD1_D" SG_ 2566850819 StsOfHealt 500;
BA_ "GenSigTimeoutTime_MD1_G" SG_ 2566850819 StsOfHealt 500;
BA_ "GenSigTimeoutTime_SGW__" SG_ 2566850819 StsOfHealt 500;
BA_ "GenSigTimeoutTime_VCM" SG_ 2566850819 StsOfHealt 500;
BA_ "SigType" SG_ 2566850819 StsOfHealt 1;
BA_ "CI_ParId" SG_ 2566851075 _48VBatCur "IB879";
BA_ "CI_SigId" SG_ 2566851075 _48VBatCur 2307;
BA_ "CI_SigName" SG_ 2566851075 _48VBatCur "48V_Battery_Current";
BA_ "GenSigTimeoutTime_PCM" SG_ 2566851075 _48VBatCur 1500;
BA_ "GenSigTimeoutTime_SGW__" SG_ 2566851075 _48VBatCur 1500;
BA_ "CI_ParId" SG_ 2566851075 _48VDcdcCur "IB880";
BA_ "CI_SigId" SG_ 2566851075 _48VDcdcCur 2308;
BA_ "CI_SigName" SG_ 2566851075 _48VDcdcCur "48V_DCDC_Current";
BA_ "GenSigTimeoutTime_PCM" SG_ 2566851075 _48VDcdcCur 1500;
BA_ "GenSigTimeoutTime_SGW__" SG_ 2566851075 _48VDcdcCur 1500;
BA_ "CI_ParId" SG_ 2566851075 _48VPwrconverterDcCur "IB881";
BA_ "CI_SigId" SG_ 2566851075 _48VPwrconverterDcCur 2309;
BA_ "CI_SigName" SG_ 2566851075 _48VPwrconverterDcCur "48V_PowerConverter_DC_Current";
BA_ "GenSigTimeoutTime_PCM" SG_ 2566851075 _48VPwrconverterDcCur 1500;
BA_ "GenSigTimeoutTime_SGW__" SG_ 2566851075 _48VPwrconverterDcCur 1500;
BA_ "CI_ParId" SG_ 2566851075 _48VPwrconverterDcV "IB882";
BA_ "CI_SigId" SG_ 2566851075 _48VPwrconverterDcV 2310;
BA_ "CI_SigName" SG_ 2566851075 _48VPwrconverterDcV "48V_PowerConverter_DC_Voltage";
BA_ "GenSigTimeoutTime_PCM" SG_ 2566851075 _48VPwrconverterDcV 1500;
BA_ "GenSigTimeoutTime_SGW__" SG_ 2566851075 _48VPwrconverterDcV 1500;
BA_ "CI_ParId" SG_ 2566851075 _24VFeedinpointV "IB1070";
BA_ "CI_SigId" SG_ 2566851075 _24VFeedinpointV 2311;
BA_ "CI_SigName" SG_ 2566851075 _24VFeedinpointV "24V FeedInPoint Voltage";
BA_ "GenSigTimeoutTime_PCM" SG_ 2566851075 _24VFeedinpointV 1500;
BA_ "GenSigTimeoutTime_SGW__" SG_ 2566851075 _24VFeedinpointV 1500;
BA_ "CI_ParId" SG_ 2566851331 _24VDcdcCur "IB873";
BA_ "CI_SigId" SG_ 2566851331 _24VDcdcCur 2313;
BA_ "CI_SigName" SG_ 2566851331 _24VDcdcCur "24V_DCDC_Current";
BA_ "GenSigTimeoutTime_MD1_D" SG_ 2566851331 _24VDcdcCur 1500;
BA_ "GenSigTimeoutTime_MD1_G" SG_ 2566851331 _24VDcdcCur 1500;
BA_ "GenSigTimeoutTime_PCM" SG_ 2566851331 _24VDcdcCur 1500;
BA_ "GenSigTimeoutTime_SGW__" SG_ 2566851331 _24VDcdcCur 1500;
BA_ "GenSigTimeoutTime_VCM" SG_ 2566851331 _24VDcdcCur 1500;
BA_ "CI_ParId" SG_ 2566851331 _24VDcdcPwr "IB874";
BA_ "CI_SigId" SG_ 2566851331 _24VDcdcPwr 2314;
BA_ "CI_SigName" SG_ 2566851331 _24VDcdcPwr "24V_DCDC_Power";
BA_ "GenSigTimeoutTime_MD1_D" SG_ 2566851331 _24VDcdcPwr 1500;
BA_ "GenSigTimeoutTime_MD1_G" SG_ 2566851331 _24VDcdcPwr 1500;
BA_ "GenSigTimeoutTime_PCM" SG_ 2566851331 _24VDcdcPwr 1500;
BA_ "GenSigTimeoutTime_SGW__" SG_ 2566851331 _24VDcdcPwr 1500;
BA_ "GenSigTimeoutTime_VCM" SG_ 2566851331 _24VDcdcPwr 1500;
BA_ "CI_ParId" SG_ 2566851331 EMottorque "IB875";
BA_ "CI_SigId" SG_ 2566851331 EMottorque 2315;
BA_ "CI_SigName" SG_ 2566851331 EMottorque "E_MotorTorque";
BA_ "GenSigTimeoutTime_MD1_D" SG_ 2566851331 EMottorque 1500;
BA_ "GenSigTimeoutTime_MD1_G" SG_ 2566851331 EMottorque 1500;
BA_ "GenSigTimeoutTime_PCM" SG_ 2566851331 EMottorque 1500;
BA_ "GenSigTimeoutTime_SGW__" SG_ 2566851331 EMottorque 1500;
BA_ "GenSigTimeoutTime_VCM" SG_ 2566851331 EMottorque 1500;
BA_ "CI_ParId" SG_ 2566851331 EMotspeed "IB876";
BA_ "CI_SigId" SG_ 2566851331 EMotspeed 2316;
BA_ "CI_SigName" SG_ 2566851331 EMotspeed "E_MotorSpeed";
BA_ "GenSigTimeoutTime_MD1_D" SG_ 2566851331 EMotspeed 1500;
BA_ "GenSigTimeoutTime_MD1_G" SG_ 2566851331 EMotspeed 1500;
BA_ "GenSigTimeoutTime_PCM" SG_ 2566851331 EMotspeed 1500;
BA_ "GenSigTimeoutTime_SGW__" SG_ 2566851331 EMotspeed 1500;
BA_ "GenSigTimeoutTime_VCM" SG_ 2566851331 EMotspeed 1500;
BA_ "CI_ParId" SG_ 2566851331 EMotpower "IB877";
BA_ "CI_SigId" SG_ 2566851331 EMotpower 2317;
BA_ "CI_SigName" SG_ 2566851331 EMotpower "E_MotorPower";
BA_ "GenSigTimeoutTime_MD1_D" SG_ 2566851331 EMotpower 1500;
BA_ "GenSigTimeoutTime_MD1_G" SG_ 2566851331 EMotpower 1500;
BA_ "GenSigTimeoutTime_PCM" SG_ 2566851331 EMotpower 1500;
BA_ "GenSigTimeoutTime_SGW__" SG_ 2566851331 EMotpower 1500;
BA_ "GenSigTimeoutTime_VCM" SG_ 2566851331 EMotpower 1500;
BA_ "CI_ParId" SG_ 2566851331 Isbalancingactive "IB878";
BA_ "CI_SigId" SG_ 2566851331 Isbalancingactive 2318;
BA_ "CI_SigName" SG_ 2566851331 Isbalancingactive "isBalancingActive";
BA_ "GenSigTimeoutTime_MD1_D" SG_ 2566851331 Isbalancingactive 1500;
BA_ "GenSigTimeoutTime_MD1_G" SG_ 2566851331 Isbalancingactive 1500;
BA_ "GenSigTimeoutTime_PCM" SG_ 2566851331 Isbalancingactive 1500;
BA_ "GenSigTimeoutTime_SGW__" SG_ 2566851331 Isbalancingactive 1500;
BA_ "GenSigTimeoutTime_VCM" SG_ 2566851331 Isbalancingactive 1500;
BA_ "SigType" SG_ 2566851331 Isbalancingactive 4;
BA_ "CI_ParId" SG_ 2566851843 EMotrecoverypower "IB883";
BA_ "CI_SigId" SG_ 2566851843 EMotrecoverypower 2320;
BA_ "CI_SigName" SG_ 2566851843 EMotrecoverypower "E_MotorRecoveryPower";
BA_ "GenSigTimeoutTime_PCM" SG_ 2566851843 EMotrecoverypower 1500;
BA_ "GenSigTimeoutTime_SGW__" SG_ 2566851843 EMotrecoverypower 1500;
BA_ "CI_ParId" SG_ 2566851843 EMottractionpower "IB884";
BA_ "CI_SigId" SG_ 2566851843 EMottractionpower 2321;
BA_ "CI_SigName" SG_ 2566851843 EMottractionpower "E_MotorTractionPower";
BA_ "GenSigTimeoutTime_PCM" SG_ 2566851843 EMottractionpower 1500;
BA_ "GenSigTimeoutTime_SGW__" SG_ 2566851843 EMottractionpower 1500;
BA_ "CI_ParId" SG_ 2566851843 EMottemperature "IB885";
BA_ "CI_SigId" SG_ 2566851843 EMottemperature 2322;
BA_ "CI_SigName" SG_ 2566851843 EMottemperature "E_MotorTemperature";
BA_ "GenSigTimeoutTime_PCM" SG_ 2566851843 EMottemperature 1500;
BA_ "GenSigTimeoutTime_SGW__" SG_ 2566851843 EMottemperature 1500;
BA_ "SigType" SG_ 2566851843 EMottemperature 1;
BA_ "CI_ParId" SG_ 2566851843 Cellmaxvoltage "IB886";
BA_ "CI_SigId" SG_ 2566851843 Cellmaxvoltage 2323;
BA_ "CI_SigName" SG_ 2566851843 Cellmaxvoltage "CellMaxVoltage";
BA_ "GenSigTimeoutTime_PCM" SG_ 2566851843 Cellmaxvoltage 1500;
BA_ "GenSigTimeoutTime_SGW__" SG_ 2566851843 Cellmaxvoltage 1500;
BA_ "CI_ParId" SG_ 2566851843 Cellminvoltage "IB887";
BA_ "CI_SigId" SG_ 2566851843 Cellminvoltage 2324;
BA_ "CI_SigName" SG_ 2566851843 Cellminvoltage "CellMinVoltage";
BA_ "GenSigTimeoutTime_PCM" SG_ 2566851843 Cellminvoltage 1500;
BA_ "GenSigTimeoutTime_SGW__" SG_ 2566851843 Cellminvoltage 1500;
BA_ "CI_ParId" SG_ 2566851843 Celltemperaturemax "IB888";
BA_ "CI_SigId" SG_ 2566851843 Celltemperaturemax 2325;
BA_ "CI_SigName" SG_ 2566851843 Celltemperaturemax "CellTemperatureMax";
BA_ "GenSigTimeoutTime_PCM" SG_ 2566851843 Celltemperaturemax 1500;
BA_ "GenSigTimeoutTime_SGW__" SG_ 2566851843 Celltemperaturemax 1500;
BA_ "SigType" SG_ 2566851843 Celltemperaturemax 1;
BA_ "CI_ParId" SG_ 2566891136 NormUseCntCat1 "IB107";
BA_ "CI_SigId" SG_ 2566891136 NormUseCntCat1 1375;
BA_ "CI_SigName" SG_ 2566891136 NormUseCntCat1 "Normal use counter CAT1";
BA_ "GenSigTimeoutTime_PCM" SG_ 2566891136 NormUseCntCat1 5000;
BA_ "SigType" SG_ 2566891136 NormUseCntCat1 1;
BA_ "CI_ParId" SG_ 2566891136 AbnormalUseCntCat2 "IB108";
BA_ "CI_SigId" SG_ 2566891136 AbnormalUseCntCat2 1376;
BA_ "CI_SigName" SG_ 2566891136 AbnormalUseCntCat2 "Abnormal use counter CAT2";
BA_ "GenSigTimeoutTime_PCM" SG_ 2566891136 AbnormalUseCntCat2 5000;
BA_ "SigType" SG_ 2566891136 AbnormalUseCntCat2 1;
BA_ "CI_ParId" SG_ 2566891136 AbnormalUseCntCat3 "IB109";
BA_ "CI_SigId" SG_ 2566891136 AbnormalUseCntCat3 1377;
BA_ "CI_SigName" SG_ 2566891136 AbnormalUseCntCat3 "Abnormal use counter CAT3";
BA_ "GenSigTimeoutTime_PCM" SG_ 2566891136 AbnormalUseCntCat3 5000;
BA_ "SigType" SG_ 2566891136 AbnormalUseCntCat3 1;
BA_ "CI_ParId" SG_ 2566891136 AbnormalUseCntCat4 "IB110";
BA_ "CI_SigId" SG_ 2566891136 AbnormalUseCntCat4 1378;
BA_ "CI_SigName" SG_ 2566891136 AbnormalUseCntCat4 "Abnormal use counter CAT4";
BA_ "GenSigTimeoutTime_PCM" SG_ 2566891136 AbnormalUseCntCat4 5000;
BA_ "SigType" SG_ 2566891136 AbnormalUseCntCat4 1;
BA_ "CI_ParId" SG_ 2566891136 AbnormalUseCntCat5 "IB111";
BA_ "CI_SigId" SG_ 2566891136 AbnormalUseCntCat5 1379;
BA_ "CI_SigName" SG_ 2566891136 AbnormalUseCntCat5 "Abnormal use counter CAT5";
BA_ "GenSigTimeoutTime_PCM" SG_ 2566891136 AbnormalUseCntCat5 5000;
BA_ "SigType" SG_ 2566891136 AbnormalUseCntCat5 1;
BA_ "CI_ParId" SG_ 2566891136 EmerUseCntCat6 "IB112";
BA_ "CI_SigId" SG_ 2566891136 EmerUseCntCat6 1380;
BA_ "CI_SigName" SG_ 2566891136 EmerUseCntCat6 "Emergency use counter CAT6";
BA_ "GenSigTimeoutTime_PCM" SG_ 2566891136 EmerUseCntCat6 5000;
BA_ "SigType" SG_ 2566891136 EmerUseCntCat6 1;
BA_ "CI_ParId" SG_ 2566890880 NormUseCntCat1_18FFA580 "IB107";
BA_ "CI_SigId" SG_ 2566890880 NormUseCntCat1_18FFA580 1382;
BA_ "CI_SigName" SG_ 2566890880 NormUseCntCat1_18FFA580 "Normal use counter CAT1";
BA_ "GenSigTimeoutTime_PCM" SG_ 2566890880 NormUseCntCat1_18FFA580 5000;
BA_ "SigType" SG_ 2566890880 NormUseCntCat1_18FFA580 1;
BA_ "CI_ParId" SG_ 2566890880 AbnormalUseCntCat2_18FFA580 "IB108";
BA_ "CI_SigId" SG_ 2566890880 AbnormalUseCntCat2_18FFA580 1383;
BA_ "CI_SigName" SG_ 2566890880 AbnormalUseCntCat2_18FFA580 "Abnormal use counter CAT2";
BA_ "GenSigTimeoutTime_PCM" SG_ 2566890880 AbnormalUseCntCat2_18FFA580 5000;
BA_ "SigType" SG_ 2566890880 AbnormalUseCntCat2_18FFA580 1;
BA_ "CI_ParId" SG_ 2566890880 AbnormalUseCntCat3_18FFA580 "IB109";
BA_ "CI_SigId" SG_ 2566890880 AbnormalUseCntCat3_18FFA580 1384;
BA_ "CI_SigName" SG_ 2566890880 AbnormalUseCntCat3_18FFA580 "Abnormal use counter CAT3";
BA_ "GenSigTimeoutTime_PCM" SG_ 2566890880 AbnormalUseCntCat3_18FFA580 5000;
BA_ "SigType" SG_ 2566890880 AbnormalUseCntCat3_18FFA580 1;
BA_ "CI_ParId" SG_ 2566890880 AbnormalUseCntCat4_18FFA580 "IB110";
BA_ "CI_SigId" SG_ 2566890880 AbnormalUseCntCat4_18FFA580 1385;
BA_ "CI_SigName" SG_ 2566890880 AbnormalUseCntCat4_18FFA580 "Abnormal use counter CAT4";
BA_ "GenSigTimeoutTime_PCM" SG_ 2566890880 AbnormalUseCntCat4_18FFA580 5000;
BA_ "SigType" SG_ 2566890880 AbnormalUseCntCat4_18FFA580 1;
BA_ "CI_ParId" SG_ 2566890880 AbnormalUseCntCat5_18FFA580 "IB111";
BA_ "CI_SigId" SG_ 2566890880 AbnormalUseCntCat5_18FFA580 1386;
BA_ "CI_SigName" SG_ 2566890880 AbnormalUseCntCat5_18FFA580 "Abnormal use counter CAT5";
BA_ "GenSigTimeoutTime_PCM" SG_ 2566890880 AbnormalUseCntCat5_18FFA580 5000;
BA_ "SigType" SG_ 2566890880 AbnormalUseCntCat5_18FFA580 1;
BA_ "CI_ParId" SG_ 2566890880 EmerUseCntCat6_18FFA580 "IB112";
BA_ "CI_SigId" SG_ 2566890880 EmerUseCntCat6_18FFA580 1387;
BA_ "CI_SigName" SG_ 2566890880 EmerUseCntCat6_18FFA580 "Emergency use counter CAT6";
BA_ "GenSigTimeoutTime_PCM" SG_ 2566890880 EmerUseCntCat6_18FFA580 5000;
BA_ "SigType" SG_ 2566890880 EmerUseCntCat6_18FFA580 1;
BA_ "CI_ParId" SG_ 2566890368 OvernightContactStsofhealth "IB113";
BA_ "CI_SigId" SG_ 2566890368 OvernightContactStsofhealth 1389;
BA_ "CI_SigName" SG_ 2566890368 OvernightContactStsofhealth "Overnight Contactor StateOfHealth";
BA_ "GenSigTimeoutTime_PCM" SG_ 2566890368 OvernightContactStsofhealth 25000;
BA_ "SigType" SG_ 2566890368 OvernightContactStsofhealth 1;
BA_ "CI_ParId" SG_ 2566890368 OpportunitySwstateofhealth "IB114";
BA_ "CI_SigId" SG_ 2566890368 OpportunitySwstateofhealth 1390;
BA_ "CI_SigName" SG_ 2566890368 OpportunitySwstateofhealth "Opportunity SwitchStateOfHealth";
BA_ "GenSigTimeoutTime_PCM" SG_ 2566890368 OpportunitySwstateofhealth 25000;
BA_ "SigType" SG_ 2566890368 OpportunitySwstateofhealth 1;
BA_ "CI_ParId" SG_ 2566890368 TempCurSens "IB115";
BA_ "CI_SigId" SG_ 2566890368 TempCurSens 1391;
BA_ "CI_SigName" SG_ 2566890368 TempCurSens "Temperature Current Sensor";
BA_ "GenSigTimeoutTime_PCM" SG_ 2566890368 TempCurSens 25000;
BA_ "SigType" SG_ 2566890368 TempCurSens 1;
BA_ "CI_ParId" SG_ 2566890368 PrototypePt1000Temp "IB116";
BA_ "CI_SigId" SG_ 2566890368 PrototypePt1000Temp 1392;
BA_ "CI_SigName" SG_ 2566890368 PrototypePt1000Temp "Prototype PT1000 Temperature";
BA_ "GenSigTimeoutTime_PCM" SG_ 2566890368 PrototypePt1000Temp 25000;
BA_ "GenSigTimeoutTime_VCU" SG_ 2566890368 PrototypePt1000Temp 25000;
BA_ "SigType" SG_ 2566890368 PrototypePt1000Temp 1;
BA_ "CI_ParId" SG_ 2566890368 DicoTemp "IB117";
BA_ "CI_SigId" SG_ 2566890368 DicoTemp 1393;
BA_ "CI_SigName" SG_ 2566890368 DicoTemp "DICO Temperature";
BA_ "GenSigTimeoutTime_PCM" SG_ 2566890368 DicoTemp 25000;
BA_ "SigType" SG_ 2566890368 DicoTemp 1;
BA_ "CI_ParId" SG_ 2566890368 Errcode "IB118";
BA_ "CI_SigId" SG_ 2566890368 Errcode 1394;
BA_ "CI_SigName" SG_ 2566890368 Errcode "ErrorCode";
BA_ "GenSigTimeoutTime_PCM" SG_ 2566890368 Errcode 25000;
BA_ "GenSigTimeoutTime_VCU" SG_ 2566890368 Errcode 25000;
BA_ "CI_ParId" SG_ 2566890368 CurSensSysSts "IB119";
BA_ "CI_SigId" SG_ 2566890368 CurSensSysSts 1395;
BA_ "CI_SigName" SG_ 2566890368 CurSensSysSts "Current Sensor System State";
BA_ "GenSigTimeoutTime_PCM" SG_ 2566890368 CurSensSysSts 25000;
BA_ "CI_ParId" SG_ 2566845952 EngInMan1Prs "102";
BA_ "CI_SigId" SG_ 2566845952 EngInMan1Prs 1099;
BA_ "CI_SigName" SG_ 2566845952 EngInMan1Prs "Engine Intake Manifold #1 Pressure";
BA_ "GenSigTimeoutTime_ADCU" SG_ 2566845952 EngInMan1Prs 500;
BA_ "GenSigTimeoutTime_FMS4" SG_ 2566845952 EngInMan1Prs 500;
BA_ "GenSigTimeoutTime_MulticS" SG_ 2566845952 EngInMan1Prs 500;
BA_ "GenSigTimeoutTime_NBM" SG_ 2566845952 EngInMan1Prs 500;
BA_ "GenSigTimeoutTime_NBM___" SG_ 2566845952 EngInMan1Prs 500;
BA_ "GenSigTimeoutTime_PCM" SG_ 2566845952 EngInMan1Prs 500;
BA_ "GenSigTimeoutTime_SGW__" SG_ 2566845952 EngInMan1Prs 500;
BA_ "GenSigTimeoutTime_VCM_" SG_ 2566845952 EngInMan1Prs 500;
BA_ "GenSigTimeoutTime_VCM__" SG_ 2566845952 EngInMan1Prs 500;
BA_ "SPN" SG_ 2566845952 EngInMan1Prs 102;
BA_ "SigType" SG_ 2566845952 EngInMan1Prs 1;
BA_ "CI_ParId" SG_ 2566845952 EngInMan1Temp "105";
BA_ "CI_SigId" SG_ 2566845952 EngInMan1Temp 1100;
BA_ "CI_SigName" SG_ 2566845952 EngInMan1Temp "Engine Intake Manifold 1 Temperature";
BA_ "GenSigTimeoutTime_FMS4" SG_ 2566845952 EngInMan1Temp 500;
BA_ "GenSigTimeoutTime_NBM" SG_ 2566845952 EngInMan1Temp 500;
BA_ "GenSigTimeoutTime_NBM___" SG_ 2566845952 EngInMan1Temp 500;
BA_ "GenSigTimeoutTime_PCM" SG_ 2566845952 EngInMan1Temp 500;
BA_ "GenSigTimeoutTime_SGW__" SG_ 2566845952 EngInMan1Temp 500;
BA_ "GenSigTimeoutTime_VCM_" SG_ 2566845952 EngInMan1Temp 500;
BA_ "GenSigTimeoutTime_VCM__" SG_ 2566845952 EngInMan1Temp 500;
BA_ "SPN" SG_ 2566845952 EngInMan1Temp 105;
BA_ "SigType" SG_ 2566845952 EngInMan1Temp 1;
BA_ "CI_ParId" SG_ 2566845952 EngExhTemp "173";
BA_ "CI_SigId" SG_ 2566845952 EngExhTemp 1103;
BA_ "CI_SigName" SG_ 2566845952 EngExhTemp "Engine Exhaust Temperature";
BA_ "GenSigTimeoutTime_FMS4" SG_ 2566845952 EngExhTemp 500;
BA_ "GenSigTimeoutTime_NBM___" SG_ 2566845952 EngExhTemp 500;
BA_ "GenSigTimeoutTime_PCM" SG_ 2566845952 EngExhTemp 500;
BA_ "GenSigTimeoutTime_SGW__" SG_ 2566845952 EngExhTemp 500;
BA_ "GenSigTimeoutTime_VCM_" SG_ 2566845952 EngExhTemp 500;
BA_ "GenSigTimeoutTime_VCM__" SG_ 2566845952 EngExhTemp 500;
BA_ "SPN" SG_ 2566845952 EngExhTemp 173;
BA_ "SigType" SG_ 2566845952 EngExhTemp 1;
BA_ "CI_ParId" SG_ 2566910080 EngPwrInfo "IB050";
BA_ "CI_SigId" SG_ 2566910080 EngPwrInfo 1121;
BA_ "CI_SigName" SG_ 2566910080 EngPwrInfo "Engine Power Information";
BA_ "GenSigTimeoutTime_FMS4" SG_ 2566910080 EngPwrInfo 2500;
BA_ "GenSigTimeoutTime_MulticII" SG_ 2566910080 EngPwrInfo 2500;
BA_ "GenSigTimeoutTime_PCM" SG_ 2566910080 EngPwrInfo 2500;
BA_ "GenSigTimeoutTime_SGW__" SG_ 2566910080 EngPwrInfo 2500;
BA_ "SigType" SG_ 2566910080 EngPwrInfo 1;
BA_ "CI_ParId" SG_ 2566910080 EngPwrLoss "IB051";
BA_ "CI_SigId" SG_ 2566910080 EngPwrLoss 1122;
BA_ "CI_SigName" SG_ 2566910080 EngPwrLoss "Engine Power Losses";
BA_ "GenSigTimeoutTime_FMS4" SG_ 2566910080 EngPwrLoss 2500;
BA_ "GenSigTimeoutTime_MulticII" SG_ 2566910080 EngPwrLoss 2500;
BA_ "GenSigTimeoutTime_PCM" SG_ 2566910080 EngPwrLoss 2500;
BA_ "GenSigTimeoutTime_SGW__" SG_ 2566910080 EngPwrLoss 2500;
BA_ "SigType" SG_ 2566910080 EngPwrLoss 1;
BA_ "CI_ParId" SG_ 2566910080 EngV "IB052";
BA_ "CI_SigId" SG_ 2566910080 EngV 1123;
BA_ "CI_SigName" SG_ 2566910080 EngV "Engine Voltage";
BA_ "GenSigTimeoutTime_FMS4" SG_ 2566910080 EngV 2500;
BA_ "GenSigTimeoutTime_MulticII" SG_ 2566910080 EngV 2500;
BA_ "GenSigTimeoutTime_PCM" SG_ 2566910080 EngV 2500;
BA_ "GenSigTimeoutTime_SGW__" SG_ 2566910080 EngV 2500;
BA_ "SigType" SG_ 2566910080 EngV 1;
BA_ "CI_ParId" SG_ 2566910080 EngCur "IB053";
BA_ "CI_SigId" SG_ 2566910080 EngCur 1124;
BA_ "CI_SigName" SG_ 2566910080 EngCur "Engine Current";
BA_ "GenSigTimeoutTime_FMS4" SG_ 2566910080 EngCur 2500;
BA_ "GenSigTimeoutTime_MulticII" SG_ 2566910080 EngCur 2500;
BA_ "GenSigTimeoutTime_PCM" SG_ 2566910080 EngCur 2500;
BA_ "GenSigTimeoutTime_SGW__" SG_ 2566910080 EngCur 2500;
BA_ "SigType" SG_ 2566910080 EngCur 1;
BA_ "CI_ParId" SG_ 2566910080 Aux1AcPwr "IB054";
BA_ "CI_SigId" SG_ 2566910080 Aux1AcPwr 1125;
BA_ "CI_SigName" SG_ 2566910080 Aux1AcPwr "Auxiliary1 AC Power";
BA_ "GenSigTimeoutTime_FMS4" SG_ 2566910080 Aux1AcPwr 2500;
BA_ "GenSigTimeoutTime_MulticII" SG_ 2566910080 Aux1AcPwr 2500;
BA_ "GenSigTimeoutTime_PCM" SG_ 2566910080 Aux1AcPwr 2500;
BA_ "GenSigTimeoutTime_SGW__" SG_ 2566910080 Aux1AcPwr 2500;
BA_ "SigType" SG_ 2566910080 Aux1AcPwr 1;
BA_ "CI_ParId" SG_ 2566910080 Aux1DcPwr "IB055";
BA_ "CI_SigId" SG_ 2566910080 Aux1DcPwr 1126;
BA_ "CI_SigName" SG_ 2566910080 Aux1DcPwr "Auxiliary1 DC Power";
BA_ "GenSigTimeoutTime_FMS4" SG_ 2566910080 Aux1DcPwr 2500;
BA_ "GenSigTimeoutTime_MulticII" SG_ 2566910080 Aux1DcPwr 2500;
BA_ "GenSigTimeoutTime_PCM" SG_ 2566910080 Aux1DcPwr 2500;
BA_ "GenSigTimeoutTime_SGW__" SG_ 2566910080 Aux1DcPwr 2500;
BA_ "SigType" SG_ 2566910080 Aux1DcPwr 1;
BA_ "CI_ParId" SG_ 2566910080 Aux2AcPwr "IB056";
BA_ "CI_SigId" SG_ 2566910080 Aux2AcPwr 1127;
BA_ "CI_SigName" SG_ 2566910080 Aux2AcPwr "Auxiliary2 AC Power";
BA_ "GenSigTimeoutTime_FMS4" SG_ 2566910080 Aux2AcPwr 2500;
BA_ "GenSigTimeoutTime_MulticII" SG_ 2566910080 Aux2AcPwr 2500;
BA_ "GenSigTimeoutTime_PCM" SG_ 2566910080 Aux2AcPwr 2500;
BA_ "GenSigTimeoutTime_SGW__" SG_ 2566910080 Aux2AcPwr 2500;
BA_ "SigType" SG_ 2566910080 Aux2AcPwr 1;
BA_ "CI_ParId" SG_ 2566910080 Aux2DcPwr "IB057";
BA_ "CI_SigId" SG_ 2566910080 Aux2DcPwr 1128;
BA_ "CI_SigName" SG_ 2566910080 Aux2DcPwr "Auxiliary2 DC Power";
BA_ "GenSigTimeoutTime_FMS4" SG_ 2566910080 Aux2DcPwr 2500;
BA_ "GenSigTimeoutTime_MulticII" SG_ 2566910080 Aux2DcPwr 2500;
BA_ "GenSigTimeoutTime_PCM" SG_ 2566910080 Aux2DcPwr 2500;
BA_ "GenSigTimeoutTime_SGW__" SG_ 2566910080 Aux2DcPwr 2500;
BA_ "SigType" SG_ 2566910080 Aux2DcPwr 1;
BA_ "CI_ParId" SG_ 2566909824 HighVEnergyChgdTot "IB058";
BA_ "CI_SigId" SG_ 2566909824 HighVEnergyChgdTot 1130;
BA_ "CI_SigName" SG_ 2566909824 HighVEnergyChgdTot "High Voltage Energy Charged Total";
BA_ "GenSigTimeoutTime_FMS4" SG_ 2566909824 HighVEnergyChgdTot 5000;
BA_ "GenSigTimeoutTime_MulticS_" SG_ 2566909824 HighVEnergyChgdTot 5000;
BA_ "GenSigTimeoutTime_PCM" SG_ 2566909824 HighVEnergyChgdTot 5000;
BA_ "GenSigTimeoutTime_SGW__" SG_ 2566909824 HighVEnergyChgdTot 5000;
BA_ "SigType" SG_ 2566909824 HighVEnergyChgdTot 1;
BA_ "CI_ParId" SG_ 2566786839 LangCodeCmd "2410";
BA_ "CI_SigId" SG_ 2566786839 LangCodeCmd 2645;
BA_ "CI_SigName" SG_ 2566786839 LangCodeCmd "Language Code Command";
BA_ "GenSigTimeoutTime_PCM" SG_ 2566786839 LangCodeCmd 5000;
BA_ "GenSigTimeoutTime_SGW__" SG_ 2566786839 LangCodeCmd 5000;
BA_ "SPN" SG_ 2566786839 LangCodeCmd 2410;
BA_ "SigType" SG_ 2566786839 LangCodeCmd 3;
BA_ "CI_ParId" SG_ 2566842624 EngTotFuelUsed "250";
BA_ "CI_SigId" SG_ 2566842624 EngTotFuelUsed 1107;
BA_ "CI_SigName" SG_ 2566842624 EngTotFuelUsed "Engine Total Fuel Used";
BA_ "GenSigTimeoutTime_FMS4" SG_ 2566842624 EngTotFuelUsed 5000;
BA_ "GenSigTimeoutTime_MulticS" SG_ 2566842624 EngTotFuelUsed 5000;
BA_ "GenSigTimeoutTime_PCM" SG_ 2566842624 EngTotFuelUsed 5000;
BA_ "GenSigTimeoutTime_SGW__" SG_ 2566842624 EngTotFuelUsed 5000;
BA_ "GenSigTimeoutTime_VCM_" SG_ 2566842624 EngTotFuelUsed 5000;
BA_ "GenSigTimeoutTime_VCM__" SG_ 2566842624 EngTotFuelUsed 5000;
BA_ "SPN" SG_ 2566842624 EngTotFuelUsed 250;
BA_ "SigType" SG_ 2566842624 EngTotFuelUsed 1;
BA_ "CI_ParId" SG_ 2566844928 EngFuelRate "183";
BA_ "CI_SigId" SG_ 2566844928 EngFuelRate 1173;
BA_ "CI_SigName" SG_ 2566844928 EngFuelRate "Engine Fuel Rate";
BA_ "GenSigTimeoutTime_FMS4" SG_ 2566844928 EngFuelRate 500;
BA_ "GenSigTimeoutTime_MulticS" SG_ 2566844928 EngFuelRate 500;
BA_ "GenSigTimeoutTime_MulticS__" SG_ 2566844928 EngFuelRate 500;
BA_ "GenSigTimeoutTime_PCM" SG_ 2566844928 EngFuelRate 500;
BA_ "GenSigTimeoutTime_SGW__" SG_ 2566844928 EngFuelRate 500;
BA_ "GenSigTimeoutTime_VCM_" SG_ 2566844928 EngFuelRate 500;
BA_ "GenSigTimeoutTime_VCM__" SG_ 2566844928 EngFuelRate 500;
BA_ "SPN" SG_ 2566844928 EngFuelRate 183;
BA_ "SigType" SG_ 2566844928 EngFuelRate 1;
BA_ "CI_ParId" SG_ 2566844928 EngInstFuelEcon "184";
BA_ "CI_SigId" SG_ 2566844928 EngInstFuelEcon 1174;
BA_ "CI_SigName" SG_ 2566844928 EngInstFuelEcon "Engine Instantaneous Fuel Economy";
BA_ "GenSigTimeoutTime_FMS4" SG_ 2566844928 EngInstFuelEcon 500;
BA_ "GenSigTimeoutTime_MulticS" SG_ 2566844928 EngInstFuelEcon 500;
BA_ "GenSigTimeoutTime_PCM" SG_ 2566844928 EngInstFuelEcon 500;
BA_ "GenSigTimeoutTime_SGW__" SG_ 2566844928 EngInstFuelEcon 500;
BA_ "GenSigTimeoutTime_VCM_" SG_ 2566844928 EngInstFuelEcon 500;
BA_ "GenSigTimeoutTime_VCM__" SG_ 2566844928 EngInstFuelEcon 500;
BA_ "SPN" SG_ 2566844928 EngInstFuelEcon 184;
BA_ "SigType" SG_ 2566844928 EngInstFuelEcon 1;
BA_ "CI_ParId" SG_ 2566844928 EngAvgFuelEcon "185";
BA_ "CI_SigId" SG_ 2566844928 EngAvgFuelEcon 1175;
BA_ "CI_SigName" SG_ 2566844928 EngAvgFuelEcon "Engine Average Fuel Economy";
BA_ "GenSigTimeoutTime_PCM" SG_ 2566844928 EngAvgFuelEcon 500;
BA_ "GenSigTimeoutTime_SGW__" SG_ 2566844928 EngAvgFuelEcon 500;
BA_ "GenSigTimeoutTime_VCM_" SG_ 2566844928 EngAvgFuelEcon 500;
BA_ "GenSigTimeoutTime_VCM__" SG_ 2566844928 EngAvgFuelEcon 500;
BA_ "SPN" SG_ 2566844928 EngAvgFuelEcon 185;
BA_ "SigType" SG_ 2566844928 EngAvgFuelEcon 1;
BA_ "CI_ParId" SG_ 2566861299 ActBatSysV "IB179";
BA_ "CI_SigId" SG_ 2566861299 ActBatSysV 1483;
BA_ "CI_SigName" SG_ 2566861299 ActBatSysV "Actual Battery System Voltage";
BA_ "GenSigTimeoutTime_CANAIR" SG_ 2566861299 ActBatSysV 25000;
BA_ "GenSigTimeoutTime_FMS4" SG_ 2566861299 ActBatSysV 25000;
BA_ "GenSigTimeoutTime_MulticS_" SG_ 2566861299 ActBatSysV 25000;
BA_ "GenSigTimeoutTime_NBM__" SG_ 2566861299 ActBatSysV 25000;
BA_ "GenSigTimeoutTime_PCM" SG_ 2566861299 ActBatSysV 25000;
BA_ "GenSigTimeoutTime_SGW__" SG_ 2566861299 ActBatSysV 25000;
BA_ "SigType" SG_ 2566861299 ActBatSysV 1;
BA_ "CI_ParId" SG_ 2566861299 ActBatSysCur "IB180";
BA_ "CI_SigId" SG_ 2566861299 ActBatSysCur 1484;
BA_ "CI_SigName" SG_ 2566861299 ActBatSysCur "Actual Battery System Current";
BA_ "GenSigTimeoutTime_FMS4" SG_ 2566861299 ActBatSysCur 25000;
BA_ "GenSigTimeoutTime_MulticS_" SG_ 2566861299 ActBatSysCur 25000;
BA_ "GenSigTimeoutTime_NBM__" SG_ 2566861299 ActBatSysCur 25000;
BA_ "GenSigTimeoutTime_PCM" SG_ 2566861299 ActBatSysCur 25000;
BA_ "GenSigTimeoutTime_SGW__" SG_ 2566861299 ActBatSysCur 25000;
BA_ "SigType" SG_ 2566861299 ActBatSysCur 1;
BA_ "CI_ParId" SG_ 2566861299 MaxSysChgCur "IB181";
BA_ "CI_SigId" SG_ 2566861299 MaxSysChgCur 1485;
BA_ "CI_SigName" SG_ 2566861299 MaxSysChgCur "Maximum System Charge Current";
BA_ "GenSigTimeoutTime_FMS4" SG_ 2566861299 MaxSysChgCur 25000;
BA_ "GenSigTimeoutTime_MulticS_" SG_ 2566861299 MaxSysChgCur 25000;
BA_ "GenSigTimeoutTime_NBM__" SG_ 2566861299 MaxSysChgCur 25000;
BA_ "GenSigTimeoutTime_PCM" SG_ 2566861299 MaxSysChgCur 25000;
BA_ "GenSigTimeoutTime_SGW__" SG_ 2566861299 MaxSysChgCur 25000;
BA_ "SigType" SG_ 2566861299 MaxSysChgCur 1;
BA_ "CI_ParId" SG_ 2566861299 MaxSysDischCur "IB182";
BA_ "CI_SigId" SG_ 2566861299 MaxSysDischCur 1486;
BA_ "CI_SigName" SG_ 2566861299 MaxSysDischCur "Maximum System Discharge Current";
BA_ "GenSigTimeoutTime_FMS4" SG_ 2566861299 MaxSysDischCur 25000;
BA_ "GenSigTimeoutTime_MulticS_" SG_ 2566861299 MaxSysDischCur 25000;
BA_ "GenSigTimeoutTime_NBM__" SG_ 2566861299 MaxSysDischCur 25000;
BA_ "GenSigTimeoutTime_PCM" SG_ 2566861299 MaxSysDischCur 25000;
BA_ "GenSigTimeoutTime_SGW__" SG_ 2566861299 MaxSysDischCur 25000;
BA_ "SigType" SG_ 2566861299 MaxSysDischCur 1;
BA_ "CI_ParId" SG_ 2566861555 MaxBatSysTemp "IB190";
BA_ "CI_SigId" SG_ 2566861555 MaxBatSysTemp 1509;
BA_ "CI_SigName" SG_ 2566861555 MaxBatSysTemp "Maximum Battery System Temperature";
BA_ "GenSigTimeoutTime_FMS4" SG_ 2566861555 MaxBatSysTemp 25000;
BA_ "GenSigTimeoutTime_MulticS_" SG_ 2566861555 MaxBatSysTemp 25000;
BA_ "GenSigTimeoutTime_NBM__" SG_ 2566861555 MaxBatSysTemp 25000;
BA_ "GenSigTimeoutTime_PCM" SG_ 2566861555 MaxBatSysTemp 25000;
BA_ "GenSigTimeoutTime_SGW__" SG_ 2566861555 MaxBatSysTemp 25000;
BA_ "SigType" SG_ 2566861555 MaxBatSysTemp 1;
BA_ "CI_ParId" SG_ 2566861555 MinBatSysTemp "IB191";
BA_ "CI_SigId" SG_ 2566861555 MinBatSysTemp 1510;
BA_ "CI_SigName" SG_ 2566861555 MinBatSysTemp "Minimum Battery System Temperature";
BA_ "GenSigTimeoutTime_FMS4" SG_ 2566861555 MinBatSysTemp 25000;
BA_ "GenSigTimeoutTime_MulticS_" SG_ 2566861555 MinBatSysTemp 25000;
BA_ "GenSigTimeoutTime_NBM__" SG_ 2566861555 MinBatSysTemp 25000;
BA_ "GenSigTimeoutTime_PCM" SG_ 2566861555 MinBatSysTemp 25000;
BA_ "GenSigTimeoutTime_SGW__" SG_ 2566861555 MinBatSysTemp 25000;
BA_ "SigType" SG_ 2566861555 MinBatSysTemp 1;
BA_ "CI_ParId" SG_ 2566861555 PacksOnLine "IB193";
BA_ "CI_SigId" SG_ 2566861555 PacksOnLine 1512;
BA_ "CI_SigName" SG_ 2566861555 PacksOnLine "Packs on Line";
BA_ "GenSigTimeoutTime_FMS4" SG_ 2566861555 PacksOnLine 25000;
BA_ "GenSigTimeoutTime_MulticS_" SG_ 2566861555 PacksOnLine 25000;
BA_ "GenSigTimeoutTime_PCM" SG_ 2566861555 PacksOnLine 25000;
BA_ "GenSigTimeoutTime_SGW__" SG_ 2566861555 PacksOnLine 25000;
BA_ "SigType" SG_ 2566861555 PacksOnLine 1;
BA_ "CI_ParId" SG_ 2566861555 BatSysDeltaCellV "IB196";
BA_ "CI_SigId" SG_ 2566861555 BatSysDeltaCellV 1515;
BA_ "CI_SigName" SG_ 2566861555 BatSysDeltaCellV "Battery System Delta Cell Voltage";
BA_ "GenSigTimeoutTime_FMS4" SG_ 2566861555 BatSysDeltaCellV 25000;
BA_ "GenSigTimeoutTime_MulticS_" SG_ 2566861555 BatSysDeltaCellV 25000;
BA_ "GenSigTimeoutTime_PCM" SG_ 2566861555 BatSysDeltaCellV 25000;
BA_ "GenSigTimeoutTime_SGW__" SG_ 2566861555 BatSysDeltaCellV 25000;
BA_ "SigType" SG_ 2566861555 BatSysDeltaCellV 1;
BA_ "CI_ParId" SG_ 2566776097 MaxVsl1 "2588";
BA_ "CI_SigId" SG_ 2566776097 MaxVsl1 2176;
BA_ "CI_SigName" SG_ 2566776097 MaxVsl1 "Maximum Vehicle Speed Limit 1";
BA_ "GenSigTimeoutTime_PCM" SG_ 2566776097 MaxVsl1 5000;
BA_ "GenSigTimeoutTime_SGW__" SG_ 2566776097 MaxVsl1 5000;
BA_ "GenSigTimeoutTime_VCU_" SG_ 2566776097 MaxVsl1 5000;
BA_ "GenSigTimeoutTime_VMU" SG_ 2566776097 MaxVsl1 5000;
BA_ "SPN" SG_ 2566776097 MaxVsl1 2588;
BA_ "SigType" SG_ 2566776097 MaxVsl1 1;
BA_ "CI_ParId" SG_ 2566776097 AppliedVsl "2595";
BA_ "CI_SigId" SG_ 2566776097 AppliedVsl 2177;
BA_ "CI_SigName" SG_ 2566776097 AppliedVsl "Applied Vehicle Speed Limit";
BA_ "GenSigTimeoutTime_PCM" SG_ 2566776097 AppliedVsl 5000;
BA_ "GenSigTimeoutTime_SGW__" SG_ 2566776097 AppliedVsl 5000;
BA_ "SPN" SG_ 2566776097 AppliedVsl 2595;
BA_ "SigType" SG_ 2566776097 AppliedVsl 1;
BA_ "CI_ParId" SG_ 2365443105 TurnSigSw "2876";
BA_ "CI_SigId" SG_ 2365443105 TurnSigSw 2629;
BA_ "CI_SigName" SG_ 2365443105 TurnSigSw "Turn Signal Switch";
BA_ "GenSigTimeoutTime_ADCU" SG_ 2365443105 TurnSigSw 1250;
BA_ "GenSigTimeoutTime_PCM" SG_ 2365443105 TurnSigSw 1250;
BA_ "GenSigTimeoutTime_SGW__" SG_ 2365443105 TurnSigSw 1250;
BA_ "SPN" SG_ 2365443105 TurnSigSw 2876;
BA_ "CI_ParId" SG_ 2566769953 FrontOpWiperSw "2863";
BA_ "CI_SigId" SG_ 2566769953 FrontOpWiperSw 2636;
BA_ "CI_SigName" SG_ 2566769953 FrontOpWiperSw "Front Operator Wiper Switch";
BA_ "GenSigSendType" SG_ 2566769953 FrontOpWiperSw 3;
BA_ "GenSigTimeoutTime_ADCU" SG_ 2566769953 FrontOpWiperSw 5000;
BA_ "GenSigTimeoutTime_PCM" SG_ 2566769953 FrontOpWiperSw 5000;
BA_ "GenSigTimeoutTime_SGW__" SG_ 2566769953 FrontOpWiperSw 5000;
BA_ "SPN" SG_ 2566769953 FrontOpWiperSw 2863;
BA_ "CI_ParId" SG_ 2566769953 FrontOpWasherSw "2866";
BA_ "CI_SigId" SG_ 2566769953 FrontOpWasherSw 2642;
BA_ "CI_SigName" SG_ 2566769953 FrontOpWasherSw "Front Operator Washer Switch";
BA_ "GenSigSendType" SG_ 2566769953 FrontOpWasherSw 3;
BA_ "GenSigTimeoutTime_ADCU" SG_ 2566769953 FrontOpWasherSw 5000;
BA_ "GenSigTimeoutTime_PCM" SG_ 2566769953 FrontOpWasherSw 5000;
BA_ "GenSigTimeoutTime_SGW__" SG_ 2566769953 FrontOpWasherSw 5000;
BA_ "SPN" SG_ 2566769953 FrontOpWasherSw 2866;
BA_ "CI_ParId" SG_ 2566908574 DrowsDrivLev "IS939";
BA_ "CI_SigId" SG_ 2566908574 DrowsDrivLev 628;
BA_ "CI_SigName" SG_ 2566908574 DrowsDrivLev "Drowsiness Driver Level";
BA_ "GenSigTimeoutTime_MulticII" SG_ 2566908574 DrowsDrivLev 1000;
BA_ "GenSigTimeoutTime_MulticS" SG_ 2566908574 DrowsDrivLev 1000;
BA_ "GenSigTimeoutTime_MulticS_" SG_ 2566908574 DrowsDrivLev 1000;
BA_ "GenSigTimeoutTime_MulticS__" SG_ 2566908574 DrowsDrivLev 1000;
BA_ "GenSigTimeoutTime_PCM" SG_ 2566908574 DrowsDrivLev 1000;
BA_ "GenSigTimeoutTime_SGW__" SG_ 2566908574 DrowsDrivLev 1000;
BA_ "CI_ParId" SG_ 2566908574 DdawRunMode "IMH0104";
BA_ "CI_SigId" SG_ 2566908574 DdawRunMode 629;
BA_ "CI_SigName" SG_ 2566908574 DdawRunMode "DDAW Running Mode";
BA_ "GenSigTimeoutTime_MulticII" SG_ 2566908574 DdawRunMode 1000;
BA_ "GenSigTimeoutTime_MulticS" SG_ 2566908574 DdawRunMode 1000;
BA_ "GenSigTimeoutTime_MulticS_" SG_ 2566908574 DdawRunMode 1000;
BA_ "GenSigTimeoutTime_MulticS__" SG_ 2566908574 DdawRunMode 1000;
BA_ "GenSigTimeoutTime_NBM" SG_ 2566908574 DdawRunMode 1000;
BA_ "GenSigTimeoutTime_NBM_" SG_ 2566908574 DdawRunMode 1000;
BA_ "GenSigTimeoutTime_PCM" SG_ 2566908574 DdawRunMode 1000;
BA_ "GenSigTimeoutTime_SGW__" SG_ 2566908574 DdawRunMode 1000;
BA_ "CI_ParId" SG_ 2566907159 DrivDrowsWarnEnaSet "IS979";
BA_ "CI_SigId" SG_ 2566907159 DrivDrowsWarnEnaSet 4019;
BA_ "CI_SigName" SG_ 2566907159 DrivDrowsWarnEnaSet "Driver Drowsiness Warning Enable Setting ";
BA_ "GenSigSendType" SG_ 2566907159 DrivDrowsWarnEnaSet 3;
BA_ "GenSigTimeoutTime_ADCU" SG_ 2566907159 DrivDrowsWarnEnaSet 500;
BA_ "GenSigTimeoutTime_PCM" SG_ 2566907159 DrivDrowsWarnEnaSet 500;
BA_ "GenSigTimeoutTime_SGW__" SG_ 2566907159 DrivDrowsWarnEnaSet 500;
BA_ "SigType" SG_ 2566907159 DrivDrowsWarnEnaSet 4;
BA_ "CI_ParId" SG_ 2566907159 LeftSpeakFail "IMH0171";
BA_ "CI_SigId" SG_ 2566907159 LeftSpeakFail 4020;
BA_ "CI_SigName" SG_ 2566907159 LeftSpeakFail "Left Speaker Failure";
BA_ "GenSigSendType" SG_ 2566907159 LeftSpeakFail 3;
BA_ "GenSigTimeoutTime_ADCU" SG_ 2566907159 LeftSpeakFail 500;
BA_ "GenSigTimeoutTime_PCM" SG_ 2566907159 LeftSpeakFail 500;
BA_ "GenSigTimeoutTime_SGW__" SG_ 2566907159 LeftSpeakFail 500;
BA_ "SigType" SG_ 2566907159 LeftSpeakFail 4;
BA_ "CI_ParId" SG_ 2566907159 RightSpeakFail "IMH0172";
BA_ "CI_SigId" SG_ 2566907159 RightSpeakFail 4021;
BA_ "CI_SigName" SG_ 2566907159 RightSpeakFail "Right Speaker Failure";
BA_ "GenSigSendType" SG_ 2566907159 RightSpeakFail 3;
BA_ "GenSigTimeoutTime_ADCU" SG_ 2566907159 RightSpeakFail 500;
BA_ "GenSigTimeoutTime_PCM" SG_ 2566907159 RightSpeakFail 500;
BA_ "GenSigTimeoutTime_SGW__" SG_ 2566907159 RightSpeakFail 500;
BA_ "SigType" SG_ 2566907159 RightSpeakFail 4;
BA_ "CI_ParId" SG_ 2566907159 BuzFail "IMH0173";
BA_ "CI_SigId" SG_ 2566907159 BuzFail 4022;
BA_ "CI_SigName" SG_ 2566907159 BuzFail "Buzzer Failure";
BA_ "GenSigSendType" SG_ 2566907159 BuzFail 3;
BA_ "GenSigTimeoutTime_ADCU" SG_ 2566907159 BuzFail 500;
BA_ "GenSigTimeoutTime_PCM" SG_ 2566907159 BuzFail 500;
BA_ "GenSigTimeoutTime_SGW__" SG_ 2566907159 BuzFail 500;
BA_ "SigType" SG_ 2566907159 BuzFail 4;
BA_ "CI_ParId" SG_ 2566907159 LeftLedbarFail "IMH0174";
BA_ "CI_SigId" SG_ 2566907159 LeftLedbarFail 4023;
BA_ "CI_SigName" SG_ 2566907159 LeftLedbarFail "Left Ledbar Failure";
BA_ "GenSigSendType" SG_ 2566907159 LeftLedbarFail 3;
BA_ "GenSigTimeoutTime_ADCU" SG_ 2566907159 LeftLedbarFail 500;
BA_ "GenSigTimeoutTime_PCM" SG_ 2566907159 LeftLedbarFail 500;
BA_ "GenSigTimeoutTime_SGW__" SG_ 2566907159 LeftLedbarFail 500;
BA_ "SigType" SG_ 2566907159 LeftLedbarFail 4;
BA_ "CI_ParId" SG_ 2566907159 RightLedbarFail "IMH0175";
BA_ "CI_SigId" SG_ 2566907159 RightLedbarFail 4024;
BA_ "CI_SigName" SG_ 2566907159 RightLedbarFail "Right Ledbar Failure";
BA_ "GenSigSendType" SG_ 2566907159 RightLedbarFail 3;
BA_ "GenSigTimeoutTime_ADCU" SG_ 2566907159 RightLedbarFail 500;
BA_ "GenSigTimeoutTime_PCM" SG_ 2566907159 RightLedbarFail 500;
BA_ "GenSigTimeoutTime_SGW__" SG_ 2566907159 RightLedbarFail 500;
BA_ "SigType" SG_ 2566907159 RightLedbarFail 4;
BA_ "CI_ParId" SG_ 2566907159 PlcaFuncEn "IMH0179";
BA_ "CI_SigId" SG_ 2566907159 PlcaFuncEn 4025;
BA_ "CI_SigName" SG_ 2566907159 PlcaFuncEn "Passive Lane Change Assist Function Enable";
BA_ "GenSigSendType" SG_ 2566907159 PlcaFuncEn 3;
BA_ "GenSigTimeoutTime_ADCU" SG_ 2566907159 PlcaFuncEn 500;
BA_ "GenSigTimeoutTime_PCM" SG_ 2566907159 PlcaFuncEn 500;
BA_ "GenSigTimeoutTime_SGW__" SG_ 2566907159 PlcaFuncEn 500;
BA_ "SigType" SG_ 2566907159 PlcaFuncEn 4;
BA_ "CI_ParId" SG_ 2566907159 PlcaWarnEn "IMH0178";
BA_ "CI_SigId" SG_ 2566907159 PlcaWarnEn 4026;
BA_ "CI_SigName" SG_ 2566907159 PlcaWarnEn "Passive Lane Change Assist Warning Enable";
BA_ "GenSigSendType" SG_ 2566907159 PlcaWarnEn 3;
BA_ "GenSigTimeoutTime_ADCU" SG_ 2566907159 PlcaWarnEn 500;
BA_ "GenSigTimeoutTime_PCM" SG_ 2566907159 PlcaWarnEn 500;
BA_ "GenSigTimeoutTime_SGW__" SG_ 2566907159 PlcaWarnEn 500;
BA_ "SigType" SG_ 2566907159 PlcaWarnEn 4;
BA_ "CI_ParId" SG_ 2566907159 BsisFuncEn "IMH0180";
BA_ "CI_SigId" SG_ 2566907159 BsisFuncEn 4027;
BA_ "CI_SigName" SG_ 2566907159 BsisFuncEn "Blind Spot Information System Function Enable";
BA_ "GenSigSendType" SG_ 2566907159 BsisFuncEn 3;
BA_ "GenSigTimeoutTime_ADCU" SG_ 2566907159 BsisFuncEn 500;
BA_ "GenSigTimeoutTime_PCM" SG_ 2566907159 BsisFuncEn 500;
BA_ "GenSigTimeoutTime_SGW__" SG_ 2566907159 BsisFuncEn 500;
BA_ "SigType" SG_ 2566907159 BsisFuncEn 4;
BA_ "CI_ParId" SG_ 2566907159 LeftVibratorFail "IMH0187";
BA_ "CI_SigId" SG_ 2566907159 LeftVibratorFail 4028;
BA_ "CI_SigName" SG_ 2566907159 LeftVibratorFail "Left Vibrator Failure";
BA_ "GenSigSendType" SG_ 2566907159 LeftVibratorFail 3;
BA_ "GenSigTimeoutTime_ADCU" SG_ 2566907159 LeftVibratorFail 500;
BA_ "GenSigTimeoutTime_NBM" SG_ 2566907159 LeftVibratorFail 500;
BA_ "GenSigTimeoutTime_PCM" SG_ 2566907159 LeftVibratorFail 500;
BA_ "GenSigTimeoutTime_SGW__" SG_ 2566907159 LeftVibratorFail 500;
BA_ "SigType" SG_ 2566907159 LeftVibratorFail 4;
BA_ "CI_ParId" SG_ 2566907159 RightVibratorFail "IMH0188";
BA_ "CI_SigId" SG_ 2566907159 RightVibratorFail 4029;
BA_ "CI_SigName" SG_ 2566907159 RightVibratorFail "Right Vibrator Failure";
BA_ "GenSigSendType" SG_ 2566907159 RightVibratorFail 3;
BA_ "GenSigTimeoutTime_ADCU" SG_ 2566907159 RightVibratorFail 500;
BA_ "GenSigTimeoutTime_NBM" SG_ 2566907159 RightVibratorFail 500;
BA_ "GenSigTimeoutTime_PCM" SG_ 2566907159 RightVibratorFail 500;
BA_ "GenSigTimeoutTime_SGW__" SG_ 2566907159 RightVibratorFail 500;
BA_ "SigType" SG_ 2566907159 RightVibratorFail 4;
BA_ "CI_ParId" SG_ 2566907159 LdwsCsfPreSel "IMH0218";
BA_ "CI_SigId" SG_ 2566907159 LdwsCsfPreSel 14751;
BA_ "CI_SigName" SG_ 2566907159 LdwsCsfPreSel "LDWS CSF Pre-selection";
BA_ "GenSigSendType" SG_ 2566907159 LdwsCsfPreSel 3;
BA_ "GenSigTimeoutTime_ADCU" SG_ 2566907159 LdwsCsfPreSel 500;
BA_ "GenSigTimeoutTime_NBM" SG_ 2566907159 LdwsCsfPreSel 500;
BA_ "GenSigTimeoutTime_PCM" SG_ 2566907159 LdwsCsfPreSel 500;
BA_ "GenSigTimeoutTime_SGW__" SG_ 2566907159 LdwsCsfPreSel 500;
BA_ "GenSigTimeoutTime_VCM" SG_ 2566907159 LdwsCsfPreSel 500;
BA_ "SigType" SG_ 2566907159 LdwsCsfPreSel 4;
BA_ "CI_ParId" SG_ 2566907159 MsgCnt "4206";
BA_ "CI_SigId" SG_ 2566907159 MsgCnt 4030;
BA_ "CI_SigName" SG_ 2566907159 MsgCnt "Message Counter";
BA_ "GenSigSendType" SG_ 2566907159 MsgCnt 3;
BA_ "GenSigTimeoutTime_ADCU" SG_ 2566907159 MsgCnt 500;
BA_ "GenSigTimeoutTime_PCM" SG_ 2566907159 MsgCnt 500;
BA_ "GenSigTimeoutTime_SGW__" SG_ 2566907159 MsgCnt 500;
BA_ "SPN" SG_ 2566907159 MsgCnt 4206;
BA_ "CI_ParId" SG_ 2566907159 MsgCks "4207";
BA_ "CI_SigId" SG_ 2566907159 MsgCks 4031;
BA_ "CI_SigName" SG_ 2566907159 MsgCks "Message Checksum";
BA_ "GenSigSendType" SG_ 2566907159 MsgCks 3;
BA_ "GenSigTimeoutTime_ADCU" SG_ 2566907159 MsgCks 500;
BA_ "GenSigTimeoutTime_PCM" SG_ 2566907159 MsgCks 500;
BA_ "GenSigTimeoutTime_SGW__" SG_ 2566907159 MsgCks 500;
BA_ "SPN" SG_ 2566907159 MsgCks 4207;
BA_ "CI_ParId" SG_ 2566894871 IntlSpeedAssantActv "IS949";
BA_ "CI_SigId" SG_ 2566894871 IntlSpeedAssantActv 2813;
BA_ "CI_SigName" SG_ 2566894871 IntlSpeedAssantActv "Intelligent Speed Assistant Activation";
BA_ "GenSigSendType" SG_ 2566894871 IntlSpeedAssantActv 3;
BA_ "GenSigTimeoutTime_ADCU" SG_ 2566894871 IntlSpeedAssantActv 5000;
BA_ "CI_ParId" SG_ 2566894871 CntryCode "IMH0088";
BA_ "CI_SigId" SG_ 2566894871 CntryCode 2814;
BA_ "CI_SigName" SG_ 2566894871 CntryCode "Country Code";
BA_ "GenSigSendType" SG_ 2566894871 CntryCode 3;
BA_ "GenSigTimeoutTime_ADCU" SG_ 2566894871 CntryCode 5000;
BA_ "CI_ParId" SG_ 2566895006 MaxVslWarn "IS945";
BA_ "CI_SigId" SG_ 2566895006 MaxVslWarn 2804;
BA_ "CI_SigName" SG_ 2566895006 MaxVslWarn "Maximum Vehicle Speed Limit Warning";
BA_ "GenSigSendType" SG_ 2566895006 MaxVslWarn 3;
BA_ "GenSigTimeoutTime_MulticII" SG_ 2566895006 MaxVslWarn 5000;
BA_ "GenSigTimeoutTime_MulticS" SG_ 2566895006 MaxVslWarn 5000;
BA_ "GenSigTimeoutTime_MulticS_" SG_ 2566895006 MaxVslWarn 5000;
BA_ "GenSigTimeoutTime_MulticS__" SG_ 2566895006 MaxVslWarn 5000;
BA_ "GenSigTimeoutTime_PCM" SG_ 2566895006 MaxVslWarn 5000;
BA_ "GenSigTimeoutTime_SGW__" SG_ 2566895006 MaxVslWarn 5000;
BA_ "CI_ParId" SG_ 2566895006 IntlSpeedAssantActv_18FFB59E "IS949";
BA_ "CI_SigId" SG_ 2566895006 IntlSpeedAssantActv_18FFB59E 19926;
BA_ "CI_SigName" SG_ 2566895006 IntlSpeedAssantActv_18FFB59E "Intelligent Speed Assistant Activation";
BA_ "GenSigSendType" SG_ 2566895006 IntlSpeedAssantActv_18FFB59E 3;
BA_ "CI_ParId" SG_ 2566895006 IntlSpeedAssantSts "IS947";
BA_ "CI_SigId" SG_ 2566895006 IntlSpeedAssantSts 2806;
BA_ "CI_SigName" SG_ 2566895006 IntlSpeedAssantSts "Intelligent Speed Assistant Status";
BA_ "GenSigSendType" SG_ 2566895006 IntlSpeedAssantSts 3;
BA_ "GenSigTimeoutTime_MulticII" SG_ 2566895006 IntlSpeedAssantSts 5000;
BA_ "GenSigTimeoutTime_MulticS" SG_ 2566895006 IntlSpeedAssantSts 5000;
BA_ "GenSigTimeoutTime_MulticS_" SG_ 2566895006 IntlSpeedAssantSts 5000;
BA_ "GenSigTimeoutTime_MulticS__" SG_ 2566895006 IntlSpeedAssantSts 5000;
BA_ "GenSigTimeoutTime_PCM" SG_ 2566895006 IntlSpeedAssantSts 5000;
BA_ "GenSigTimeoutTime_SGW__" SG_ 2566895006 IntlSpeedAssantSts 5000;
BA_ "CI_ParId" SG_ 2566895006 IsaDbgSts "IS989";
BA_ "CI_SigId" SG_ 2566895006 IsaDbgSts 2807;
BA_ "CI_SigName" SG_ 2566895006 IsaDbgSts "ISA Debug Status";
BA_ "GenSigSendType" SG_ 2566895006 IsaDbgSts 3;
BA_ "GenSigTimeoutTime_PCM" SG_ 2566895006 IsaDbgSts 5000;
BA_ "GenSigTimeoutTime_SGW__" SG_ 2566895006 IsaDbgSts 5000;
BA_ "CI_ParId" SG_ 2566895006 CntryCodeCfg "IMH0087";
BA_ "CI_SigId" SG_ 2566895006 CntryCodeCfg 2808;
BA_ "CI_SigName" SG_ 2566895006 CntryCodeCfg "Country Code Configuration";
BA_ "GenSigSendType" SG_ 2566895006 CntryCodeCfg 3;
BA_ "GenSigTimeoutTime_MulticII" SG_ 2566895006 CntryCodeCfg 5000;
BA_ "GenSigTimeoutTime_MulticS" SG_ 2566895006 CntryCodeCfg 5000;
BA_ "GenSigTimeoutTime_MulticS_" SG_ 2566895006 CntryCodeCfg 5000;
BA_ "GenSigTimeoutTime_MulticS__" SG_ 2566895006 CntryCodeCfg 5000;
BA_ "GenSigTimeoutTime_PCM" SG_ 2566895006 CntryCodeCfg 5000;
BA_ "GenSigTimeoutTime_SGW__" SG_ 2566895006 CntryCodeCfg 5000;
BA_ "SigType" SG_ 2566895006 CntryCodeCfg 4;
BA_ "CI_ParId" SG_ 2566895006 CntryCode_18FFB59E "IMH0088";
BA_ "CI_SigId" SG_ 2566895006 CntryCode_18FFB59E 2809;
BA_ "CI_SigName" SG_ 2566895006 CntryCode_18FFB59E "Country Code";
BA_ "GenSigSendType" SG_ 2566895006 CntryCode_18FFB59E 3;
BA_ "GenSigTimeoutTime_MulticII" SG_ 2566895006 CntryCode_18FFB59E 5000;
BA_ "GenSigTimeoutTime_MulticS" SG_ 2566895006 CntryCode_18FFB59E 5000;
BA_ "GenSigTimeoutTime_MulticS_" SG_ 2566895006 CntryCode_18FFB59E 5000;
BA_ "GenSigTimeoutTime_MulticS__" SG_ 2566895006 CntryCode_18FFB59E 5000;
BA_ "GenSigTimeoutTime_PCM" SG_ 2566895006 CntryCode_18FFB59E 5000;
BA_ "GenSigTimeoutTime_SGW__" SG_ 2566895006 CntryCode_18FFB59E 5000;
BA_ "CI_ParId" SG_ 2566895006 MaxVslUnitless "IMH0119";
BA_ "CI_SigId" SG_ 2566895006 MaxVslUnitless 2810;
BA_ "CI_SigName" SG_ 2566895006 MaxVslUnitless "Maximum Vehicle Speed Limit Unitless";
BA_ "GenSigSendType" SG_ 2566895006 MaxVslUnitless 3;
BA_ "GenSigTimeoutTime_MulticII" SG_ 2566895006 MaxVslUnitless 5000;
BA_ "GenSigTimeoutTime_MulticS" SG_ 2566895006 MaxVslUnitless 5000;
BA_ "GenSigTimeoutTime_MulticS_" SG_ 2566895006 MaxVslUnitless 5000;
BA_ "GenSigTimeoutTime_MulticS__" SG_ 2566895006 MaxVslUnitless 5000;
BA_ "GenSigTimeoutTime_PCM" SG_ 2566895006 MaxVslUnitless 5000;
BA_ "GenSigTimeoutTime_SGW__" SG_ 2566895006 MaxVslUnitless 5000;
BA_ "CI_ParId" SG_ 2566895006 SpeedLimConf "IMH0182";
BA_ "CI_SigId" SG_ 2566895006 SpeedLimConf 2811;
BA_ "CI_SigName" SG_ 2566895006 SpeedLimConf "Speed Limit Confidence";
BA_ "GenSigSendType" SG_ 2566895006 SpeedLimConf 3;
BA_ "GenSigTimeoutTime_PCM" SG_ 2566895006 SpeedLimConf 5000;
BA_ "GenSigTimeoutTime_SGW__" SG_ 2566895006 SpeedLimConf 5000;
BA_ "SigType" SG_ 2566895006 SpeedLimConf 4;
BA_ "CI_ParId" SG_ 2566895006 IsaSpeedOverridden "IMH0223";
BA_ "CI_SigId" SG_ 2566895006 IsaSpeedOverridden 19927;
BA_ "CI_SigName" SG_ 2566895006 IsaSpeedOverridden "Isa Speed Overridden";
BA_ "GenSigSendType" SG_ 2566895006 IsaSpeedOverridden 3;
BA_ "SigType" SG_ 2566895006 IsaSpeedOverridden 4;
BA_ "CI_ParId" SG_ 2365575713 IgnOn "I013";
BA_ "CI_SigId" SG_ 2365575713 IgnOn 10488;
BA_ "CI_SigName" SG_ 2365575713 IgnOn "Ignition On";
BA_ "GenSigSendType" SG_ 2365575713 IgnOn 3;
BA_ "GenSigTimeoutTime_CAID" SG_ 2365575713 IgnOn 5000;
BA_ "GenSigTimeoutTime_PCM" SG_ 2365575713 IgnOn 5000;
BA_ "GenSigTimeoutTime_SGW2" SG_ 2365575713 IgnOn 5000;
BA_ "GenSigTimeoutTime_SGW__" SG_ 2365575713 IgnOn 5000;
BA_ "GenSigTimeoutTime_SIU" SG_ 2365575713 IgnOn 5000;
BA_ "GenSigTimeoutTime_TPMS" SG_ 2365575713 IgnOn 5000;
BA_ "SigType" SG_ 2365575713 IgnOn 4;
BA_ "CI_ParId" SG_ 2566892573 Blk1Full "IMH0061";
BA_ "CI_SigId" SG_ 2566892573 Blk1Full 2512;
BA_ "CI_SigName" SG_ 2566892573 Blk1Full "Block 1 full";
BA_ "SigType" SG_ 2566892573 Blk1Full 4;
BA_ "CI_ParId" SG_ 2566892573 Blk2Full "IMH0062";
BA_ "CI_SigId" SG_ 2566892573 Blk2Full 2513;
BA_ "CI_SigName" SG_ 2566892573 Blk2Full "Block 2 full";
BA_ "SigType" SG_ 2566892573 Blk2Full 4;
BA_ "CI_ParId" SG_ 2566892573 SevAnomalyInBlk1 "IMH0063";
BA_ "CI_SigId" SG_ 2566892573 SevAnomalyInBlk1 2514;
BA_ "CI_SigName" SG_ 2566892573 SevAnomalyInBlk1 "Severe anomaly in Block 1";
BA_ "SigType" SG_ 2566892573 SevAnomalyInBlk1 4;
BA_ "CI_ParId" SG_ 2566892573 SevAnomalyInBlk2 "IMH0064";
BA_ "CI_SigId" SG_ 2566892573 SevAnomalyInBlk2 2515;
BA_ "CI_SigName" SG_ 2566892573 SevAnomalyInBlk2 "Severe anomaly in Block 2";
BA_ "SigType" SG_ 2566892573 SevAnomalyInBlk2 4;
BA_ "CI_ParId" SG_ 2566892618 WarnRx "IMH0065";
BA_ "CI_SigId" SG_ 2566892618 WarnRx 2517;
BA_ "CI_SigName" SG_ 2566892618 WarnRx "Warning Received";
BA_ "SigType" SG_ 2566892618 WarnRx 4;
BA_ "CI_ParId" SG_ 2566885148 BuiltUpArea "V580";
BA_ "CI_SigId" SG_ 2566885148 BuiltUpArea 12994;
BA_ "CI_SigName" SG_ 2566885148 BuiltUpArea "Built Up Area";
BA_ "GenSigTimeoutTime_ADCU" SG_ 2566885148 BuiltUpArea 5000;
BA_ "GenSigTimeoutTime_SGW_" SG_ 2566885148 BuiltUpArea 5000;
BA_ "CI_ParId" SG_ 2566885148 FunctRoadClass "V581";
BA_ "CI_SigId" SG_ 2566885148 FunctRoadClass 12995;
BA_ "CI_SigName" SG_ 2566885148 FunctRoadClass "Functional Road Class";
BA_ "GenSigTimeoutTime_ADCU" SG_ 2566885148 FunctRoadClass 5000;
BA_ "GenSigTimeoutTime_SGW_" SG_ 2566885148 FunctRoadClass 5000;
BA_ "CI_ParId" SG_ 2566885148 SpeedLimType "V584";
BA_ "CI_SigId" SG_ 2566885148 SpeedLimType 12998;
BA_ "CI_SigName" SG_ 2566885148 SpeedLimType "Speed Limit Type";
BA_ "GenSigTimeoutTime_ADCU" SG_ 2566885148 SpeedLimType 5000;
BA_ "GenSigTimeoutTime_SGW_" SG_ 2566885148 SpeedLimType 5000;
BA_ "CI_ParId" SG_ 2566898670 Driv1Id_18FFC3EE "V004";
BA_ "CI_SigId" SG_ 2566898670 Driv1Id_18FFC3EE 746;
BA_ "CI_SigName" SG_ 2566898670 Driv1Id_18FFC3EE "Driver 1 Identification";
BA_ "GenSigSendType" SG_ 2566898670 Driv1Id_18FFC3EE 3;
BA_ "GenSigTimeoutTime_PCM" SG_ 2566898670 Driv1Id_18FFC3EE 300000;
BA_ "SigType" SG_ 2566898670 Driv1Id_18FFC3EE 3;
BA_ "CI_ParId" SG_ 2566898670 PrefLang "V005";
BA_ "CI_SigId" SG_ 2566898670 PrefLang 747;
BA_ "CI_SigName" SG_ 2566898670 PrefLang "Preferred Language";
BA_ "GenSigSendType" SG_ 2566898670 PrefLang 3;
BA_ "GenSigTimeoutTime_PCM" SG_ 2566898670 PrefLang 300000;
BA_ "SigType" SG_ 2566898670 PrefLang 3;
BA_ "CI_ParId" SG_ 2566898670 NextCalDateDay "V050";
BA_ "CI_SigId" SG_ 2566898670 NextCalDateDay 748;
BA_ "CI_SigName" SG_ 2566898670 NextCalDateDay "Next Calibration Date - Day";
BA_ "GenSigSendType" SG_ 2566898670 NextCalDateDay 3;
BA_ "GenSigTimeoutTime_PCM" SG_ 2566898670 NextCalDateDay 300000;
BA_ "SigType" SG_ 2566898670 NextCalDateDay 1;
BA_ "CI_ParId" SG_ 2566898670 NextCalDateMonth "V051";
BA_ "CI_SigId" SG_ 2566898670 NextCalDateMonth 749;
BA_ "CI_SigName" SG_ 2566898670 NextCalDateMonth "Next Calibration Date - Month";
BA_ "GenSigSendType" SG_ 2566898670 NextCalDateMonth 3;
BA_ "GenSigTimeoutTime_PCM" SG_ 2566898670 NextCalDateMonth 300000;
BA_ "SigType" SG_ 2566898670 NextCalDateMonth 1;
BA_ "CI_ParId" SG_ 2566898670 NextCalDateYr "V052";
BA_ "CI_SigId" SG_ 2566898670 NextCalDateYr 750;
BA_ "CI_SigName" SG_ 2566898670 NextCalDateYr "Next Calibration Date - Year";
BA_ "GenSigSendType" SG_ 2566898670 NextCalDateYr 3;
BA_ "GenSigTimeoutTime_PCM" SG_ 2566898670 NextCalDateYr 300000;
BA_ "SigType" SG_ 2566898670 NextCalDateYr 1;
BA_ "CI_ParId" SG_ 2566898670 WFact "V007";
BA_ "CI_SigId" SG_ 2566898670 WFact 751;
BA_ "CI_SigName" SG_ 2566898670 WFact "W Factor";
BA_ "GenSigSendType" SG_ 2566898670 WFact 3;
BA_ "GenSigTimeoutTime_PCM" SG_ 2566898670 WFact 300000;
BA_ "SigType" SG_ 2566898670 WFact 1;
BA_ "CI_ParId" SG_ 2566898926 Driv1ContDrivTime "V008";
BA_ "CI_SigId" SG_ 2566898926 Driv1ContDrivTime 753;
BA_ "CI_SigName" SG_ 2566898926 Driv1ContDrivTime "Driver1 Continuous Driving Time";
BA_ "GenSigTimeoutTime_PCM" SG_ 2566898926 Driv1ContDrivTime 50000;
BA_ "SigType" SG_ 2566898926 Driv1ContDrivTime 1;
BA_ "CI_ParId" SG_ 2566898926 Driv1CumulBreakTime "V009";
BA_ "CI_SigId" SG_ 2566898926 Driv1CumulBreakTime 754;
BA_ "CI_SigName" SG_ 2566898926 Driv1CumulBreakTime "Driver1 Cumulative Break Time";
BA_ "GenSigTimeoutTime_PCM" SG_ 2566898926 Driv1CumulBreakTime 50000;
BA_ "SigType" SG_ 2566898926 Driv1CumulBreakTime 1;
BA_ "CI_ParId" SG_ 2566898926 Driv1CurDurOfSelActv "V010";
BA_ "CI_SigId" SG_ 2566898926 Driv1CurDurOfSelActv 755;
BA_ "CI_SigName" SG_ 2566898926 Driv1CurDurOfSelActv "Driver1 Current Duration Of Selected Activity";
BA_ "GenSigTimeoutTime_PCM" SG_ 2566898926 Driv1CurDurOfSelActv 50000;
BA_ "SigType" SG_ 2566898926 Driv1CurDurOfSelActv 1;
BA_ "CI_ParId" SG_ 2566898926 Driv1CardDwlAlert "V011";
BA_ "CI_SigId" SG_ 2566898926 Driv1CardDwlAlert 756;
BA_ "CI_SigName" SG_ 2566898926 Driv1CardDwlAlert "Driver1 Card Download Alert";
BA_ "GenSigTimeoutTime_PCM" SG_ 2566898926 Driv1CardDwlAlert 50000;
BA_ "SigType" SG_ 2566898926 Driv1CardDwlAlert 4;
BA_ "CI_ParId" SG_ 2566898926 EndOfLifeDriv1CardAlert "V012";
BA_ "CI_SigId" SG_ 2566898926 EndOfLifeDriv1CardAlert 757;
BA_ "CI_SigName" SG_ 2566898926 EndOfLifeDriv1CardAlert "End Of Life Driver 1 Card Alert";
BA_ "GenSigTimeoutTime_PCM" SG_ 2566898926 EndOfLifeDriv1CardAlert 50000;
BA_ "SigType" SG_ 2566898926 EndOfLifeDriv1CardAlert 4;
BA_ "CI_ParId" SG_ 2566898926 PrintDrawSts "V013";
BA_ "CI_SigId" SG_ 2566898926 PrintDrawSts 758;
BA_ "CI_SigName" SG_ 2566898926 PrintDrawSts "Printer Drawer State";
BA_ "GenSigTimeoutTime_PCM" SG_ 2566898926 PrintDrawSts 50000;
BA_ "SigType" SG_ 2566898926 PrintDrawSts 4;
BA_ "CI_ParId" SG_ 2566899694 TwoWeeksTotDrivTime "V014";
BA_ "CI_SigId" SG_ 2566899694 TwoWeeksTotDrivTime 760;
BA_ "CI_SigName" SG_ 2566899694 TwoWeeksTotDrivTime "Two Weeks Total Driving Time";
BA_ "GenSigSendType" SG_ 2566899694 TwoWeeksTotDrivTime 3;
BA_ "GenSigTimeoutTime_PCM" SG_ 2566899694 TwoWeeksTotDrivTime 300000;
BA_ "SigType" SG_ 2566899694 TwoWeeksTotDrivTime 1;
BA_ "CI_ParId" SG_ 2566899694 WeekTotDrivTime "V015";
BA_ "CI_SigId" SG_ 2566899694 WeekTotDrivTime 761;
BA_ "CI_SigName" SG_ 2566899694 WeekTotDrivTime "Weekly Total Driving Time";
BA_ "GenSigSendType" SG_ 2566899694 WeekTotDrivTime 3;
BA_ "GenSigTimeoutTime_PCM" SG_ 2566899694 WeekTotDrivTime 300000;
BA_ "SigType" SG_ 2566899694 WeekTotDrivTime 1;
BA_ "CI_ParId" SG_ 2566899694 DayDrivTime "V016";
BA_ "CI_SigId" SG_ 2566899694 DayDrivTime 762;
BA_ "CI_SigName" SG_ 2566899694 DayDrivTime "Daily Driving Time";
BA_ "GenSigSendType" SG_ 2566899694 DayDrivTime 3;
BA_ "GenSigTimeoutTime_PCM" SG_ 2566899694 DayDrivTime 300000;
BA_ "CI_ParId" SG_ 2566899694 DayDrivTimeFlag "V017";
BA_ "CI_SigId" SG_ 2566899694 DayDrivTimeFlag 763;
BA_ "CI_SigName" SG_ 2566899694 DayDrivTimeFlag "Daily Driving Time Flag";
BA_ "GenSigSendType" SG_ 2566899694 DayDrivTimeFlag 3;
BA_ "GenSigTimeoutTime_PCM" SG_ 2566899694 DayDrivTimeFlag 300000;
BA_ "CI_ParId" SG_ 2566899694 DayDrivTimeShift1 "V018";
BA_ "CI_SigId" SG_ 2566899694 DayDrivTimeShift1 764;
BA_ "CI_SigName" SG_ 2566899694 DayDrivTimeShift1 "Daily Driving Time Shift 1";
BA_ "GenSigSendType" SG_ 2566899694 DayDrivTimeShift1 3;
BA_ "GenSigTimeoutTime_PCM" SG_ 2566899694 DayDrivTimeShift1 300000;
BA_ "CI_ParId" SG_ 2566899694 DayDrivTimeShift1Flag "V019";
BA_ "CI_SigId" SG_ 2566899694 DayDrivTimeShift1Flag 13502;
BA_ "CI_SigName" SG_ 2566899694 DayDrivTimeShift1Flag "Daily Driving Time Shift 1 Flag";
BA_ "GenSigSendType" SG_ 2566899694 DayDrivTimeShift1Flag 3;
BA_ "GenSigTimeoutTime_PCM" SG_ 2566899694 DayDrivTimeShift1Flag 300000;
BA_ "CI_ParId" SG_ 2566899694 DayDrivTimeShift2 "V020";
BA_ "CI_SigId" SG_ 2566899694 DayDrivTimeShift2 13503;
BA_ "CI_SigName" SG_ 2566899694 DayDrivTimeShift2 "Daily Driving Time Shift 2";
BA_ "GenSigSendType" SG_ 2566899694 DayDrivTimeShift2 3;
BA_ "GenSigTimeoutTime_PCM" SG_ 2566899694 DayDrivTimeShift2 300000;
BA_ "CI_ParId" SG_ 2566899694 DayDrivTimeShift2Flag "V021";
BA_ "CI_SigId" SG_ 2566899694 DayDrivTimeShift2Flag 13504;
BA_ "CI_SigName" SG_ 2566899694 DayDrivTimeShift2Flag "Daily Driving Time Shift 2 Flag";
BA_ "GenSigSendType" SG_ 2566899694 DayDrivTimeShift2Flag 3;
BA_ "GenSigTimeoutTime_PCM" SG_ 2566899694 DayDrivTimeShift2Flag 300000;
BA_ "CI_ParId" SG_ 2566899694 DayDrivTimeShift3 "V022";
BA_ "CI_SigId" SG_ 2566899694 DayDrivTimeShift3 13505;
BA_ "CI_SigName" SG_ 2566899694 DayDrivTimeShift3 "Daily Driving Time Shift 3";
BA_ "GenSigSendType" SG_ 2566899694 DayDrivTimeShift3 3;
BA_ "GenSigTimeoutTime_PCM" SG_ 2566899694 DayDrivTimeShift3 300000;
BA_ "CI_ParId" SG_ 2566899694 DayDrivTimeShift3Flag "V023";
BA_ "CI_SigId" SG_ 2566899694 DayDrivTimeShift3Flag 13506;
BA_ "CI_SigName" SG_ 2566899694 DayDrivTimeShift3Flag "Daily Driving Time Shift 3 Flag";
BA_ "GenSigSendType" SG_ 2566899694 DayDrivTimeShift3Flag 3;
BA_ "GenSigTimeoutTime_PCM" SG_ 2566899694 DayDrivTimeShift3Flag 300000;
BA_ "CI_ParId" SG_ 2566899694 DayDrivTimeShift4 "V024";
BA_ "CI_SigId" SG_ 2566899694 DayDrivTimeShift4 13507;
BA_ "CI_SigName" SG_ 2566899694 DayDrivTimeShift4 "Daily Driving Time Shift 4";
BA_ "GenSigSendType" SG_ 2566899694 DayDrivTimeShift4 3;
BA_ "GenSigTimeoutTime_PCM" SG_ 2566899694 DayDrivTimeShift4 300000;
BA_ "CI_ParId" SG_ 2566899694 DayDrivTimeShift4Flag "V025";
BA_ "CI_SigId" SG_ 2566899694 DayDrivTimeShift4Flag 13508;
BA_ "CI_SigName" SG_ 2566899694 DayDrivTimeShift4Flag "Daily Driving Time Shift 4 Flag";
BA_ "GenSigSendType" SG_ 2566899694 DayDrivTimeShift4Flag 3;
BA_ "GenSigTimeoutTime_PCM" SG_ 2566899694 DayDrivTimeShift4Flag 300000;
BA_ "CI_ParId" SG_ 2566899694 DayDrivTimeShift5 "V026";
BA_ "CI_SigId" SG_ 2566899694 DayDrivTimeShift5 13509;
BA_ "CI_SigName" SG_ 2566899694 DayDrivTimeShift5 "Daily Driving Time Shift 5";
BA_ "GenSigSendType" SG_ 2566899694 DayDrivTimeShift5 3;
BA_ "GenSigTimeoutTime_PCM" SG_ 2566899694 DayDrivTimeShift5 300000;
BA_ "CI_ParId" SG_ 2566899694 DayDrivTimeShift5Flag "V027";
BA_ "CI_SigId" SG_ 2566899694 DayDrivTimeShift5Flag 13510;
BA_ "CI_SigName" SG_ 2566899694 DayDrivTimeShift5Flag "Daily Driving Time Shift 5 Flag";
BA_ "GenSigSendType" SG_ 2566899694 DayDrivTimeShift5Flag 3;
BA_ "GenSigTimeoutTime_PCM" SG_ 2566899694 DayDrivTimeShift5Flag 300000;
BA_ "CI_ParId" SG_ 2566899694 DayDrivTimeShift6 "V028";
BA_ "CI_SigId" SG_ 2566899694 DayDrivTimeShift6 13511;
BA_ "CI_SigName" SG_ 2566899694 DayDrivTimeShift6 "Daily Driving Time Shift 6";
BA_ "GenSigSendType" SG_ 2566899694 DayDrivTimeShift6 3;
BA_ "GenSigTimeoutTime_PCM" SG_ 2566899694 DayDrivTimeShift6 300000;
BA_ "CI_ParId" SG_ 2566899694 DayDrivTimeShift6Flag "V029";
BA_ "CI_SigId" SG_ 2566899694 DayDrivTimeShift6Flag 13512;
BA_ "CI_SigName" SG_ 2566899694 DayDrivTimeShift6Flag "Daily Driving Time Shift 6 Flag";
BA_ "GenSigSendType" SG_ 2566899694 DayDrivTimeShift6Flag 3;
BA_ "GenSigTimeoutTime_PCM" SG_ 2566899694 DayDrivTimeShift6Flag 300000;
BA_ "CI_ParId" SG_ 2566899694 DayRestPer1 "V030";
BA_ "CI_SigId" SG_ 2566899694 DayRestPer1 13513;
BA_ "CI_SigName" SG_ 2566899694 DayRestPer1 "Daily Resting Period 1";
BA_ "GenSigSendType" SG_ 2566899694 DayRestPer1 3;
BA_ "GenSigTimeoutTime_PCM" SG_ 2566899694 DayRestPer1 300000;
BA_ "CI_ParId" SG_ 2566899694 DayRestPer1Flag "V031";
BA_ "CI_SigId" SG_ 2566899694 DayRestPer1Flag 13514;
BA_ "CI_SigName" SG_ 2566899694 DayRestPer1Flag "Daily Resting Period 1 Flag";
BA_ "GenSigSendType" SG_ 2566899694 DayRestPer1Flag 3;
BA_ "GenSigTimeoutTime_PCM" SG_ 2566899694 DayRestPer1Flag 300000;
BA_ "CI_ParId" SG_ 2566899694 DayRestPer2 "V032";
BA_ "CI_SigId" SG_ 2566899694 DayRestPer2 13515;
BA_ "CI_SigName" SG_ 2566899694 DayRestPer2 "Daily Resting Period 2";
BA_ "GenSigSendType" SG_ 2566899694 DayRestPer2 3;
BA_ "GenSigTimeoutTime_PCM" SG_ 2566899694 DayRestPer2 300000;
BA_ "CI_ParId" SG_ 2566899694 DayRestPer2Flag "V033";
BA_ "CI_SigId" SG_ 2566899694 DayRestPer2Flag 13516;
BA_ "CI_SigName" SG_ 2566899694 DayRestPer2Flag "Daily Resting Period 2 Flag";
BA_ "GenSigSendType" SG_ 2566899694 DayRestPer2Flag 3;
BA_ "GenSigTimeoutTime_PCM" SG_ 2566899694 DayRestPer2Flag 300000;
BA_ "CI_ParId" SG_ 2566899694 DayRestPer3 "V034";
BA_ "CI_SigId" SG_ 2566899694 DayRestPer3 13517;
BA_ "CI_SigName" SG_ 2566899694 DayRestPer3 "Daily Resting Period 3";
BA_ "GenSigSendType" SG_ 2566899694 DayRestPer3 3;
BA_ "GenSigTimeoutTime_PCM" SG_ 2566899694 DayRestPer3 300000;
BA_ "CI_ParId" SG_ 2566899694 DayRestPer3Flag "V035";
BA_ "CI_SigId" SG_ 2566899694 DayRestPer3Flag 13518;
BA_ "CI_SigName" SG_ 2566899694 DayRestPer3Flag "Daily Resting Period 3 Flag";
BA_ "GenSigSendType" SG_ 2566899694 DayRestPer3Flag 3;
BA_ "GenSigTimeoutTime_PCM" SG_ 2566899694 DayRestPer3Flag 300000;
BA_ "CI_ParId" SG_ 2566899694 DayRestPer4 "V036";
BA_ "CI_SigId" SG_ 2566899694 DayRestPer4 13519;
BA_ "CI_SigName" SG_ 2566899694 DayRestPer4 "Daily Resting Period 4";
BA_ "GenSigSendType" SG_ 2566899694 DayRestPer4 3;
BA_ "GenSigTimeoutTime_PCM" SG_ 2566899694 DayRestPer4 300000;
BA_ "CI_ParId" SG_ 2566899694 DayRestPer4Flag "V037";
BA_ "CI_SigId" SG_ 2566899694 DayRestPer4Flag 13520;
BA_ "CI_SigName" SG_ 2566899694 DayRestPer4Flag "Daily Resting Period 4 Flag";
BA_ "GenSigSendType" SG_ 2566899694 DayRestPer4Flag 3;
BA_ "GenSigTimeoutTime_PCM" SG_ 2566899694 DayRestPer4Flag 300000;
BA_ "CI_ParId" SG_ 2566899694 DayRestPer5 "V038";
BA_ "CI_SigId" SG_ 2566899694 DayRestPer5 13521;
BA_ "CI_SigName" SG_ 2566899694 DayRestPer5 "Daily Resting Period 5";
BA_ "GenSigSendType" SG_ 2566899694 DayRestPer5 3;
BA_ "GenSigTimeoutTime_PCM" SG_ 2566899694 DayRestPer5 300000;
BA_ "CI_ParId" SG_ 2566899694 DayRestPer5Flag "V039";
BA_ "CI_SigId" SG_ 2566899694 DayRestPer5Flag 13522;
BA_ "CI_SigName" SG_ 2566899694 DayRestPer5Flag "Daily Resting Period 5 Flag";
BA_ "GenSigSendType" SG_ 2566899694 DayRestPer5Flag 3;
BA_ "GenSigTimeoutTime_PCM" SG_ 2566899694 DayRestPer5Flag 300000;
BA_ "CI_ParId" SG_ 2566899694 DayRestPer6 "V040";
BA_ "CI_SigId" SG_ 2566899694 DayRestPer6 13523;
BA_ "CI_SigName" SG_ 2566899694 DayRestPer6 "Daily Resting Period 6";
BA_ "GenSigSendType" SG_ 2566899694 DayRestPer6 3;
BA_ "GenSigTimeoutTime_PCM" SG_ 2566899694 DayRestPer6 300000;
BA_ "CI_ParId" SG_ 2566899694 DayRestPer6Flag "V041";
BA_ "CI_SigId" SG_ 2566899694 DayRestPer6Flag 13524;
BA_ "CI_SigName" SG_ 2566899694 DayRestPer6Flag "Daily Resting Period 6 Flag";
BA_ "GenSigSendType" SG_ 2566899694 DayRestPer6Flag 3;
BA_ "GenSigTimeoutTime_PCM" SG_ 2566899694 DayRestPer6Flag 300000;
BA_ "CI_ParId" SG_ 2566899694 DayRestPer7 "V042";
BA_ "CI_SigId" SG_ 2566899694 DayRestPer7 13525;
BA_ "CI_SigName" SG_ 2566899694 DayRestPer7 "Daily Resting Period 7";
BA_ "GenSigSendType" SG_ 2566899694 DayRestPer7 3;
BA_ "GenSigTimeoutTime_PCM" SG_ 2566899694 DayRestPer7 300000;
BA_ "CI_ParId" SG_ 2566899694 DayRestPer7Flag "V043";
BA_ "CI_SigId" SG_ 2566899694 DayRestPer7Flag 13526;
BA_ "CI_SigName" SG_ 2566899694 DayRestPer7Flag "Daily Resting Period 7 Flag";
BA_ "GenSigSendType" SG_ 2566899694 DayRestPer7Flag 3;
BA_ "GenSigTimeoutTime_PCM" SG_ 2566899694 DayRestPer7Flag 300000;
BA_ "CI_ParId" SG_ 2566899694 DayOdo "V044";
BA_ "CI_SigId" SG_ 2566899694 DayOdo 765;
BA_ "CI_SigName" SG_ 2566899694 DayOdo "Daily Odometer";
BA_ "GenSigSendType" SG_ 2566899694 DayOdo 3;
BA_ "GenSigTimeoutTime_PCM" SG_ 2566899694 DayOdo 300000;
BA_ "SigType" SG_ 2566899694 DayOdo 1;
BA_ "CI_ParId" SG_ 2566899694 WeekTotOdo "V045";
BA_ "CI_SigId" SG_ 2566899694 WeekTotOdo 766;
BA_ "CI_SigName" SG_ 2566899694 WeekTotOdo "Weekly Total Odometer";
BA_ "GenSigSendType" SG_ 2566899694 WeekTotOdo 3;
BA_ "GenSigTimeoutTime_PCM" SG_ 2566899694 WeekTotOdo 300000;
BA_ "SigType" SG_ 2566899694 WeekTotOdo 1;
BA_ "CI_ParId" SG_ 2566899694 TwoWeeksTotOdo "V046";
BA_ "CI_SigId" SG_ 2566899694 TwoWeeksTotOdo 767;
BA_ "CI_SigName" SG_ 2566899694 TwoWeeksTotOdo "Two Weeks Total Odometer";
BA_ "GenSigSendType" SG_ 2566899694 TwoWeeksTotOdo 3;
BA_ "GenSigTimeoutTime_PCM" SG_ 2566899694 TwoWeeksTotOdo 300000;
BA_ "SigType" SG_ 2566899694 TwoWeeksTotOdo 1;
BA_ "CI_ParId" SG_ 2566899694 DrivCnt "V047";
BA_ "CI_SigId" SG_ 2566899694 DrivCnt 768;
BA_ "CI_SigName" SG_ 2566899694 DrivCnt "Driving Counter";
BA_ "GenSigSendType" SG_ 2566899694 DrivCnt 3;
BA_ "GenSigTimeoutTime_PCM" SG_ 2566899694 DrivCnt 300000;
BA_ "SigType" SG_ 2566899694 DrivCnt 1;
BA_ "CI_ParId" SG_ 2566899694 WorkCnt "V048";
BA_ "CI_SigId" SG_ 2566899694 WorkCnt 769;
BA_ "CI_SigName" SG_ 2566899694 WorkCnt "Work Counter";
BA_ "GenSigSendType" SG_ 2566899694 WorkCnt 3;
BA_ "GenSigTimeoutTime_PCM" SG_ 2566899694 WorkCnt 300000;
BA_ "SigType" SG_ 2566899694 WorkCnt 1;
BA_ "CI_ParId" SG_ 2566899694 AvCnt "V049";
BA_ "CI_SigId" SG_ 2566899694 AvCnt 770;
BA_ "CI_SigName" SG_ 2566899694 AvCnt "Available Counter";
BA_ "GenSigSendType" SG_ 2566899694 AvCnt 3;
BA_ "GenSigTimeoutTime_PCM" SG_ 2566899694 AvCnt 300000;
BA_ "SigType" SG_ 2566899694 AvCnt 1;
BA_ "CI_ParId" SG_ 2650771712 MajorVer "F290";
BA_ "CI_SigId" SG_ 2650771712 MajorVer 17421;
BA_ "CI_SigName" SG_ 2650771712 MajorVer "Major Version";
BA_ "GenSigTimeoutTime_PCM" SG_ 2650771712 MajorVer 25000;
BA_ "CI_ParId" SG_ 2650771712 MinorVer "F291";
BA_ "CI_SigId" SG_ 2650771712 MinorVer 17422;
BA_ "CI_SigName" SG_ 2650771712 MinorVer "Minor Version";
BA_ "GenSigTimeoutTime_PCM" SG_ 2650771712 MinorVer 25000;
BA_ "CI_ParId" SG_ 2650771712 DatasetCustEOL01 "F292";
BA_ "CI_SigId" SG_ 2650771712 DatasetCustEOL01 17423;
BA_ "CI_SigName" SG_ 2650771712 DatasetCustEOL01 "Dataset Customization EOL 01";
BA_ "GenSigTimeoutTime_PCM" SG_ 2650771712 DatasetCustEOL01 25000;
BA_ "CI_ParId" SG_ 2650771712 DatasetCustEOL02 "F293";
BA_ "CI_SigId" SG_ 2650771712 DatasetCustEOL02 17424;
BA_ "CI_SigName" SG_ 2650771712 DatasetCustEOL02 "Dataset Customization EOL 02";
BA_ "GenSigTimeoutTime_PCM" SG_ 2650771712 DatasetCustEOL02 25000;
BA_ "CI_ParId" SG_ 2650771712 DatasetCustEOL03 "F294";
BA_ "CI_SigId" SG_ 2650771712 DatasetCustEOL03 17425;
BA_ "CI_SigName" SG_ 2650771712 DatasetCustEOL03 "Dataset Customization EOL 03";
BA_ "GenSigTimeoutTime_PCM" SG_ 2650771712 DatasetCustEOL03 25000;
BA_ "CI_ParId" SG_ 2650771712 DatasetCustEOL04 "F295";
BA_ "CI_SigId" SG_ 2650771712 DatasetCustEOL04 17426;
BA_ "CI_SigName" SG_ 2650771712 DatasetCustEOL04 "Dataset Customization EOL 04";
BA_ "GenSigTimeoutTime_PCM" SG_ 2650771712 DatasetCustEOL04 25000;
BA_ "CI_ParId" SG_ 2650771712 DatasetCustEOL05 "F296";
BA_ "CI_SigId" SG_ 2650771712 DatasetCustEOL05 17427;
BA_ "CI_SigName" SG_ 2650771712 DatasetCustEOL05 "Dataset Customization EOL 05";
BA_ "GenSigTimeoutTime_PCM" SG_ 2650771712 DatasetCustEOL05 25000;
BA_ "CI_ParId" SG_ 2650771712 DatasetCustEOL06 "F297";
BA_ "CI_SigId" SG_ 2650771712 DatasetCustEOL06 17428;
BA_ "CI_SigName" SG_ 2650771712 DatasetCustEOL06 "Dataset Customization EOL 06";
BA_ "GenSigTimeoutTime_PCM" SG_ 2650771712 DatasetCustEOL06 25000;
BA_ "CI_ParId" SG_ 2650771968 DatasetCustEOL07 "F298";
BA_ "CI_SigId" SG_ 2650771968 DatasetCustEOL07 17430;
BA_ "CI_SigName" SG_ 2650771968 DatasetCustEOL07 "Dataset Customization EOL 07";
BA_ "GenSigTimeoutTime_PCM" SG_ 2650771968 DatasetCustEOL07 25000;
BA_ "CI_ParId" SG_ 2650771968 DatasetCustEOL08 "F299";
BA_ "CI_SigId" SG_ 2650771968 DatasetCustEOL08 17431;
BA_ "CI_SigName" SG_ 2650771968 DatasetCustEOL08 "Dataset Customization EOL 08";
BA_ "GenSigTimeoutTime_PCM" SG_ 2650771968 DatasetCustEOL08 25000;
BA_ "CI_ParId" SG_ 2650771968 DatasetCustEOL09 "F300";
BA_ "CI_SigId" SG_ 2650771968 DatasetCustEOL09 17432;
BA_ "CI_SigName" SG_ 2650771968 DatasetCustEOL09 "Dataset Customization EOL 09";
BA_ "GenSigTimeoutTime_PCM" SG_ 2650771968 DatasetCustEOL09 25000;
BA_ "CI_ParId" SG_ 2650771968 DatasetCustEOL10 "F301";
BA_ "CI_SigId" SG_ 2650771968 DatasetCustEOL10 17433;
BA_ "CI_SigName" SG_ 2650771968 DatasetCustEOL10 "Dataset Customization EOL 10";
BA_ "GenSigTimeoutTime_PCM" SG_ 2650771968 DatasetCustEOL10 25000;
BA_ "CI_ParId" SG_ 2650771968 DatasetCustEOL11 "F302";
BA_ "CI_SigId" SG_ 2650771968 DatasetCustEOL11 17434;
BA_ "CI_SigName" SG_ 2650771968 DatasetCustEOL11 "Dataset Customization EOL 11";
BA_ "GenSigTimeoutTime_PCM" SG_ 2650771968 DatasetCustEOL11 25000;
BA_ "CI_ParId" SG_ 2650771968 DatasetCustEOL12 "F303";
BA_ "CI_SigId" SG_ 2650771968 DatasetCustEOL12 17435;
BA_ "CI_SigName" SG_ 2650771968 DatasetCustEOL12 "Dataset Customization EOL 12";
BA_ "GenSigTimeoutTime_PCM" SG_ 2650771968 DatasetCustEOL12 25000;
BA_ "CI_ParId" SG_ 2650771968 DatasetCustEOL13 "F304";
BA_ "CI_SigId" SG_ 2650771968 DatasetCustEOL13 17436;
BA_ "CI_SigName" SG_ 2650771968 DatasetCustEOL13 "Dataset Customization EOL 13";
BA_ "GenSigTimeoutTime_PCM" SG_ 2650771968 DatasetCustEOL13 25000;
BA_ "CI_ParId" SG_ 2650771968 DatasetCustEOL14 "F305";
BA_ "CI_SigId" SG_ 2650771968 DatasetCustEOL14 17437;
BA_ "CI_SigName" SG_ 2650771968 DatasetCustEOL14 "Dataset Customization EOL 14";
BA_ "GenSigTimeoutTime_PCM" SG_ 2650771968 DatasetCustEOL14 25000;
VAL_ 2364540032 ActEngPcTrq_0CF00480 254 "Error" 255 "Not_available" ;
VAL_ 2364540032 EngSpeed_0CF00480 65024 "Error" 65535 "Not_Available" ;
VAL_ 2566767127 FuelType 0 "Not Available, NONE" 1 "GAS" 2 "METH" 3 "ETH" 4 "DSL" 5 "LPG" 6 "CNG" 7 "PROP" 8 "ELEC" 9 "BI_GAS" 10 "BI_METH" 11 "BI_ETH" 12 "BI_LPG" 13 "BI_CNG" 14 "BI_PROP" 15 "BI_ELEC" 16 "BI_MIX" 17 "HYB_GAS" 18 "HYB_ETH" 19 "HYB_DSL" 20 "HYB_ELEC" 21 "HYB_MIX" 22 "HYB_REG" 23 "NG" 24 "BI_NG" 25 "Bi-fuel using diesel" 26 "Natural Gas (Compr. or Liquid)" 27 "Dual Fuel, Diesel and CNG" 28 "Dual Fuel, Diesel and LNG" 29 "Fuel Cell Utilizing Hydrogen" 30 "Hydrogen Internal Combustion" 31 "Kerosene" 32 "Heavy Fuel Oil" 33 "Reserved" 253 "Reserved" 254 "Error" 255 "Not Available" ;
VAL_ 2364539648 AccPed1LowIdleSw 0 "Not in low idle" 1 "Low idle" 2 "Error" 3 "Not Available" ;
VAL_ 2364539648 AccPedKdSw 0 "Kickdown passive" 1 "Kickdown active" 2 "Error" 3 "Not Available" ;
VAL_ 2364539648 AccPedPos1 254 "Error" 255 "Not_available" ;
VAL_ 2364539648 EngPcLoadAtCurSpeed 254 "Error" 255 "Not_available" ;
VAL_ 2364539776 AccPedPos1_0CF00380 254 "Error" 255 "Not_available" ;
VAL_ 2364539776 EngPcLoadAtCurSpeed_0CF00380 254 "Error" 255 "Not_available" ;
VAL_ 2364539776 ActMaxAvEngPcTrq 254 "Error" 255 "Not_available" ;
VAL_ 2566898290 EngStopSw 0 "Off" 1 "On" ;
VAL_ 2565865488 RetTrqMode 0 "Low idle / No request" 1 "APP / Operator selection" 2 "Cruise control" 3 "PTO governor" 4 "Road speed governor" 5 "ASR control" 6 "Transmission control" 7 "ABS control" 8 "Torque limiting" 9 "High speed governor" 10 "Braking system" 11 "Remote accelerator" 12 "Service procedure" 13 "not defined" 14 "Other" 15 "Not Available" ;
VAL_ 2565865488 ActRetPcTrq 254 "Error" 255 "Not_available" ;
VAL_ 2565865488 RetSelNonEng 254 "Error" 255 "Not_available" ;
VAL_ 2565865487 ActRetPcTrq_18F0000F 254 "Error" 255 "Not_available" ;
VAL_ 2364539395 TransmDrvlEngd 0 "Driveline disengaged" 1 "Driveline engaged" 2 "Error" 3 "Not Available" ;
VAL_ 2364539395 TransmOutSpeed 65534 "Error" 65535 "Not_available" ;
VAL_ 2364539395 TransmInSpeed 65534 "Error" 65535 "Not_available" ;
VAL_ 2565866755 TransmSelGear 251 "Park" 254 "Error" 255 "Not Available" ;
VAL_ 2565866755 TransmCurGear 124 "Reverse" 125 "Neutral" 126 "1st Gear" 127 "2nd Gear" 128 "3rd Gear" 129 "4th Gear" 130 "5th Gear" 131 "6th Gear" 132 "7th Gear" 133 "8th Gear" 251 "Park" 254 "Error" 255 "Not Available" ;
VAL_ 2364541955 TransmTrqConvRatio 1000 "torque_converte_Locked" 64256 "Engine_Brake_Mode" 65024 "Error" 65535 "Not_available" ;
VAL_ 2431649694 LaneDepImmRh 0 "Not imminent" 1 "Imminent" 2 "Reserved" 3 "Not Used" ;
VAL_ 2431649694 LaneDepImmLh 0 "Not imminent" 1 "Imminent" 2 "Reserved" 3 "Not used" ;
VAL_ 2566806430 LaneDepIndEnaSts 0 "Disabled" 1 "Enabled" 2 "Reserved" 3 "Not Used" ;
VAL_ 2566806430 DrivAlertWarnSysSts 0 ">Installed but disabled" 1 "Initializing" 2 "Temporarily not available" 3 "Available" 4 "Monitoring driver behavior" 5 "Reserved" 6 "Reserved" 7 "Not Available / Not Installed" ;
VAL_ 2566806430 LdwSysSts 0 "Not ready" 1 "Temporarily not available" 2 "Deactivated by driver" 3 "Ready (no warnings active)" 4 "Suppressed by operator behavior" 5 "Warning lane departure" 6 "Reserved" 7 "Reserved" 8 "Reserved" 9 "Reserved" 10 "Reserved" 11 "Reserved" 12 "Reserved" 13 "Reserved" 14 "Error" 15 "Not Available" ;
VAL_ 2566837793 HybSysPwrElnCoolLevSw 0 "Not sufficient" 1 "Sufficient" 2 "Error" 3 "Not Available" ;
VAL_ 2566701658 PropSysActv 0 "Not ready to move" 1 "Ready to move or moving" 2 "Reserved" 3 "Not Available" ;
VAL_ 2566701658 HybSysMotOverspeedInd 0 "Off" 1 "On continously" 2 "Flashing" 3 "Not Available" ;
VAL_ 2566701658 HybSysRegenBrkInd 0 "Inactive" 1 "Active" 2 "Disabled or faulted" 3 "Not Available" ;
VAL_ 2566701658 HybPropModeSts 0 "No mode requested" 1 "Sustaining" 2 "Increasing" 3 "Depleting" 4 "Offline" 5 "Only" 6 "Reserved" 7 "Reserved" 8 "Reserved" 9 "Reserved" 10 "Reserved" 11 "Reserved" 12 "Reserved" 13 "Reserved" 14 "Error" 15 "Not Available" ;
VAL_ 2566701658 ExtEnergySrcConnSts 0 "No Conn." 1 "Conn.1, Error (Verific. failed)" 2 "Conn.1, Verification in Process" 3 "Conn.1, Energy Source and Drain" 4 "Conn.1, Energy Source" 5 "Conn.1, Energy Drain" 6 "Conn.2, Error (Verific. failed)" 7 "Conn.2, Verification in Process" 8 "Conn.2, Energy Source and Drain" 9 "Conn.2, Energy Source" 10 "Conn.2, Energy Drain" 11 "Reserved" 12 "Reserved" 13 "Reserved" 14 "Error" 15 "Not Available" ;
VAL_ 2566698842 HybBatRemChg 0 "No charge" 40000 "Full charge" ;
VAL_ 2566698842 HybSysEassRemPc 0 "No operation available" 250 "Max operation available" ;
VAL_ 2566850819 CoolSts_18FF0903 0 "TemperatureInRange" 1 "OverTemperature" 2 "Error" 3 "SNA" ;
VAL_ 2566850819 CruWarnLamp 0 "Lamp_OFF" 1 "Lamp_ON" 2 "Error" 3 "SNA" ;
VAL_ 2566850819 CruStopLamp 0 "Lamp_OFF" 1 "Lamp_ON" 2 "Error" 3 "SNA" ;
VAL_ 2566850819 CruSts 0 "Idle" 1 "Initialization" 2 "ReadyForStart-up" 3 "Start-upInProgress" 4 "Operation" 5 "LimitedOperation" 6 "ShutDownInProgress" 7 "AfterCooling" 8 "Reserved" 9 "Reserved" 10 "Reserved" 11 "Reserved" 12 "Reserved" 13 "LimpHome" 14 "Error" 15 "NotAvailable" ;
VAL_ 2566850819 CoolLev 0 "Coolant level in range" 1 "Coolant level to low" 2 "Coolant level to high" 3 "Reserved" 4 "Reserved" 5 "Reserved" 6 "Error" 7 "Not available" ;
VAL_ 2566850819 StopstartSts 0 "Idle" 1 "EngStopSupport" 2 "EngStopped" 3 "Cranking" 4 "Reserved" 5 "Reserved" 6 "Reserved" 7 "Reserved" 8 "Reserved" 9 "Reserved" 10 "Reserved" 11 "Reserved" 12 "Reserved" 13 "Reserved" 14 "Failure" 15 "SNA" ;
VAL_ 2566850819 ReasEngStartFail 0 "NoFailure" 1 "E_MashineFailure" 2 "EnergyStorageFailure" 3 "CombustionEngFailure" 4 "Reserved" 5 "Reserved" 6 "Reserved" 7 "Reserved" 8 "Reserved" 9 "Reserved" 10 "Reserved" 11 "Reserved" 12 "Reserved" 13 "Reserved" 14 "Error" 15 "SNA" ;
VAL_ 2566850819 EmotSts 0 "Out of operation" 1 "Operation" 2 "Failure" 3 "Not available" ;
VAL_ 2566850819 EssSts 0 "Out of operation" 1 "Operation" 2 "Failure" 3 "Not available" ;
VAL_ 2566850819 DcdcSts 0 "Out of operation" 1 "Operation" 2 "Failure" 3 "Not available" ;
VAL_ 2566851331 Isbalancingactive 0 "Balancing not active" 1 "Balancing active" 2 "Error" 3 "Not Available" ;
VAL_ 2566890368 CurSensSysSts 0 "NoError" 1 "AmberLamp" 2 "RedStopLamp" ;
VAL_ 2566844928 EngInstFuelEcon 64256 "Infinite" ;
VAL_ 2566844928 EngAvgFuelEcon 0 "vehicle_stop_at_idle" 251 "Engine off" ;
VAL_ 2566776097 AppliedVsl 251 "Speed limit not selected" ;
VAL_ 2365443105 TurnSigSw 0 "No Turn being signaled" 1 "Left Turn to be Flashing" 2 "Right turn to be Flashing" 14 "Error, left + right sel. simult." 15 "Not Available (do not change)" ;
VAL_ 2566769953 FrontOpWiperSw 0 "Off" 1 "Low" 2 "Medium" 3 "High" 4 "Delayed 1" 5 "Delayed 2" 6 "Mist" 14 "Error" 15 "Not Available / Do not change" ;
VAL_ 2566769953 FrontOpWasherSw 0 "Off" 1 "Low" 2 "Medium" 3 "High" 4 "Reserved" 5 "Reserved" 6 "Reserved" 7 "Not Available (do not change)" ;
VAL_ 2566908574 DrowsDrivLev 0 "Not Used" 1 "Extremely Alert" 2 "Alert" 3 "Neither Sleepy nor Alert" 4 "Drowsy" 5 "Extemely Drowsy" 6 "Reserved" 7 "Reserved" ;
VAL_ 2566908574 DdawRunMode 0 "Feature OFF" 1 "Standby" 2 "Driver Behaviour Learning" 3 "Driver Behaviour Monitoring" 4 "Reserved" 5 "Warning active" 6 "Error" 7 "Not Available" ;
VAL_ 2566907159 DrivDrowsWarnEnaSet 0 "Disable" 1 "Enable" 2 "Error" 3 "Not Available" ;
VAL_ 2566907159 LeftSpeakFail 0 "Inactive" 1 "Active" 2 "Reserved" 3 "Take no action" ;
VAL_ 2566907159 RightSpeakFail 0 "Inactive" 1 "Active" 2 "Reserved" 3 "Take no action" ;
VAL_ 2566907159 BuzFail 0 "Inactive" 1 "Active" 2 "Reserved" 3 "Take no action" ;
VAL_ 2566907159 LeftLedbarFail 0 "Inactive" 1 "Active" 2 "Reserved" 3 "Take no action" ;
VAL_ 2566907159 RightLedbarFail 0 "Inactive" 1 "Active" 2 "Reserved" 3 "Take no action" ;
VAL_ 2566907159 PlcaFuncEn 0 "Off" 1 "On" 2 "Error" 3 "Not Available" ;
VAL_ 2566907159 PlcaWarnEn 0 "Disabled" 1 "Enabled" 2 "Error" 3 "Not Available" ;
VAL_ 2566907159 BsisFuncEn 0 "Off" 1 "On" 2 "Error" 3 "Not Available" ;
VAL_ 2566907159 LeftVibratorFail 0 "Inactive" 1 "Active" 2 "Reserved" 3 "Take no action" ;
VAL_ 2566907159 RightVibratorFail 0 "Inactive" 1 "Active" 2 "Reserved" 3 "Take no action" ;
VAL_ 2566907159 LdwsCsfPreSel 0 "LDWS" 1 "LDWS+CSF" 2 "Reserved" 3 "Not Available" ;
VAL_ 2566907159 MsgCnt 8 "Reserved" 9 "Reserved" 10 "Reserved" 11 "Reserved" 12 "Reserved" 13 "Reserved" 14 "Reserved" 15 "Not Available, request honored" ;
VAL_ 2566907159 MsgCks 15 "Not Available, request honored" ;
VAL_ 2566894871 IntlSpeedAssantActv 0 "normal op SLI enabled" 1 "normal op SLI Opt ena Snd ena" 2 "normal op SLI Opt only ena" 3 "Reserved" 4 "Reserved" 5 "Reserved" 6 "Error" 7 "Not Available" ;
VAL_ 2566894871 CntryCode 0 "Unknown" ;
VAL_ 2566895006 MaxVslWarn 0 "Disabled" 1 "Optical" 2 "Optical and Acoustic" 6 "Error" 7 "Not Available" ;
VAL_ 2566895006 IntlSpeedAssantActv_18FFB59E 0 "normal op SLI enabled" 1 "normal op SLI Opt ena Snd ena" 2 "normal op SLI Opt only ena" 3 "Reserved" 4 "Reserved" 5 "Reserved" 6 "Error" 7 "Not Available" ;
VAL_ 2566895006 IntlSpeedAssantSts 0 "SLI enabled" 1 "SLI ena SLW Vis ena Snd ena" 2 "SLI ena SLW Vis only ena" 3 "OutOfWorking boundaries SLI ena" 4 "Reserved" 5 "Initiation status" 6 "Error status" 7 "Not Available" ;
VAL_ 2566895006 IsaDbgSts 0 "NRTA" 1 "ERROR" 2 "RTA_SLWF_FULL_STANDBY" 3 "RTA_SLWF_FULL_WARN_ACTIVE" 4 "RTA_SLWF_PARTIAL_STANDBY" 5 "RTA_SLWF_PARTIAL_WARN_ACTIVE" 6 "DISABLED_BY_DRIVER_SLIF" 7 "DISABLED_BY_SYSTEM_SLIF" 8 "INIT" 15 "Not Available" ;
VAL_ 2566895006 CntryCodeCfg 0 "Manual" 1 "Automatic" 2 "Error" 3 "Not available" ;
VAL_ 2566895006 CntryCode_18FFB59E 0 "Unknown" ;
VAL_ 2566895006 MaxVslUnitless 29 "None" 30 "Sign Not Recognized" 31 "Signal Not Available" ;
VAL_ 2566895006 SpeedLimConf 0 "Not Confidence" 1 "Confidence" 2 "Error" 3 "Not Available" ;
VAL_ 2566895006 IsaSpeedOverridden 0 "Not overspeeding" 1 "Overspeeding" 2 "Error" 3 "Not Available" ;
VAL_ 2365575713 IgnOn 0 "Off" 1 "On" 2 "Reserved" 3 "No Action" ;
VAL_ 2566892573 Blk1Full 0 "No" 1 "Yes" 2 "Error" 3 "Not Available" ;
VAL_ 2566892573 Blk2Full 0 "No" 1 "Yes" 2 "Error" 3 "Not Available" ;
VAL_ 2566892573 SevAnomalyInBlk1 0 "No" 1 "Yes" 2 "Error" 3 "Not Available" ;
VAL_ 2566892573 SevAnomalyInBlk2 0 "No" 1 "Yes" 2 "Error" 3 "Not Available" ;
VAL_ 2566892618 WarnRx 0 "No" 1 "Yes" 2 "Error" 3 "Not Available" ;
VAL_ 2566885148 BuiltUpArea 0 "false" 1 "true" ;
VAL_ 2566885148 FunctRoadClass 0 "Unkown" 1 "FC_1" 2 "FC_2" 3 "FC_3" 4 "FC_4" 5 "FC_5" 6 "Undefined" 7 "Not available" ;
VAL_ 2566885148 SpeedLimType 0 "DERIVED/UNAVAILABLE" 1 "POSTED" ;
VAL_ 2566898670 NextCalDateDay 0 "Not used" ;
VAL_ 2566898670 NextCalDateMonth 0 "Not used" ;
VAL_ 2566898670 WFact 0 "Not used" ;
VAL_ 2566898926 Driv1CardDwlAlert 0 "No Alert" 1 "Alert Active" 2 "Error" 3 "Not Available" ;
VAL_ 2566898926 EndOfLifeDriv1CardAlert 0 "No Alert" 1 "Alert Active" 2 "Error" 3 "Not Available" ;
VAL_ 2566898926 PrintDrawSts 0 "Open" 1 "Closed" 2 "Error" 3 "Not Available" ;
VAL_ 2566899694 DayDrivTime 32766 "Error" 32767 "Not Available" ;
VAL_ 2566899694 DayDrivTimeFlag 0 "No resting period" 1 "At least one resting period" ;
VAL_ 2566899694 DayDrivTimeShift1 32766 "Error" 32767 "Not Available" ;
VAL_ 2566899694 DayDrivTimeShift1Flag 0 "No resting period" 1 "At least one resting period" ;
VAL_ 2566899694 DayDrivTimeShift2 32766 "Error" 32767 "Not Available" ;
VAL_ 2566899694 DayDrivTimeShift2Flag 0 "No resting period" 1 "At least one resting period" ;
VAL_ 2566899694 DayDrivTimeShift3 32766 "Error" 32767 "Not Available" ;
VAL_ 2566899694 DayDrivTimeShift3Flag 0 "No resting period" 1 "At least one resting period" ;
VAL_ 2566899694 DayDrivTimeShift4 32766 "Error" 32767 "Not Available" ;
VAL_ 2566899694 DayDrivTimeShift4Flag 0 "No resting period" 1 "At least one resting period" ;
VAL_ 2566899694 DayDrivTimeShift5 32766 "Error" 32767 "Not Available" ;
VAL_ 2566899694 DayDrivTimeShift5Flag 0 "No resting period" 1 "At least one resting period" ;
VAL_ 2566899694 DayDrivTimeShift6 32766 "Error" 32767 "Not Available" ;
VAL_ 2566899694 DayDrivTimeShift6Flag 0 "No resting period" 1 "At least one resting period" ;
VAL_ 2566899694 DayRestPer1 32766 "Error" 32767 "Not Available" ;
VAL_ 2566899694 DayRestPer1Flag 0 "No Unknown activities" 1 "At least 1 Unknown act period" ;
VAL_ 2566899694 DayRestPer2 32766 "Error" 32767 "Not Available" ;
VAL_ 2566899694 DayRestPer2Flag 0 "No Unknown activities" 1 "At least 1 Unknown act period" ;
VAL_ 2566899694 DayRestPer3 32766 "Error" 32767 "Not Available" ;
VAL_ 2566899694 DayRestPer3Flag 0 "No Unknown activities" 1 "At least 1 Unknown act period" ;
VAL_ 2566899694 DayRestPer4 32766 "Error" 32767 "Not Available" ;
VAL_ 2566899694 DayRestPer4Flag 0 "No Unknown activities" 1 "At least 1 Unknown act period" ;
VAL_ 2566899694 DayRestPer5 32766 "Error" 32767 "Not Available" ;
VAL_ 2566899694 DayRestPer5Flag 0 "No Unknown activities" 1 "At least 1 Unknown act period" ;
VAL_ 2566899694 DayRestPer6 32766 "Error" 32767 "Not Available" ;
VAL_ 2566899694 DayRestPer6Flag 0 "No Unknown activities" 1 "At least 1 Unknown act period" ;
VAL_ 2566899694 DayRestPer7 32766 "Error" 32767 "Not Available" ;
VAL_ 2566899694 DayRestPer7Flag 0 "No Unknown activities" 1 "At least 1 Unknown act period" ;
